VERSION "j1939-2025-03-v2.4-light"

NS_ :

BS_:

BU_:

BO_ 2561146622 AUXIO2: 8 Vector__XXX
 SG_ AuxiliaryIO17 : 6|2@1+ (1,0) [0|3] "" Vector__XXX
 SG_ AuxiliaryIO18 : 4|2@1+ (1,0) [0|3] "" Vector__XXX
 SG_ AuxiliaryIO19 : 2|2@1+ (1,0) [0|3] "" Vector__XXX
 SG_ AuxiliaryIO20 : 0|2@1+ (1,0) [0|3] "" Vector__XXX
 SG_ AuxiliaryIO21 : 14|2@1+ (1,0) [0|3] "" Vector__XXX
 SG_ AuxiliaryIO22 : 12|2@1+ (1,0) [0|3] "" Vector__XXX
 SG_ AuxiliaryIO23 : 10|2@1+ (1,0) [0|3] "" Vector__XXX
 SG_ AuxiliaryIO24 : 8|2@1+ (1,0) [0|3] "" Vector__XXX
 SG_ AuxiliaryIO25 : 22|2@1+ (1,0) [0|3] "" Vector__XXX
 SG_ AuxiliaryIO26 : 20|2@1+ (1,0) [0|3] "" Vector__XXX
 SG_ AuxiliaryIO27 : 18|2@1+ (1,0) [0|3] "" Vector__XXX
 SG_ AuxiliaryIO28 : 16|2@1+ (1,0) [0|3] "" Vector__XXX
 SG_ AuxiliaryIO29 : 30|2@1+ (1,0) [0|3] "" Vector__XXX
 SG_ AuxiliaryIO30 : 28|2@1+ (1,0) [0|3] "" Vector__XXX
 SG_ AuxiliaryIO31 : 26|2@1+ (1,0) [0|3] "" Vector__XXX
 SG_ AuxiliaryIO32 : 24|2@1+ (1,0) [0|3] "" Vector__XXX
 SG_ AuxiliaryIO33 : 38|2@1+ (1,0) [0|3] "" Vector__XXX
 SG_ AuxiliaryIO34 : 36|2@1+ (1,0) [0|3] "" Vector__XXX
 SG_ AuxiliaryIO35 : 34|2@1+ (1,0) [0|3] "" Vector__XXX
 SG_ AuxiliaryIO36 : 32|2@1+ (1,0) [0|3] "" Vector__XXX
 SG_ AuxiliaryIO37 : 46|2@1+ (1,0) [0|3] "" Vector__XXX
 SG_ AuxiliaryIO38 : 44|2@1+ (1,0) [0|3] "" Vector__XXX
 SG_ AuxiliaryIO39 : 42|2@1+ (1,0) [0|3] "" Vector__XXX
 SG_ AuxiliaryIO40 : 40|2@1+ (1,0) [0|3] "" Vector__XXX
 SG_ AuxiliaryIO41 : 54|2@1+ (1,0) [0|3] "" Vector__XXX
 SG_ AuxiliaryIO42 : 52|2@1+ (1,0) [0|3] "" Vector__XXX
 SG_ AuxiliaryIO43 : 50|2@1+ (1,0) [0|3] "" Vector__XXX
 SG_ AuxiliaryIO44 : 48|2@1+ (1,0) [0|3] "" Vector__XXX
 SG_ AuxiliaryIO45 : 62|2@1+ (1,0) [0|3] "" Vector__XXX
 SG_ AuxiliaryIO46 : 60|2@1+ (1,0) [0|3] "" Vector__XXX
 SG_ AuxiliaryIO47 : 58|2@1+ (1,0) [0|3] "" Vector__XXX
 SG_ AuxiliaryIO48 : 56|2@1+ (1,0) [0|3] "" Vector__XXX

BO_ 2561212158 DISP1: 8 Vector__XXX
 SG_ TextDisplayIndex : 16|8@1+ (1,0) [0|200] "count" Vector__XXX
 SG_ TextDisplayInstructions : 0|4@1+ (1,0) [0|15] "" Vector__XXX

BO_ 2561277694 FLIC: 8 Vector__XXX
 SG_ CurrentRegion : 8|16@1+ (1,0) [0|255] "" Vector__XXX
 SG_ CurrentSubRegion : 24|24@1+ (1,0) [0|255] "" Vector__XXX
 SG_ LnDprtrWrnngEnlCmmnd : 0|2@1+ (1,0) [0|3] "" Vector__XXX
 SG_ LaneKeepingAssistEnableCommand : 2|2@1+ (1,0) [0|3] "" Vector__XXX
 SG_ LaneCenteringEnableCommand : 4|2@1+ (1,0) [0|3] "" Vector__XXX
 SG_ RqstdAtvStrngDrvrPrfrnMd : 48|3@1+ (1,0) [0|7] "" Vector__XXX

BO_ 2561605374 TPRS: 8 Vector__XXX
 SG_ ReferenceTirePressureSetting : 8|8@1+ (8,0) [0|2000] "kPa" Vector__XXX
 SG_ TireLocation : 0|8@1+ (1,0) [0|250] "" Vector__XXX

BO_ 2563768062 CTL: 8 Vector__XXX
 SG_ EngnSpdLmtRqstMnmmCntns : 0|8@1+ (32,0) [0|8000] "rpm" Vector__XXX
 SG_ EngnSpdLmtRqstMxmmCntns : 8|8@1+ (32,0) [0|8000] "rpm" Vector__XXX
 SG_ EngnTrqLmtRqstMnmmCntns : 16|8@1+ (1,-125) [0|125] "%" Vector__XXX
 SG_ EngnTrqLmtRqstMxmmCntns : 24|8@1+ (1,-125) [0|125] "%" Vector__XXX
 SG_ MnmmCntnsRtrdrSpdLmtRqst : 32|8@1+ (32,0) [0|8000] "rpm" Vector__XXX
 SG_ MnmmCntnsRtrdrTrqLmtRqst : 48|8@1+ (1,-125) [-125|0] "%" Vector__XXX
 SG_ MxmmCntnsRtrdrSpdLmtRqst : 40|8@1+ (32,0) [0|8000] "rpm" Vector__XXX
 SG_ MxmmCntnsRtrdrTrqLmtRqst : 56|8@1+ (1,-125) [-125|0] "%" Vector__XXX

BO_ 2563833598 CL: 8 Vector__XXX
 SG_ IlluminationBrightnessPercent : 0|8@1+ (0.4,0) [0|100] "%" Vector__XXX
 SG_ SwthBklghtIllmntnBrghtnssPrnt : 8|8@1+ (0.4,0) [0|100] "%" Vector__XXX
 SG_ SwthIndtnIllmntnBrghtnssPrnt : 16|8@1+ (0.4,0) [0|100] "%" Vector__XXX
 SG_ OprtrDsrdDsplMdCmmnd1 : 24|4@1+ (1,0) [0|15] "" Vector__XXX
 SG_ OprtrDsrdDsplMdCmmnd2 : 28|4@1+ (1,0) [0|15] "" Vector__XXX
 SG_ CabDomeLight1Command : 32|8@1+ (0.4,0) [0|100] "%" Vector__XXX
 SG_ CabDomeLight2Command : 40|8@1+ (0.4,0) [0|100] "%" Vector__XXX

BO_ 2564161278 TDA: 8 Vector__XXX
 SG_ AdjustDay : 32|8@1+ (0.25,0) [0.25|31.75] "days" Vector__XXX
 SG_ AdjustHours : 16|8@1+ (1,0) [0|23] "h" Vector__XXX
 SG_ AdjustLocalHourOffset : 56|8@1+ (1,-125) [-24|23] "h" Vector__XXX
 SG_ AdjustLocalMinuteOffset : 48|8@1+ (1,-125) [-59|59] "min" Vector__XXX
 SG_ AdjustMinutes : 8|8@1+ (1,0) [0|59] "min" Vector__XXX
 SG_ AdjustMonth : 24|8@1+ (1,0) [1|12] "month" Vector__XXX
 SG_ AdjustSeconds : 0|8@1+ (0.25,0) [0|59.75] "s" Vector__XXX
 SG_ AdjustYear : 40|8@1+ (1,1985) [1985|2235] "year" Vector__XXX

BO_ 2564882174 CM1: 8 Vector__XXX
 SG_ AftrtrtmntRgnrtnFrSwth : 42|2@1+ (1,0) [0|3] "" Vector__XXX
 SG_ AftrtrtmntRgnrtnInhtSwth : 40|2@1+ (1,0) [0|3] "" Vector__XXX
 SG_ AtmtGrShftngEnlSwth : 44|2@1+ (1,0) [0|3] "" Vector__XXX
 SG_ AuxiliaryHeaterModeRequest : 48|4@1+ (1,0) [0|15] "" Vector__XXX
 SG_ AxlrHtrClntPmpRqst : 24|2@1+ (1,0) [0|3] "" Vector__XXX
 SG_ BatteryMainSwitchHoldRequest : 26|2@1+ (1,0) [0|3] "" Vector__XXX
 SG_ CabInteriorTemperatureCommand : 8|16@1+ (0.03125,-273) [-273|1734.96875] "degC" Vector__XXX
 SG_ EngineFan1RequestedPercentSpeed : 0|8@1+ (0.4,0) [0|100] "%" Vector__XXX
 SG_ EngnAtmtStrtEnlSwth : 46|2@1+ (1,0) [0|3] "" Vector__XXX
 SG_ OperatorSeatDirectionSwitch : 28|2@1+ (1,0) [0|3] "" Vector__XXX
 SG_ ParkBrakeCommand : 32|2@1+ (1,0) [0|3] "" Vector__XXX
 SG_ RequestCabZoneHeating : 54|2@1+ (1,0) [0|3] "" Vector__XXX
 SG_ RequestEngineZoneHeating : 52|2@1+ (1,0) [0|3] "" Vector__XXX
 SG_ SeatBeltSwitch : 30|2@1+ (1,0) [0|3] "" Vector__XXX
 SG_ SltdMxmmVhlSpdLmt : 56|8@1+ (1,0) [0|250] "count" Vector__XXX
 SG_ VhlLmtngSpdGvrnrDrmntSwth : 34|2@1+ (1,0) [0|3] "" Vector__XXX
 SG_ VhlLmtngSpdGvrnrEnlSwth : 38|2@1+ (1,0) [0|3] "" Vector__XXX
 SG_ VhlLmtngSpdGvrnrInrmntSwth : 36|2@1+ (1,0) [0|3] "" Vector__XXX

BO_ 2565865982 EBC1: 8 Vector__XXX
 SG_ AbsFullyOperational : 40|2@1+ (1,0) [0|3] "" Vector__XXX
 SG_ AbsOffRoadSwitch : 16|2@1+ (1,0) [0|3] "" Vector__XXX
 SG_ AcceleratorInterlockSwitch : 24|2@1+ (1,0) [0|3] "" Vector__XXX
 SG_ AntiLockBrakingAbsActive : 4|2@1+ (1,0) [0|3] "" Vector__XXX
 SG_ AsrBrakeControlActive : 2|2@1+ (1,0) [0|3] "" Vector__XXX
 SG_ AsrEngineControlActive : 0|2@1+ (1,0) [0|3] "" Vector__XXX
 SG_ AsrHillHolderSwitch : 20|2@1+ (1,0) [0|3] "" Vector__XXX
 SG_ AsrOffRoadSwitch : 18|2@1+ (1,0) [0|3] "" Vector__XXX
 SG_ AtcAsrInformationSignal : 46|2@1+ (1,0) [0|3] "" Vector__XXX
 SG_ BrakePedalPosition : 8|8@1+ (0.4,0) [0|100] "%" Vector__XXX
 SG_ EbsBrakeSwitch : 6|2@1+ (1,0) [0|3] "" Vector__XXX
 SG_ EbsRedWarningSignal : 42|2@1+ (1,0) [0|3] "" Vector__XXX
 SG_ EngineAuxiliaryShutdownSwitch : 28|2@1+ (1,0) [0|3] "" Vector__XXX
 SG_ EngineDerateSwitch : 26|2@1+ (1,0) [0|3] "" Vector__XXX
 SG_ EngineRetarderSelection : 32|8@1+ (0.4,0) [0|100] "%" Vector__XXX
 SG_ HaltBrakeSwitch : 58|2@1+ (1,0) [0|3] "" Vector__XXX
 SG_ RailroadModeSwitch : 56|2@1+ (1,0) [0|3] "" Vector__XXX
 SG_ RemoteAcceleratorEnableSwitch : 30|2@1+ (1,0) [0|3] "" Vector__XXX
 SG_ TractionControlOverrideSwitch : 22|2@1+ (1,0) [0|3] "" Vector__XXX
 SG_ TrailerAbsStatus : 60|2@1+ (1,0) [0|3] "" Vector__XXX
 SG_ AsEsAmrWrnngSgnlPwrdVhl : 44|2@1+ (1,0) [0|3] "" Vector__XXX
 SG_ SrAddrssOfCntrllngDvFrBrkCntrl : 48|8@1+ (1,0) [0|253] "sourceadr" Vector__XXX
 SG_ TrtrMntdTrlrAsWrnngSgnl : 62|2@1+ (1,0) [0|3] "" Vector__XXX

BO_ 2565867006 ETC2: 8 Vector__XXX
 SG_ TransmissionActualGearRatio : 8|16@1+ (0.001,0) [0|64.255] "" Vector__XXX
 SG_ TransmissionCurrentGear : 24|8@1+ (1,-125) [-125|125] "gear value" Vector__XXX
 SG_ TransmissionCurrentRange : 48|16@1+ (1,0) [0|255] "" Vector__XXX
 SG_ TransmissionRequestedRange : 32|16@1+ (1,0) [0|255] "" Vector__XXX
 SG_ TransmissionSelectedGear : 0|8@1+ (1,-125) [-125|125] "gear value" Vector__XXX

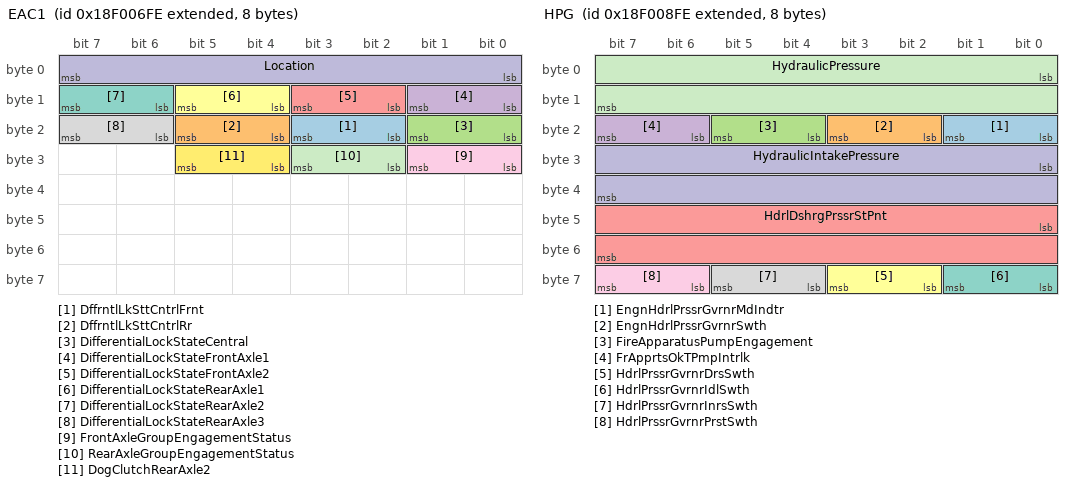
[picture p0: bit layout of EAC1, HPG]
BO_ 2565867262 EAC1: 8 Vector__XXX
 SG_ DffrntlLkSttCntrlFrnt : 18|2@1+ (1,0) [0|3] "" Vector__XXX
 SG_ DffrntlLkSttCntrlRr : 20|2@1+ (1,0) [0|3] "" Vector__XXX
 SG_ DifferentialLockStateCentral : 16|2@1+ (1,0) [0|3] "" Vector__XXX
 SG_ DifferentialLockStateFrontAxle1 : 8|2@1+ (1,0) [0|3] "" Vector__XXX
 SG_ DifferentialLockStateFrontAxle2 : 10|2@1+ (1,0) [0|3] "" Vector__XXX
 SG_ DifferentialLockStateRearAxle1 : 12|2@1+ (1,0) [0|3] "" Vector__XXX
 SG_ DifferentialLockStateRearAxle2 : 14|2@1+ (1,0) [0|3] "" Vector__XXX
 SG_ DifferentialLockStateRearAxle3 : 22|2@1+ (1,0) [0|3] "" Vector__XXX
 SG_ FrontAxleGroupEngagementStatus : 24|2@1+ (1,0) [0|3] "" Vector__XXX
 SG_ Location : 0|8@1+ (1,0) [0|250] "" Vector__XXX
 SG_ RearAxleGroupEngagementStatus : 26|2@1+ (1,0) [0|3] "" Vector__XXX
 SG_ DogClutchRearAxle2 : 28|2@1+ (1,0) [0|3] "" Vector__XXX

BO_ 2565867774 HPG: 8 Vector__XXX
 SG_ EngnHdrlPrssrGvrnrMdIndtr : 16|2@1+ (1,0) [0|3] "" Vector__XXX
 SG_ EngnHdrlPrssrGvrnrSwth : 18|2@1+ (1,0) [0|3] "" Vector__XXX
 SG_ FireApparatusPumpEngagement : 20|2@1+ (1,0) [0|3] "" Vector__XXX
 SG_ FrApprtsOkTPmpIntrlk : 22|2@1+ (1,0) [0|3] "" Vector__XXX
 SG_ HdrlDshrgPrssrStPnt : 40|16@1+ (2,0) [0|128510] "kPa" Vector__XXX
 SG_ HdrlPrssrGvrnrDrsSwth : 58|2@1+ (1,0) [0|3] "" Vector__XXX
 SG_ HdrlPrssrGvrnrIdlSwth : 56|2@1+ (1,0) [0|3] "" Vector__XXX
 SG_ HdrlPrssrGvrnrInrsSwth : 60|2@1+ (1,0) [0|3] "" Vector__XXX
 SG_ HdrlPrssrGvrnrPrstSwth : 62|2@1+ (1,0) [0|3] "" Vector__XXX
 SG_ HydraulicIntakePressure : 24|16@1+ (0.0001220703125,-1) [-1|6.8436279296875] "MPa" Vector__XXX
 SG_ HydraulicPressure : 0|16@1+ (2,0) [0|128510] "kPa" Vector__XXX

BO_ 2565868030 VDC2: 8 Vector__XXX
 SG_ LateralAcceleration : 40|16@1+ (0.00048828125,-15.687) [-15.687|15.68751171875] "m/(s*s)" Vector__XXX
 SG_ LongitudinalAcceleration : 56|8@1+ (0.1,-12.5) [-12.5|12.5] "m/(s*s)" Vector__XXX
 SG_ SteeringWheelAngle : 0|16@1+ (0.0009765625,-31.374) [-31.374|31.3750234375] "rad" Vector__XXX
 SG_ SteeringWheelAngleSensorType : 22|2@1+ (1,0) [0|3] "" Vector__XXX
 SG_ SteeringWheelTurnCounter : 16|6@1+ (1,-32) [-10|10] "turn" Vector__XXX
 SG_ YawRate : 24|16@1+ (0.0001220703125,-3.92) [-3.92|3.9236279296875] "rad/s" Vector__XXX

BO_ 2565868542 ESC1: 8 Vector__XXX
 SG_ ActualInnerWheelSteeringAngle : 0|16@1+ (0.00390625,-125) [-125|125.99609375] "deg" Vector__XXX
 SG_ AxleLocation : 16|8@1+ (1,0) [0|250] "" Vector__XXX
 SG_ StatusOfSteeringAxle : 24|4@1+ (1,0) [0|15] "" Vector__XXX
 SG_ SteeringType : 32|4@1+ (1,0) [0|15] "" Vector__XXX
 SG_ StrlLftAxlLwrngInht : 28|2@1+ (1,0) [0|3] "" Vector__XXX
 SG_ TypeOfSteeringForces : 36|4@1+ (1,0) [0|15] "" Vector__XXX
 SG_ TypeOfSteeringTransmission : 40|4@1+ (1,0) [0|15] "" Vector__XXX

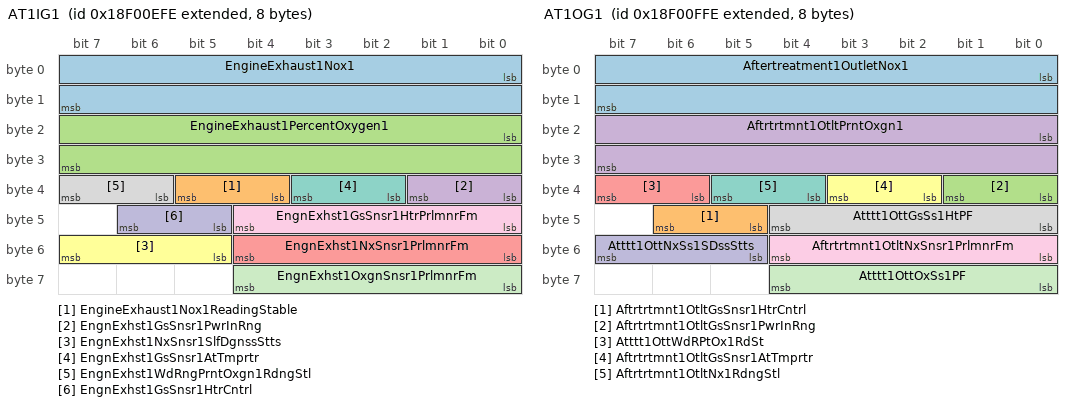
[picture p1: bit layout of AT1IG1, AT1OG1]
BO_ 2565869310 AT1IG1: 8 Vector__XXX
 SG_ EngineExhaust1Nox1 : 0|16@1+ (0.05,-200) [-200|3012.75] "ppm" Vector__XXX
 SG_ EngineExhaust1Nox1ReadingStable : 36|2@1+ (1,0) [0|3] "" Vector__XXX
 SG_ EngineExhaust1PercentOxygen1 : 16|16@1+ (0.000514,-12) [-12|21.02707] "%" Vector__XXX
 SG_ EngnExhst1GsSnsr1PwrInRng : 32|2@1+ (1,0) [0|3] "" Vector__XXX
 SG_ EngnExhst1NxSnsr1PrlmnrFm : 48|5@1+ (1,0) [0|31] "" Vector__XXX
 SG_ EngnExhst1NxSnsr1SlfDgnssStts : 53|3@1+ (1,0) [0|7] "" Vector__XXX
 SG_ EngnExhst1GsSnsr1AtTmprtr : 34|2@1+ (1,0) [0|3] "" Vector__XXX
 SG_ EngnExhst1WdRngPrntOxgn1RdngStl : 38|2@1+ (1,0) [0|3] "" Vector__XXX
 SG_ EngnExhst1GsSnsr1HtrPrlmnrFm : 40|5@1+ (1,0) [0|31] "" Vector__XXX
 SG_ EngnExhst1GsSnsr1HtrCntrl : 45|2@1+ (1,0) [0|3] "" Vector__XXX
 SG_ EngnExhst1OxgnSnsr1PrlmnrFm : 56|5@1+ (1,0) [0|31] "" Vector__XXX

BO_ 2565869566 AT1OG1: 8 Vector__XXX
 SG_ Aftertreatment1OutletNox1 : 0|16@1+ (0.05,-200) [-200|3012.75] "ppm" Vector__XXX
 SG_ Aftrtrtmnt1OtltGsSnsr1HtrCntrl : 45|2@1+ (1,0) [0|3] "" Vector__XXX
 SG_ Aftrtrtmnt1OtltGsSnsr1PwrInRng : 32|2@1+ (1,0) [0|3] "" Vector__XXX
 SG_ Aftrtrtmnt1OtltPrntOxgn1 : 16|16@1+ (0.000514,-12) [-12|21.02707] "%" Vector__XXX
 SG_ Atttt1OttWdRPtOx1RdSt : 38|2@1+ (1,0) [0|3] "" Vector__XXX
 SG_ Aftrtrtmnt1OtltGsSnsr1AtTmprtr : 34|2@1+ (1,0) [0|3] "" Vector__XXX
 SG_ Aftrtrtmnt1OtltNx1RdngStl : 36|2@1+ (1,0) [0|3] "" Vector__XXX
 SG_ Atttt1OttGsSs1HtPF : 40|5@1+ (1,0) [0|31] "" Vector__XXX
 SG_ Aftrtrtmnt1OtltNxSnsr1PrlmnrFm : 48|5@1+ (1,0) [0|31] "" Vector__XXX
 SG_ Atttt1OttNxSs1SDssStts : 53|3@1+ (1,0) [0|7] "" Vector__XXX
 SG_ Atttt1OttOxSs1PF : 56|5@1+ (1,0) [0|31] "" Vector__XXX

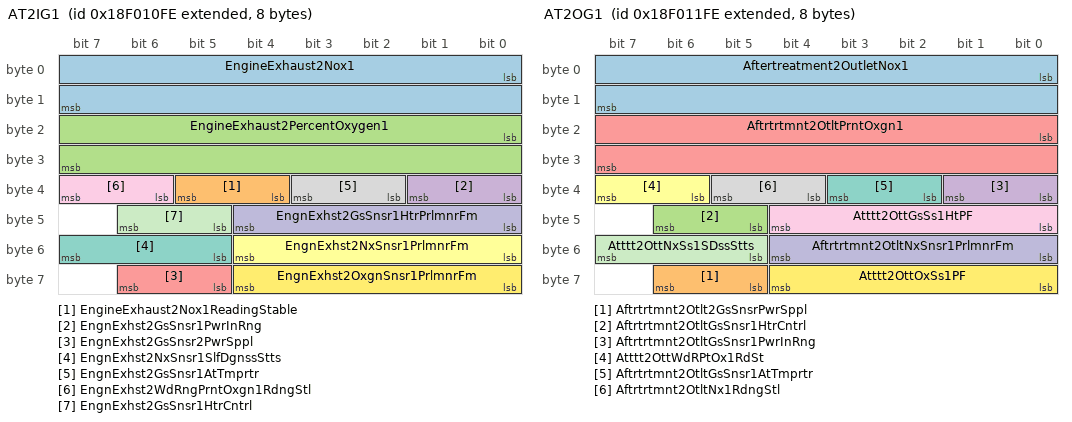
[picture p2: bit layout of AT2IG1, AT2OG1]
BO_ 2565869822 AT2IG1: 8 Vector__XXX
 SG_ EngineExhaust2Nox1 : 0|16@1+ (0.05,-200) [-200|3012.75] "ppm" Vector__XXX
 SG_ EngineExhaust2Nox1ReadingStable : 36|2@1+ (1,0) [0|3] "" Vector__XXX
 SG_ EngineExhaust2PercentOxygen1 : 16|16@1+ (0.000514,-12) [-12|21.02707] "%" Vector__XXX
 SG_ EngnExhst2GsSnsr1PwrInRng : 32|2@1+ (1,0) [0|3] "" Vector__XXX
 SG_ EngnExhst2GsSnsr2PwrSppl : 61|2@1+ (1,0) [0|3] "" Vector__XXX
 SG_ EngnExhst2NxSnsr1PrlmnrFm : 48|5@1+ (1,0) [0|31] "" Vector__XXX
 SG_ EngnExhst2NxSnsr1SlfDgnssStts : 53|3@1+ (1,0) [0|7] "" Vector__XXX
 SG_ EngnExhst2GsSnsr1AtTmprtr : 34|2@1+ (1,0) [0|3] "" Vector__XXX
 SG_ EngnExhst2WdRngPrntOxgn1RdngStl : 38|2@1+ (1,0) [0|3] "" Vector__XXX
 SG_ EngnExhst2GsSnsr1HtrPrlmnrFm : 40|5@1+ (1,0) [0|31] "" Vector__XXX
 SG_ EngnExhst2GsSnsr1HtrCntrl : 45|2@1+ (1,0) [0|3] "" Vector__XXX
 SG_ EngnExhst2OxgnSnsr1PrlmnrFm : 56|5@1+ (1,0) [0|31] "" Vector__XXX

BO_ 2565870078 AT2OG1: 8 Vector__XXX
 SG_ Aftertreatment2OutletNox1 : 0|16@1+ (0.05,-200) [-200|3012.75] "ppm" Vector__XXX
 SG_ Aftrtrtmnt2Otlt2GsSnsrPwrSppl : 61|2@1+ (1,0) [0|3] "" Vector__XXX
 SG_ Aftrtrtmnt2OtltGsSnsr1HtrCntrl : 45|2@1+ (1,0) [0|3] "" Vector__XXX
 SG_ Aftrtrtmnt2OtltGsSnsr1PwrInRng : 32|2@1+ (1,0) [0|3] "" Vector__XXX
 SG_ Aftrtrtmnt2OtltPrntOxgn1 : 16|16@1+ (0.000514,-12) [-12|21.02707] "%" Vector__XXX
 SG_ Atttt2OttWdRPtOx1RdSt : 38|2@1+ (1,0) [0|3] "" Vector__XXX
 SG_ Aftrtrtmnt2OtltGsSnsr1AtTmprtr : 34|2@1+ (1,0) [0|3] "" Vector__XXX
 SG_ Aftrtrtmnt2OtltNx1RdngStl : 36|2@1+ (1,0) [0|3] "" Vector__XXX
 SG_ Atttt2OttGsSs1HtPF : 40|5@1+ (1,0) [0|31] "" Vector__XXX
 SG_ Aftrtrtmnt2OtltNxSnsr1PrlmnrFm : 48|5@1+ (1,0) [0|31] "" Vector__XXX
 SG_ Atttt2OttNxSs1SDssStts : 53|3@1+ (1,0) [0|7] "" Vector__XXX
 SG_ Atttt2OttOxSs1PF : 56|5@1+ (1,0) [0|31] "" Vector__XXX

BO_ 2565870334 FWSS1: 8 Vector__XXX
 SG_ FifthWheelDrawbarForce : 16|16@1+ (10,-320000) [-320000|322550] "N" Vector__XXX
 SG_ FifthWheelRollMoment : 32|16@1+ (10,-320000) [-320000|322550] "N" Vector__XXX
 SG_ FifthWheelRollWarningIndicator : 48|2@1+ (1,0) [0|3] "" Vector__XXX
 SG_ FifthWheelVerticalForce : 0|16@1+ (5,0) [0|321275] "N" Vector__XXX

BO_ 2565873150 SAS: 8 Vector__XXX
 SG_ MessageChecksum : 60|4@1+ (1,0) [0|15] "count" Vector__XXX
 SG_ MessageCounter : 56|4@1+ (1,0) [0|15] "count" Vector__XXX
 SG_ SteeringAngleSensorActiveMode : 48|2@1+ (1,0) [0|3] "" Vector__XXX
 SG_ SteeringAngleSensorCalibrated : 50|2@1+ (1,0) [0|3] "" Vector__XXX
 SG_ SteeringWheelAngle : 0|16@1+ (0.0009765625,-31.374) [-31.374|31.3750234375] "rad" Vector__XXX
 SG_ SteeringWheelAngleRange : 32|16@1+ (0.0009765625,-31.374) [0|31.374] "rad" Vector__XXX
 SG_ SteeringWheelAngleRangeCounter : 16|6@1+ (1,-32) [-32|29] "range" Vector__XXX
 SG_ StrngWhlAnglRngCntrTp : 22|2@1+ (1,0) [0|3] "" Vector__XXX

BO_ 2565874174 ESSI1: 8 Vector__XXX
 SG_ EngineSpeed1 : 0|16@1+ (0.5,0) [0|32127.5] "rpm" Vector__XXX
 SG_ EngineSpeed2 : 16|16@1+ (0.5,0) [0|32127.5] "rpm" Vector__XXX
 SG_ EngineSpeed3 : 32|16@1+ (0.5,0) [0|32127.5] "rpm" Vector__XXX
 SG_ EngnSpdSnsr1TmngPttrnStts : 54|2@1+ (1,0) [0|3] "" Vector__XXX
 SG_ EngnSpdSnsr2TmngPttrnStts : 52|2@1+ (1,0) [0|3] "" Vector__XXX
 SG_ EngnSpdSnsr3TmngPttrnStts : 50|2@1+ (1,0) [0|3] "" Vector__XXX

BO_ 2565877502 ETCC1: 8 Vector__XXX
 SG_ EExstB1PssRtCtCd : 32|16@1+ (0.0025,0) [0|100] "%" Vector__XXX
 SG_ EngnTrhrgrWstgtAttr1Cmmnd : 0|16@1+ (0.0025,0) [0|160.6375] "%" Vector__XXX
 SG_ EngnTrhrgrWstgtAttr2Cmmnd : 16|16@1+ (0.0025,0) [0|160.6375] "%" Vector__XXX
 SG_ ETCpssBwAtt1Cd : 48|16@1+ (0.0025,0) [0|100] "%" Vector__XXX

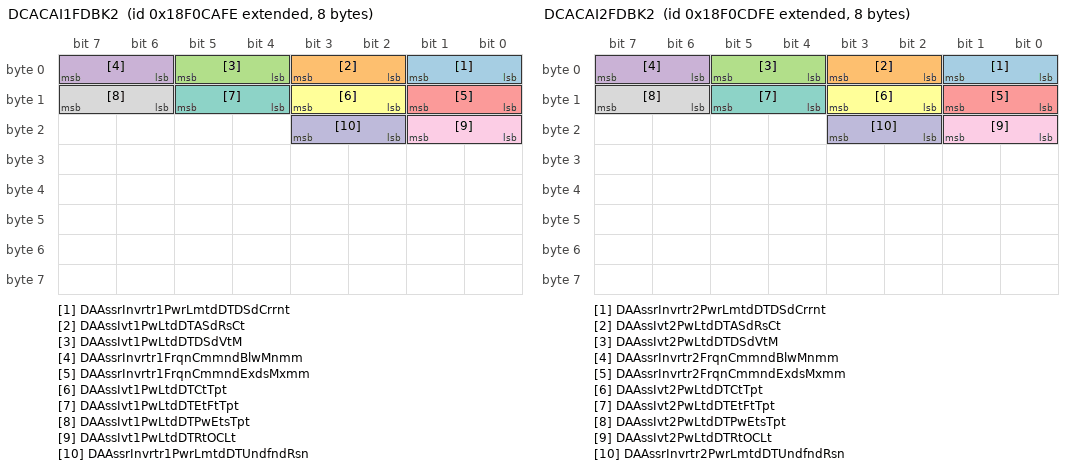
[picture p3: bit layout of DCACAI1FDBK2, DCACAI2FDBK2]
BO_ 2565917438 DCACAI1FDBK2: 8 Vector__XXX
 SG_ DAAssrInvrtr1PwrLmtdDTDSdCrrnt : 0|2@1+ (1,0) [0|3] "" Vector__XXX
 SG_ DAAssIvt1PwLtdDTASdRsCt : 2|2@1+ (1,0) [0|3] "" Vector__XXX
 SG_ DAAssIvt1PwLtdDTDSdVtM : 4|2@1+ (1,0) [0|3] "" Vector__XXX
 SG_ DAAssrInvrtr1FrqnCmmndBlwMnmm : 6|2@1+ (1,0) [0|3] "" Vector__XXX
 SG_ DAAssrInvrtr1FrqnCmmndExdsMxmm : 8|2@1+ (1,0) [0|3] "" Vector__XXX
 SG_ DAAssIvt1PwLtdDTCtTpt : 10|2@1+ (1,0) [0|3] "" Vector__XXX
 SG_ DAAssIvt1PwLtdDTEtFtTpt : 12|2@1+ (1,0) [0|3] "" Vector__XXX
 SG_ DAAssIvt1PwLtdDTPwEtsTpt : 14|2@1+ (1,0) [0|3] "" Vector__XXX
 SG_ DAAssIvt1PwLtdDTRtOCLt : 16|2@1+ (1,0) [0|3] "" Vector__XXX
 SG_ DAAssrInvrtr1PwrLmtdDTUndfndRsn : 18|2@1+ (1,0) [0|3] "" Vector__XXX

BO_ 2565918206 DCACAI2FDBK2: 8 Vector__XXX
 SG_ DAAssrInvrtr2PwrLmtdDTDSdCrrnt : 0|2@1+ (1,0) [0|3] "" Vector__XXX
 SG_ DAAssIvt2PwLtdDTASdRsCt : 2|2@1+ (1,0) [0|3] "" Vector__XXX
 SG_ DAAssIvt2PwLtdDTDSdVtM : 4|2@1+ (1,0) [0|3] "" Vector__XXX
 SG_ DAAssrInvrtr2FrqnCmmndBlwMnmm : 6|2@1+ (1,0) [0|3] "" Vector__XXX
 SG_ DAAssrInvrtr2FrqnCmmndExdsMxmm : 8|2@1+ (1,0) [0|3] "" Vector__XXX
 SG_ DAAssIvt2PwLtdDTCtTpt : 10|2@1+ (1,0) [0|3] "" Vector__XXX
 SG_ DAAssIvt2PwLtdDTEtFtTpt : 12|2@1+ (1,0) [0|3] "" Vector__XXX
 SG_ DAAssIvt2PwLtdDTPwEtsTpt : 14|2@1+ (1,0) [0|3] "" Vector__XXX
 SG_ DAAssIvt2PwLtdDTRtOCLt : 16|2@1+ (1,0) [0|3] "" Vector__XXX
 SG_ DAAssrInvrtr2PwrLmtdDTUndfndRsn : 18|2@1+ (1,0) [0|3] "" Vector__XXX

BO_ 2565920510 DCACAI1CMD: 8 Vector__XXX
 SG_ DAAssrInvrtr1DvMxmmFrqn : 0|8@1+ (1,0) [0|250] "Hz" Vector__XXX
 SG_ DAAssrInvrtr1DvMnmmFrqn : 8|8@1+ (1,0) [0|250] "Hz" Vector__XXX
 SG_ DAAssrInvrtr1DvRtdFrqn : 16|8@1+ (1,0) [0|250] "Hz" Vector__XXX
 SG_ DAAssrInvrtr1DvRtdRmsVltg : 24|8@1+ (2,0) [0|500] "V" Vector__XXX
 SG_ DAAssrInvrtr1DvFrqnRtOfChngLmt : 32|8@1+ (2,0) [0|500] "Hz/s" Vector__XXX
 SG_ DAAssrInvrtr1FrqnCmmnd : 40|8@1+ (1,0) [0|250] "Hz" Vector__XXX
 SG_ DAAssrInvrtr1Dv1Stts : 48|3@1+ (1,0) [0|7] "" Vector__XXX
 SG_ DAAssrInvrtr1Dv2Stts : 51|3@1+ (1,0) [0|7] "" Vector__XXX
 SG_ DAAssrInvrtr1OprtnlCmmnd : 54|2@1+ (1,0) [0|3] "" Vector__XXX
 SG_ DAAssIvt1ASdMtSttRsVtRqst : 56|8@1+ (2,0) [0|500] "V" Vector__XXX

BO_ 2565920766 DCACAI1FDBK: 8 Vector__XXX
 SG_ DcAcAccessoryInverter1Frequency : 0|8@1+ (1,0) [0|250] "Hz" Vector__XXX
 SG_ DAAssrInvrtr1ASdRmsVltg : 8|8@1+ (2,0) [0|500] "V" Vector__XXX
 SG_ DAAssrInvrtr1ASdPwr : 16|8@1+ (0.1,0) [0|25] "kW" Vector__XXX
 SG_ DAAssrInvrtr1ASdRmsCrrnt : 24|16@1+ (0.03125,0) [0|2007.96875] "A" Vector__XXX
 SG_ DAAssrInvrtr1OprtnlStts : 48|3@1+ (1,0) [0|7] "" Vector__XXX
 SG_ DAAssrInvrtr1LdshdRqst : 51|2@1+ (1,0) [0|3] "" Vector__XXX
 SG_ DAAssrInvrtr1HvlStts : 53|2@1+ (1,0) [0|3] "" Vector__XXX

BO_ 2565921534 DCACAI2CMD: 8 Vector__XXX
 SG_ DAAssrInvrtr2DvMxmmFrqn : 0|8@1+ (1,0) [0|250] "Hz" Vector__XXX
 SG_ DAAssrInvrtr2DvMnmmFrqn : 8|8@1+ (1,0) [0|250] "Hz" Vector__XXX
 SG_ DAAssrInvrtr2DvRtdFrqn : 16|8@1+ (1,0) [0|250] "Hz" Vector__XXX
 SG_ DAAssrInvrtr2DvRtdRmsVltg : 24|8@1+ (2,0) [0|500] "V" Vector__XXX
 SG_ DAAssrInvrtr2DvFrqnRtOfChngLmt : 32|8@1+ (2,0) [0|500] "Hz/s" Vector__XXX
 SG_ DAAssrInvrtr2FrqnCmmnd : 40|8@1+ (1,0) [0|250] "Hz" Vector__XXX
 SG_ DAAssrInvrtr2Dv1Stts : 48|3@1+ (1,0) [0|7] "" Vector__XXX
 SG_ DAAssrInvrtr2Dv2Stts : 51|3@1+ (1,0) [0|7] "" Vector__XXX
 SG_ DAAssrInvrtr2OprtnlCmmnd : 54|2@1+ (1,0) [0|3] "" Vector__XXX
 SG_ DAAssIvt2ASdMtSttRsVtRqst : 56|8@1+ (2,0) [0|500] "V" Vector__XXX

BO_ 2565921790 DCACAI2FDBK: 8 Vector__XXX
 SG_ DcAcAccessoryInverter2Frequency : 0|8@1+ (1,0) [0|250] "Hz" Vector__XXX
 SG_ DAAssrInvrtr2ASdRmsVltg : 8|8@1+ (2,0) [0|500] "V" Vector__XXX
 SG_ DAAssrInvrtr2ASdPwr : 16|8@1+ (0.1,0) [0|25] "kW" Vector__XXX
 SG_ DAAssrInvrtr2ASdRmsCrrnt : 24|16@1+ (0.03125,0) [0|2007.96875] "A" Vector__XXX
 SG_ DAAssrInvrtr2OprtnlStts : 48|3@1+ (1,0) [0|7] "" Vector__XXX
 SG_ DAAssrInvrtr2LdshdRqst : 51|2@1+ (1,0) [0|3] "" Vector__XXX
 SG_ DAAssrInvrtr2HvlStts : 53|2@1+ (1,0) [0|3] "" Vector__XXX

BO_ 2565922558 DCACAI3CMD: 8 Vector__XXX
 SG_ DAAssrInvrtr3DvMxmmFrqn : 0|8@1+ (1,0) [0|250] "Hz" Vector__XXX
 SG_ DAAssrInvrtr3DvMnmmFrqn : 8|8@1+ (1,0) [0|250] "Hz" Vector__XXX
 SG_ DAAssrInvrtr3DvRtdFrqn : 16|8@1+ (1,0) [0|250] "Hz" Vector__XXX
 SG_ DAAssrInvrtr3DvRtdRmsVltg : 24|8@1+ (2,0) [0|500] "V" Vector__XXX
 SG_ DAAssrInvrtr3DvFrqnRtOfChngLmt : 32|8@1+ (2,0) [0|500] "Hz/s" Vector__XXX
 SG_ DAAssrInvrtr3FrqnCmmnd : 40|8@1+ (1,0) [0|250] "Hz" Vector__XXX
 SG_ DAAssrInvrtr3Dv1Stts : 48|3@1+ (1,0) [0|7] "" Vector__XXX
 SG_ DAAssrInvrtr3Dv2Stts : 51|3@1+ (1,0) [0|7] "" Vector__XXX
 SG_ DAAssrInvrtr3OprtnlCmmnd : 54|2@1+ (1,0) [0|3] "" Vector__XXX
 SG_ DAAssIvt3ASdMtSttRsVtRqst : 56|8@1+ (2,0) [0|500] "V" Vector__XXX

BO_ 2565922814 DCACAI3FDBK: 8 Vector__XXX
 SG_ DcAcAccessoryInverter3Frequency : 0|8@1+ (1,0) [0|250] "Hz" Vector__XXX
 SG_ DAAssrInvrtr3ASdRmsVltg : 8|8@1+ (2,0) [0|500] "V" Vector__XXX
 SG_ DAAssrInvrtr3ASdPwr : 16|8@1+ (0.1,0) [0|25] "kW" Vector__XXX
 SG_ DAAssrInvrtr3ASdRmsCrrnt : 24|16@1+ (0.03125,0) [0|2007.96875] "A" Vector__XXX
 SG_ DAAssrInvrtr3OprtnlStts : 48|3@1+ (1,0) [0|7] "" Vector__XXX
 SG_ DAAssrInvrtr3LdshdRqst : 51|2@1+ (1,0) [0|3] "" Vector__XXX
 SG_ DAAssrInvrtr3HvlStts : 53|2@1+ (1,0) [0|3] "" Vector__XXX

BO_ 2565923582 DCACAI4CMD: 8 Vector__XXX
 SG_ DAAssrInvrtr4DvMxmmFrqn : 0|8@1+ (1,0) [0|250] "Hz" Vector__XXX
 SG_ DAAssrInvrtr4DvMnmmFrqn : 8|8@1+ (1,0) [0|250] "Hz" Vector__XXX
 SG_ DAAssrInvrtr4DvRtdFrqn : 16|8@1+ (1,0) [0|250] "Hz" Vector__XXX
 SG_ DAAssrInvrtr4DvRtdRmsVltg : 24|8@1+ (2,0) [0|500] "V" Vector__XXX
 SG_ DAAssrInvrtr4DvFrqnRtOfChngLmt : 32|8@1+ (2,0) [0|500] "Hz/s" Vector__XXX
 SG_ DAAssrInvrtr4FrqnCmmnd : 40|8@1+ (1,0) [0|250] "Hz" Vector__XXX
 SG_ DAAssrInvrtr4Dv1Stts : 48|3@1+ (1,0) [0|7] "" Vector__XXX
 SG_ DAAssrInvrtr4Dv2Stts : 51|3@1+ (1,0) [0|7] "" Vector__XXX
 SG_ DAAssrInvrtr4OprtnlCmmnd : 54|2@1+ (1,0) [0|3] "" Vector__XXX
 SG_ DAAssIvt4ASdMtSttRsVtRqst : 56|8@1+ (2,0) [0|500] "V" Vector__XXX

BO_ 2565923838 DCACAI4FDBK: 8 Vector__XXX
 SG_ DcAcAccessoryInverter4Frequency : 0|8@1+ (1,0) [0|250] "Hz" Vector__XXX
 SG_ DAAssrInvrtr4ASdRmsVltg : 8|8@1+ (2,0) [0|500] "V" Vector__XXX
 SG_ DAAssrInvrtr4ASdPwr : 16|8@1+ (0.1,0) [0|25] "kW" Vector__XXX
 SG_ DAAssrInvrtr4ASdRmsCrrnt : 24|16@1+ (0.03125,0) [0|2007.96875] "A" Vector__XXX
 SG_ DAAssrInvrtr4OprtnlStts : 48|3@1+ (1,0) [0|7] "" Vector__XXX
 SG_ DAAssrInvrtr4LdshdRqst : 51|2@1+ (1,0) [0|3] "" Vector__XXX
 SG_ DAAssrInvrtr4HvlStts : 53|2@1+ (1,0) [0|3] "" Vector__XXX

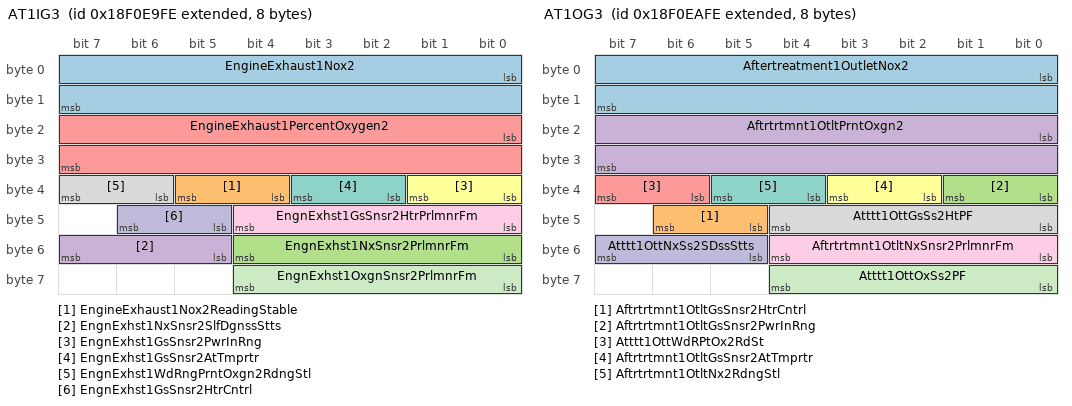
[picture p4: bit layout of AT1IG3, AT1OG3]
BO_ 2565925374 AT1IG3: 8 Vector__XXX
 SG_ EngineExhaust1Nox2 : 0|16@1+ (0.05,-200) [-200|3012.75] "ppm" Vector__XXX
 SG_ EngineExhaust1Nox2ReadingStable : 36|2@1+ (1,0) [0|3] "" Vector__XXX
 SG_ EngnExhst1NxSnsr2PrlmnrFm : 48|5@1+ (1,0) [0|31] "" Vector__XXX
 SG_ EngnExhst1NxSnsr2SlfDgnssStts : 53|3@1+ (1,0) [0|7] "" Vector__XXX
 SG_ EngineExhaust1PercentOxygen2 : 16|16@1+ (0.000514,-12) [-12|21.02707] "%" Vector__XXX
 SG_ EngnExhst1GsSnsr2PwrInRng : 32|2@1+ (1,0) [0|3] "" Vector__XXX
 SG_ EngnExhst1GsSnsr2AtTmprtr : 34|2@1+ (1,0) [0|3] "" Vector__XXX
 SG_ EngnExhst1WdRngPrntOxgn2RdngStl : 38|2@1+ (1,0) [0|3] "" Vector__XXX
 SG_ EngnExhst1GsSnsr2HtrPrlmnrFm : 40|5@1+ (1,0) [0|31] "" Vector__XXX
 SG_ EngnExhst1GsSnsr2HtrCntrl : 45|2@1+ (1,0) [0|3] "" Vector__XXX
 SG_ EngnExhst1OxgnSnsr2PrlmnrFm : 56|5@1+ (1,0) [0|31] "" Vector__XXX

BO_ 2565925630 AT1OG3: 8 Vector__XXX
 SG_ Aftertreatment1OutletNox2 : 0|16@1+ (0.05,-200) [-200|3012.75] "ppm" Vector__XXX
 SG_ Aftrtrtmnt1OtltGsSnsr2HtrCntrl : 45|2@1+ (1,0) [0|3] "" Vector__XXX
 SG_ Aftrtrtmnt1OtltGsSnsr2PwrInRng : 32|2@1+ (1,0) [0|3] "" Vector__XXX
 SG_ Aftrtrtmnt1OtltPrntOxgn2 : 16|16@1+ (0.000514,-12) [-12|21.02707] "%" Vector__XXX
 SG_ Atttt1OttWdRPtOx2RdSt : 38|2@1+ (1,0) [0|3] "" Vector__XXX
 SG_ Aftrtrtmnt1OtltGsSnsr2AtTmprtr : 34|2@1+ (1,0) [0|3] "" Vector__XXX
 SG_ Aftrtrtmnt1OtltNx2RdngStl : 36|2@1+ (1,0) [0|3] "" Vector__XXX
 SG_ Atttt1OttGsSs2HtPF : 40|5@1+ (1,0) [0|31] "" Vector__XXX
 SG_ Aftrtrtmnt1OtltNxSnsr2PrlmnrFm : 48|5@1+ (1,0) [0|31] "" Vector__XXX
 SG_ Atttt1OttNxSs2SDssStts : 53|3@1+ (1,0) [0|7] "" Vector__XXX
 SG_ Atttt1OttOxSs2PF : 56|5@1+ (1,0) [0|31] "" Vector__XXX

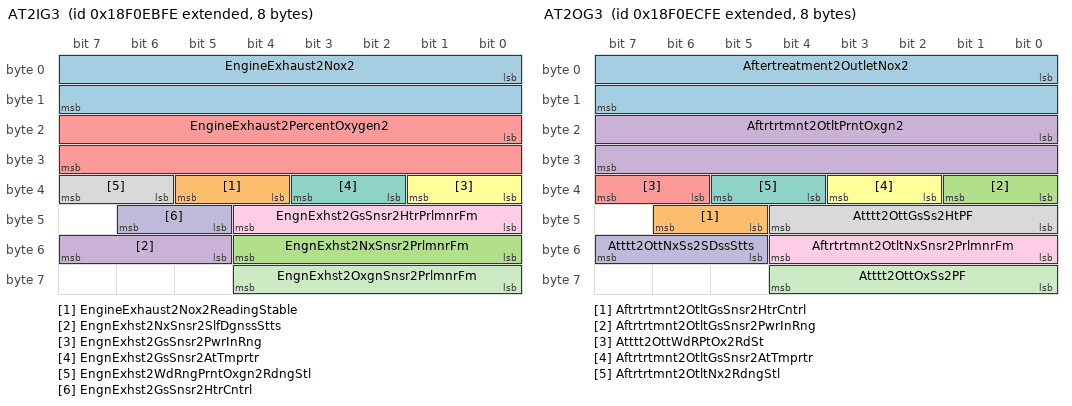
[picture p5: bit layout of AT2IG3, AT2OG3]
BO_ 2565925886 AT2IG3: 8 Vector__XXX
 SG_ EngineExhaust2Nox2 : 0|16@1+ (0.05,-200) [-200|3012.75] "ppm" Vector__XXX
 SG_ EngineExhaust2Nox2ReadingStable : 36|2@1+ (1,0) [0|3] "" Vector__XXX
 SG_ EngnExhst2NxSnsr2PrlmnrFm : 48|5@1+ (1,0) [0|31] "" Vector__XXX
 SG_ EngnExhst2NxSnsr2SlfDgnssStts : 53|3@1+ (1,0) [0|7] "" Vector__XXX
 SG_ EngineExhaust2PercentOxygen2 : 16|16@1+ (0.000514,-12) [-12|21.02707] "%" Vector__XXX
 SG_ EngnExhst2GsSnsr2PwrInRng : 32|2@1+ (1,0) [0|3] "" Vector__XXX
 SG_ EngnExhst2GsSnsr2AtTmprtr : 34|2@1+ (1,0) [0|3] "" Vector__XXX
 SG_ EngnExhst2WdRngPrntOxgn2RdngStl : 38|2@1+ (1,0) [0|3] "" Vector__XXX
 SG_ EngnExhst2GsSnsr2HtrPrlmnrFm : 40|5@1+ (1,0) [0|31] "" Vector__XXX
 SG_ EngnExhst2GsSnsr2HtrCntrl : 45|2@1+ (1,0) [0|3] "" Vector__XXX
 SG_ EngnExhst2OxgnSnsr2PrlmnrFm : 56|5@1+ (1,0) [0|31] "" Vector__XXX

BO_ 2565926142 AT2OG3: 8 Vector__XXX
 SG_ Aftertreatment2OutletNox2 : 0|16@1+ (0.05,-200) [-200|3012.75] "ppm" Vector__XXX
 SG_ Aftrtrtmnt2OtltGsSnsr2HtrCntrl : 45|2@1+ (1,0) [0|3] "" Vector__XXX
 SG_ Aftrtrtmnt2OtltGsSnsr2PwrInRng : 32|2@1+ (1,0) [0|3] "" Vector__XXX
 SG_ Aftrtrtmnt2OtltPrntOxgn2 : 16|16@1+ (0.000514,-12) [-12|21.02707] "%" Vector__XXX
 SG_ Atttt2OttWdRPtOx2RdSt : 38|2@1+ (1,0) [0|3] "" Vector__XXX
 SG_ Aftrtrtmnt2OtltGsSnsr2AtTmprtr : 34|2@1+ (1,0) [0|3] "" Vector__XXX
 SG_ Aftrtrtmnt2OtltNx2RdngStl : 36|2@1+ (1,0) [0|3] "" Vector__XXX
 SG_ Atttt2OttGsSs2HtPF : 40|5@1+ (1,0) [0|31] "" Vector__XXX
 SG_ Aftrtrtmnt2OtltNxSnsr2PrlmnrFm : 48|5@1+ (1,0) [0|31] "" Vector__XXX
 SG_ Atttt2OttNxSs2SDssStts : 53|3@1+ (1,0) [0|7] "" Vector__XXX
 SG_ Atttt2OttOxSs2PF : 56|5@1+ (1,0) [0|31] "" Vector__XXX

BO_ 2565932286 ESSI2: 8 Vector__XXX
 SG_ EngineSpeed4 : 0|16@1+ (0.5,0) [0|32127.5] "rpm" Vector__XXX

BO_ 2565932798 WSP1: 8 Vector__XXX
 SG_ WllStmltnPmpDshrgPrssr : 16|16@1+ (5,0) [0|321275] "kPa" Vector__XXX
 SG_ WllStmltnPmpStnPrssr : 0|16@1+ (0.1,-3212.7) [-3212.7|3212.8] "kPa" Vector__XXX

BO_ 2565933054 WSP2: 8 Vector__XXX
 SG_ WellStimulationPumpSpeed : 24|16@1+ (0.125,0) [0|8031.875] "rpm" Vector__XXX
 SG_ WllStmltnPmpGrBxOlPrssr : 0|16@1+ (0.1,0) [0|6425.5] "kPa" Vector__XXX
 SG_ WllStmltnPmpGrBxOlTmprtr : 16|8@1+ (1,-40) [-40|210] "degC" Vector__XXX
 SG_ WllStmltnPmpGrBxOtltOlTmprtr : 40|8@1+ (1,-40) [-40|210] "degC" Vector__XXX

BO_ 2565934590 GFI6: 8 Vector__XXX
 SG_ EngnFlVlv2DffrntlPrssr : 0|16@1+ (0.1,0) [0|6425.5] "kPa" Vector__XXX

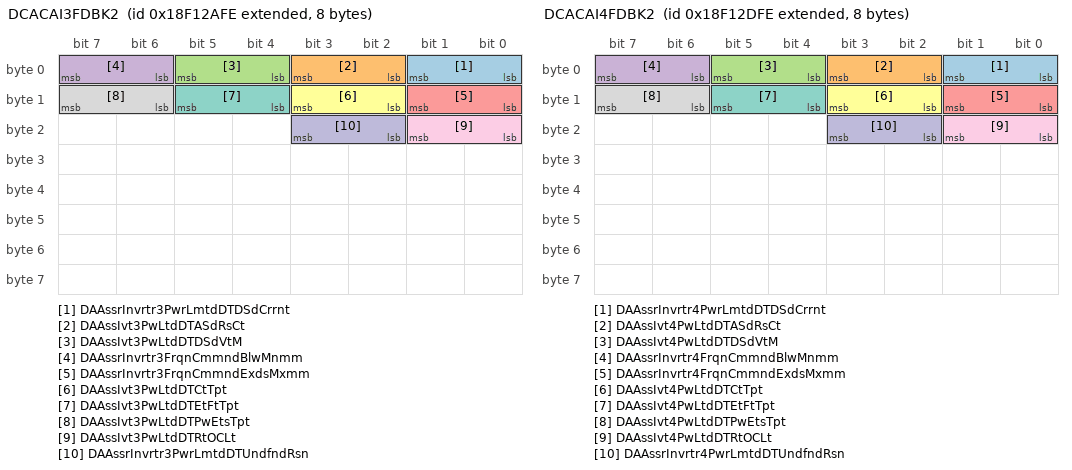
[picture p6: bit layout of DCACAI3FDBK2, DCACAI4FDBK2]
BO_ 2565942014 DCACAI3FDBK2: 8 Vector__XXX
 SG_ DAAssrInvrtr3PwrLmtdDTDSdCrrnt : 0|2@1+ (1,0) [0|3] "" Vector__XXX
 SG_ DAAssIvt3PwLtdDTASdRsCt : 2|2@1+ (1,0) [0|3] "" Vector__XXX
 SG_ DAAssIvt3PwLtdDTDSdVtM : 4|2@1+ (1,0) [0|3] "" Vector__XXX
 SG_ DAAssrInvrtr3FrqnCmmndBlwMnmm : 6|2@1+ (1,0) [0|3] "" Vector__XXX
 SG_ DAAssrInvrtr3FrqnCmmndExdsMxmm : 8|2@1+ (1,0) [0|3] "" Vector__XXX
 SG_ DAAssIvt3PwLtdDTCtTpt : 10|2@1+ (1,0) [0|3] "" Vector__XXX
 SG_ DAAssIvt3PwLtdDTEtFtTpt : 12|2@1+ (1,0) [0|3] "" Vector__XXX
 SG_ DAAssIvt3PwLtdDTPwEtsTpt : 14|2@1+ (1,0) [0|3] "" Vector__XXX
 SG_ DAAssIvt3PwLtdDTRtOCLt : 16|2@1+ (1,0) [0|3] "" Vector__XXX
 SG_ DAAssrInvrtr3PwrLmtdDTUndfndRsn : 18|2@1+ (1,0) [0|3] "" Vector__XXX

BO_ 2565942782 DCACAI4FDBK2: 8 Vector__XXX
 SG_ DAAssrInvrtr4PwrLmtdDTDSdCrrnt : 0|2@1+ (1,0) [0|3] "" Vector__XXX
 SG_ DAAssIvt4PwLtdDTASdRsCt : 2|2@1+ (1,0) [0|3] "" Vector__XXX
 SG_ DAAssIvt4PwLtdDTDSdVtM : 4|2@1+ (1,0) [0|3] "" Vector__XXX
 SG_ DAAssrInvrtr4FrqnCmmndBlwMnmm : 6|2@1+ (1,0) [0|3] "" Vector__XXX
 SG_ DAAssrInvrtr4FrqnCmmndExdsMxmm : 8|2@1+ (1,0) [0|3] "" Vector__XXX
 SG_ DAAssIvt4PwLtdDTCtTpt : 10|2@1+ (1,0) [0|3] "" Vector__XXX
 SG_ DAAssIvt4PwLtdDTEtFtTpt : 12|2@1+ (1,0) [0|3] "" Vector__XXX
 SG_ DAAssIvt4PwLtdDTPwEtsTpt : 14|2@1+ (1,0) [0|3] "" Vector__XXX
 SG_ DAAssIvt4PwLtdDTRtOCLt : 16|2@1+ (1,0) [0|3] "" Vector__XXX
 SG_ DAAssrInvrtr4PwrLmtdDTUndfndRsn : 18|2@1+ (1,0) [0|3] "" Vector__XXX

BO_ 2565943038 DCACAI5CMD: 8 Vector__XXX
 SG_ DAAssrInvrtr5DvMxmmFrqn : 0|8@1+ (1,0) [0|250] "Hz" Vector__XXX
 SG_ DAAssrInvrtr5DvMnmmFrqn : 8|8@1+ (1,0) [0|250] "Hz" Vector__XXX
 SG_ DAAssrInvrtr5DvRtdFrqn : 16|8@1+ (1,0) [0|250] "Hz" Vector__XXX
 SG_ DAAssrInvrtr5DvRtdRmsVltg : 24|8@1+ (2,0) [0|500] "V" Vector__XXX
 SG_ DAAssrInvrtr5DvFrqnRtOfChngLmt : 32|8@1+ (2,0) [0|500] "Hz/s" Vector__XXX
 SG_ DAAssrInvrtr5FrqnCmmnd : 40|8@1+ (1,0) [0|250] "Hz" Vector__XXX
 SG_ DAAssrInvrtr5Dv1Stts : 48|3@1+ (1,0) [0|7] "" Vector__XXX
 SG_ DAAssrInvrtr5Dv2Stts : 51|3@1+ (1,0) [0|7] "" Vector__XXX
 SG_ DAAssrInvrtr5OprtnlCmmnd : 54|2@1+ (1,0) [0|3] "" Vector__XXX
 SG_ DAAssIvt5ASdMtSttRsVtRqst : 56|8@1+ (2,0) [0|500] "V" Vector__XXX

BO_ 2565943294 DCACAI5FDBK: 8 Vector__XXX
 SG_ DcAcAccessoryInverter5Frequency : 0|8@1+ (1,0) [0|250] "Hz" Vector__XXX
 SG_ DAAssrInvrtr5ASdRmsVltg : 8|8@1+ (2,0) [0|500] "V" Vector__XXX
 SG_ DAAssrInvrtr5ASdPwr : 16|8@1+ (0.1,0) [0|25] "kW" Vector__XXX
 SG_ DAAssrInvrtr5ASdRmsCrrnt : 24|16@1+ (0.03125,0) [0|2007.96875] "A" Vector__XXX
 SG_ DAAssrInvrtr5OprtnlStts : 48|3@1+ (1,0) [0|7] "" Vector__XXX
 SG_ DAAssrInvrtr5LdshdRqst : 51|2@1+ (1,0) [0|3] "" Vector__XXX
 SG_ DAAssrInvrtr5HvlStts : 53|2@1+ (1,0) [0|3] "" Vector__XXX

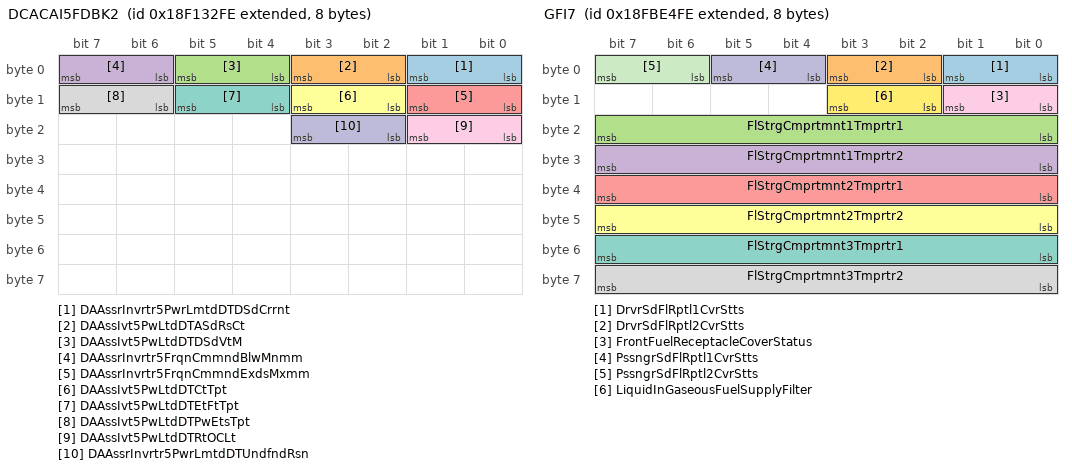
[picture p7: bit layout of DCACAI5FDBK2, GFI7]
BO_ 2565944062 DCACAI5FDBK2: 8 Vector__XXX
 SG_ DAAssrInvrtr5PwrLmtdDTDSdCrrnt : 0|2@1+ (1,0) [0|3] "" Vector__XXX
 SG_ DAAssIvt5PwLtdDTASdRsCt : 2|2@1+ (1,0) [0|3] "" Vector__XXX
 SG_ DAAssIvt5PwLtdDTDSdVtM : 4|2@1+ (1,0) [0|3] "" Vector__XXX
 SG_ DAAssrInvrtr5FrqnCmmndBlwMnmm : 6|2@1+ (1,0) [0|3] "" Vector__XXX
 SG_ DAAssrInvrtr5FrqnCmmndExdsMxmm : 8|2@1+ (1,0) [0|3] "" Vector__XXX
 SG_ DAAssIvt5PwLtdDTCtTpt : 10|2@1+ (1,0) [0|3] "" Vector__XXX
 SG_ DAAssIvt5PwLtdDTEtFtTpt : 12|2@1+ (1,0) [0|3] "" Vector__XXX
 SG_ DAAssIvt5PwLtdDTPwEtsTpt : 14|2@1+ (1,0) [0|3] "" Vector__XXX
 SG_ DAAssIvt5PwLtdDTRtOCLt : 16|2@1+ (1,0) [0|3] "" Vector__XXX
 SG_ DAAssrInvrtr5PwrLmtdDTUndfndRsn : 18|2@1+ (1,0) [0|3] "" Vector__XXX

BO_ 2566624510 EEC22: 8 Vector__XXX
 SG_ EngnExhstGsRrltn1ClrIntkPrssr : 0|16@1+ (5,0) [0|321275] "kPa" Vector__XXX
 SG_ TtlNmrOfCrnkAttmptsDrngEngnLf : 16|32@1+ (1,0) [0|4211081215] "count" Vector__XXX

BO_ 2566624766 HOURS2: 8 Vector__XXX
 SG_ EngnIdlMngmntAtvTtlTm : 0|32@1+ (0.05,0) [0|210554060.75] "h" Vector__XXX

BO_ 2566625022 EI3: 8 Vector__XXX
 SG_ InstntnsEstmtdEngnPwrRtLmt : 0|16@1+ (0.125,0) [0|8031.875] "kW/s" Vector__XXX
 SG_ EngineExhaustBank1Pressure2 : 16|16@1+ (0.0078125,-250) [-250|251.9921875] "kPa" Vector__XXX
 SG_ EngineDifferentialPressure : 32|16@1+ (0.0078125,-250) [-250|251.9921875] "kPa" Vector__XXX

BO_ 2566625278 VEP15: 8 Vector__XXX
 SG_ SlBttrPk1Bttr1CptSttng : 0|16@1+ (1,0) [0|64255] "Ah" Vector__XXX
 SG_ SlBttrPk1Bttr2CptSttng : 16|16@1+ (1,0) [0|64255] "Ah" Vector__XXX
 SG_ SlBttrPk1Bttr3CptSttng : 32|16@1+ (1,0) [0|64255] "Ah" Vector__XXX
 SG_ SlBttrPk1Bttr4CptSttng : 48|16@1+ (1,0) [0|64255] "Ah" Vector__XXX

BO_ 2566625790 DCACAI1T: 8 Vector__XXX
 SG_ DAAssrInvrtr1CntrllrTmprtr : 0|8@1+ (1,-40) [-40|210] "degC" Vector__XXX
 SG_ DAAssIvt1IvtEtFtTpt : 8|8@1+ (1,-40) [-40|210] "degC" Vector__XXX
 SG_ DAAssrInvrtr1PwrEltrnsTmprtr : 16|8@1+ (1,-40) [-40|210] "degC" Vector__XXX
 SG_ DAAssrInvrtr1ClntInTmprtr : 24|8@1+ (1,-40) [-40|210] "degC" Vector__XXX
 SG_ DAAssrInvrtr1ClntOtTmprtr : 32|8@1+ (1,-40) [-40|210] "degC" Vector__XXX

BO_ 2566626558 DCACAI1CFG1: 13 Vector__XXX
 SG_ DAAssIvt1DSdVtMLtStt : 0|16@1+ (0.05,0) [0|3212.75] "V" Vector__XXX
 SG_ DAAssIvt1DSdCtMxLtStt : 16|16@1+ (0.05,0) [0|3212.75] "A" Vector__XXX
 SG_ DAAssIvt1ASdRsVtMxLtStt : 32|16@1+ (0.03125,0) [0|2007.96875] "V" Vector__XXX
 SG_ DAAssIvt1ASdRsCtMxLtStt : 48|16@1+ (0.03125,0) [0|2007.96875] "A" Vector__XXX
 SG_ DAAssIvt1DSdVtMxLtStt : 64|16@1+ (0.05,0) [0|3212.75] "V" Vector__XXX
 SG_ DAAssIvt1DSdCtMLtStt : 80|16@1+ (0.05,-3212.75) [-3212.75|0] "A" Vector__XXX
 SG_ DAAssIvt1ASdDtFqCdStt : 96|8@1+ (1,0) [0|250] "Hz" Vector__XXX

BO_ 2566626814 DCACAI1LD: 8 Vector__XXX
 SG_ DAAssrInvrtr1TtlDInptChrg : 0|32@1+ (100,0) [0|421108121500] "Ah" Vector__XXX
 SG_ DAAssrInvrtr1TtlDInptEnrg : 32|32@1+ (100,0) [0|421108121500] "Watt-hour" Vector__XXX

BO_ 2566627070 DCACAI2T: 8 Vector__XXX
 SG_ DAAssrInvrtr2CntrllrTmprtr : 0|8@1+ (1,-40) [-40|210] "degC" Vector__XXX
 SG_ DAAssIvt2IvtEtFtTpt : 8|8@1+ (1,-40) [-40|210] "degC" Vector__XXX
 SG_ DAAssrInvrtr2PwrEltrnsTmprtr : 16|8@1+ (1,-40) [-40|210] "degC" Vector__XXX
 SG_ DAAssrInvrtr2ClntInTmprtr : 24|8@1+ (1,-40) [-40|210] "degC" Vector__XXX
 SG_ DAAssrInvrtr2ClntOtTmprtr : 32|8@1+ (1,-40) [-40|210] "degC" Vector__XXX

BO_ 2566627838 DCACAI2CFG1: 13 Vector__XXX
 SG_ DAAssIvt2DSdVtMLtStt : 0|16@1+ (0.05,0) [0|3212.75] "V" Vector__XXX
 SG_ DAAssIvt2DSdCtMxLtStt : 16|16@1+ (0.05,0) [0|3212.75] "A" Vector__XXX
 SG_ DAAssIvt2ASdRsVtMxLtStt : 32|16@1+ (0.03125,0) [0|2007.96875] "V" Vector__XXX
 SG_ DAAssIvt2ASdRsCtMxLtStt : 48|16@1+ (0.03125,0) [0|2007.96875] "A" Vector__XXX
 SG_ DAAssIvt2DSdVtMxLtStt : 64|16@1+ (0.05,0) [0|3212.75] "V" Vector__XXX
 SG_ DAAssIvt2DSdCtMLtStt : 80|16@1+ (0.05,-3212.75) [-3212.75|0] "A" Vector__XXX
 SG_ DAAssIvt2ASdDtFqCdStt : 96|8@1+ (1,0) [0|250] "Hz" Vector__XXX

BO_ 2566628094 DCACAI2LD: 8 Vector__XXX
 SG_ DAAssrInvrtr2TtlDInptChrg : 0|32@1+ (100,0) [0|421108121500] "Ah" Vector__XXX
 SG_ DAAssrInvrtr2TtlDInptEnrg : 32|32@1+ (100,0) [0|421108121500] "Watt-hour" Vector__XXX

BO_ 2566628350 DCACAI3T: 8 Vector__XXX
 SG_ DAAssrInvrtr3CntrllrTmprtr : 0|8@1+ (1,-40) [-40|210] "degC" Vector__XXX
 SG_ DAAssIvt3IvtEtFtTpt : 8|8@1+ (1,-40) [-40|210] "degC" Vector__XXX
 SG_ DAAssrInvrtr3PwrEltrnsTmprtr : 16|8@1+ (1,-40) [-40|210] "degC" Vector__XXX
 SG_ DAAssrInvrtr3ClntInTmprtr : 24|8@1+ (1,-40) [-40|210] "degC" Vector__XXX
 SG_ DAAssrInvrtr3ClntOtTmprtr : 32|8@1+ (1,-40) [-40|210] "degC" Vector__XXX

BO_ 2566629118 DCACAI3CFG1: 13 Vector__XXX
 SG_ DAAssIvt3DSdVtMLtStt : 0|16@1+ (0.05,0) [0|3212.75] "V" Vector__XXX
 SG_ DAAssIvt3DSdCtMxLtStt : 16|16@1+ (0.05,0) [0|3212.75] "A" Vector__XXX
 SG_ DAAssIvt3ASdRsVtMxLtStt : 32|16@1+ (0.03125,0) [0|2007.96875] "V" Vector__XXX
 SG_ DAAssIvt3ASdRsCtMxLtStt : 48|16@1+ (0.03125,0) [0|2007.96875] "A" Vector__XXX
 SG_ DAAssIvt3DSdVtMxLtStt : 64|16@1+ (0.05,0) [0|3212.75] "V" Vector__XXX
 SG_ DAAssIvt3DSdCtMLtStt : 80|16@1+ (0.05,-3212.75) [-3212.75|0] "A" Vector__XXX
 SG_ DAAssIvt3ASdDtFqCdStt : 96|8@1+ (1,0) [0|250] "Hz" Vector__XXX

BO_ 2566629374 DCACAI3LD: 8 Vector__XXX
 SG_ DAAssrInvrtr3TtlDInptChrg : 0|32@1+ (100,0) [0|421108121500] "Ah" Vector__XXX
 SG_ DAAssrInvrtr3TtlDInptEnrg : 32|32@1+ (100,0) [0|421108121500] "Watt-hour" Vector__XXX

BO_ 2566629630 DCACAI4T: 8 Vector__XXX
 SG_ DAAssrInvrtr4CntrllrTmprtr : 0|8@1+ (1,-40) [-40|210] "degC" Vector__XXX
 SG_ DAAssIvt4IvtEtFtTpt : 8|8@1+ (1,-40) [-40|210] "degC" Vector__XXX
 SG_ DAAssrInvrtr4PwrEltrnsTmprtr : 16|8@1+ (1,-40) [-40|210] "degC" Vector__XXX
 SG_ DAAssrInvrtr4ClntInTmprtr : 24|8@1+ (1,-40) [-40|210] "degC" Vector__XXX
 SG_ DAAssrInvrtr4ClntOtTmprtr : 32|8@1+ (1,-40) [-40|210] "degC" Vector__XXX

BO_ 2566630398 DCACAI4CFG1: 13 Vector__XXX
 SG_ DAAssIvt4DSdVtMLtStt : 0|16@1+ (0.05,0) [0|3212.75] "V" Vector__XXX
 SG_ DAAssIvt4DSdCtMxLtStt : 16|16@1+ (0.05,0) [0|3212.75] "A" Vector__XXX
 SG_ DAAssIvt4ASdRsVtMxLtStt : 32|16@1+ (0.03125,0) [0|2007.96875] "V" Vector__XXX
 SG_ DAAssIvt4ASdRsCtMxLtStt : 48|16@1+ (0.03125,0) [0|2007.96875] "A" Vector__XXX
 SG_ DAAssIvt4DSdVtMxLtStt : 64|16@1+ (0.05,0) [0|3212.75] "V" Vector__XXX
 SG_ DAAssIvt4DSdCtMLtStt : 80|16@1+ (0.05,-3212.75) [-3212.75|0] "A" Vector__XXX
 SG_ DAAssIvt4ASdDtFqCdStt : 96|8@1+ (1,0) [0|250] "Hz" Vector__XXX

BO_ 2566630654 DCACAI4LD: 8 Vector__XXX
 SG_ DAAssrInvrtr4TtlDInptChrg : 0|32@1+ (100,0) [0|421108121500] "Ah" Vector__XXX
 SG_ DAAssrInvrtr4TtlDInptEnrg : 32|32@1+ (100,0) [0|421108121500] "Watt-hour" Vector__XXX

BO_ 2566630910 DCACAI5T: 8 Vector__XXX
 SG_ DAAssrInvrtr5CntrllrTmprtr : 0|8@1+ (1,-40) [-40|210] "degC" Vector__XXX
 SG_ DAAssIvt5IvtEtFtTpt : 8|8@1+ (1,-40) [-40|210] "degC" Vector__XXX
 SG_ DAAssrInvrtr5PwrEltrnsTmprtr : 16|8@1+ (1,-40) [-40|210] "degC" Vector__XXX
 SG_ DAAssrInvrtr5ClntInTmprtr : 24|8@1+ (1,-40) [-40|210] "degC" Vector__XXX
 SG_ DAAssrInvrtr5ClntOtTmprtr : 32|8@1+ (1,-40) [-40|210] "degC" Vector__XXX

BO_ 2566631678 DCACAI5CFG1: 13 Vector__XXX
 SG_ DAAssIvt5DSdVtMLtStt : 0|16@1+ (0.05,0) [0|3212.75] "V" Vector__XXX
 SG_ DAAssIvt5DSdCtMxLtStt : 16|16@1+ (0.05,0) [0|3212.75] "A" Vector__XXX
 SG_ DAAssIvt5ASdRsVtMxLtStt : 32|16@1+ (0.03125,0) [0|2007.96875] "V" Vector__XXX
 SG_ DAAssIvt5ASdRsCtMxLtStt : 48|16@1+ (0.03125,0) [0|2007.96875] "A" Vector__XXX
 SG_ DAAssIvt5DSdVtMxLtStt : 64|16@1+ (0.05,0) [0|3212.75] "V" Vector__XXX
 SG_ DAAssIvt5DSdCtMLtStt : 80|16@1+ (0.05,-3212.75) [-3212.75|0] "A" Vector__XXX
 SG_ DAAssIvt5ASdDtFqCdStt : 96|8@1+ (1,0) [0|250] "Hz" Vector__XXX

BO_ 2566631934 DCACAI5LD: 8 Vector__XXX
 SG_ DAAssrInvrtr5TtlDInptChrg : 0|32@1+ (100,0) [0|421108121500] "Ah" Vector__XXX
 SG_ DAAssrInvrtr5TtlDInptEnrg : 32|32@1+ (100,0) [0|421108121500] "Watt-hour" Vector__XXX

BO_ 2566632190 WSPSCS: 8 Vector__XXX
 SG_ WllStmltnPmpStnPrssrClrtnStPnt : 0|4@1+ (1,0) [0|15] "" Vector__XXX
 SG_ WSttPpDsPssCtStPt : 8|4@1+ (1,0) [0|15] "" Vector__XXX
 SG_ WSttPpDsPssCtStPtStts : 12|2@1+ (1,0) [0|3] "" Vector__XXX
 SG_ WSttPpStPssCtStPtStts : 4|2@1+ (1,0) [0|3] "" Vector__XXX

BO_ 2566632446 WSPFV: 8 Vector__XXX
 SG_ WllStmltnPmpTrpFldPmpd : 32|32@1+ (0.5,0) [0|2105540607.5] "l" Vector__XXX
 SG_ WllStmltnPmpTtlFldPmpd : 0|32@1+ (0.5,0) [0|2105540607.5] "l" Vector__XXX

BO_ 2566632958 WSPH2: 8 Vector__XXX
 SG_ WllStmltnPmpFldEndTrpHrs : 0|32@1+ (1,0) [0|4211081215] "s" Vector__XXX
 SG_ WllStmltnPmpPwrEndTrpHrs : 32|32@1+ (1,0) [0|4211081215] "s" Vector__XXX

BO_ 2566633214 AT1OG4: 8 Vector__XXX
 SG_ Aftrtrtmnt1OtltOxgnPmpngCrrnt : 0|16@1+ (0.001,-32.127) [-32.127|32.128] "mA" Vector__XXX
 SG_ Atttt1OttNxSsPttAPssAst : 16|16@1+ (0.1,0) [0|6425.5] "kPa" Vector__XXX

BO_ 2566633470 AT1IG4: 8 Vector__XXX
 SG_ Atttt1ItNxSsPttAPssAst : 16|16@1+ (0.1,0) [0|6425.5] "kPa" Vector__XXX
 SG_ EngnExhst1OxgnPmpngCrrnt : 0|16@1+ (0.001,-32.127) [-32.127|32.128] "mA" Vector__XXX

BO_ 2566633726 DCDC4LD: 16 Vector__XXX
 SG_ DcDc4TotalHighSideCharge : 64|32@1+ (100,0) [0|421108121500] "Ah" Vector__XXX
 SG_ DcDc4TotalHighSideEnergy : 0|32@1+ (100,0) [0|421108121500] "Watt-hour" Vector__XXX
 SG_ DcDc4TotalLowSideCharge : 96|32@1+ (100,0) [0|421108121500] "Ah" Vector__XXX
 SG_ DcDc4TotalLowSideEnergy : 32|32@1+ (100,0) [0|421108121500] "Watt-hour" Vector__XXX

BO_ 2566633982 DCDC4CFG1: 23 Vector__XXX
 SG_ DD4HghSdVltgMnmmLmtSttng : 0|16@1+ (0.05,0) [0|3212.75] "V" Vector__XXX
 SG_ DD4HghSdVltgMxmmLmtSttng : 16|16@1+ (0.05,0) [0|3212.75] "V" Vector__XXX
 SG_ DD4HghSdCrrntMxmmLmtSttng : 32|16@1+ (0.05,0) [0|3212.75] "A" Vector__XXX
 SG_ DD4LwSdVltgMnmmLmtSttng : 48|16@1+ (0.01,0) [0|642.55] "V" Vector__XXX
 SG_ DD4LwSdVltgMxmmLmtSttng : 64|16@1+ (0.01,0) [0|642.55] "V" Vector__XXX
 SG_ DD4LwSdCrrntMxmmLmtSttng : 80|16@1+ (0.05,0) [0|3212.75] "A" Vector__XXX
 SG_ DD4SlBttrTrmnlVltgMxmmLmtSttng : 96|16@1+ (0.01,0) [0|642.55] "V" Vector__XXX
 SG_ DD4SBttTCCtMxLtStt : 112|16@1+ (0.05,0) [0|3212.75] "A" Vector__XXX
 SG_ DD4SlBttrTmprtrMxmmLmtSttng : 128|8@1+ (1,-40) [-40|210] "degC" Vector__XXX
 SG_ DD4LwSdVltgBkDfltSttng : 136|16@1+ (0.01,0) [0|642.55] "V" Vector__XXX
 SG_ DD4LwSdCrrntMnmmLmtSttng : 152|16@1+ (0.05,-3212.75) [-3212.75|0] "A" Vector__XXX
 SG_ DD4HghSdCrrntMnmmLmtSttng : 168|16@1+ (0.05,-3212.75) [-3212.75|0] "A" Vector__XXX

BO_ 2566635262 DCDC3LD: 16 Vector__XXX
 SG_ DcDc3TotalHighSideCharge : 64|32@1+ (100,0) [0|421108121500] "Ah" Vector__XXX
 SG_ DcDc3TotalHighSideEnergy : 0|32@1+ (100,0) [0|421108121500] "Watt-hour" Vector__XXX
 SG_ DcDc3TotalLowSideCharge : 96|32@1+ (100,0) [0|421108121500] "Ah" Vector__XXX
 SG_ DcDc3TotalLowSideEnergy : 32|32@1+ (100,0) [0|421108121500] "Watt-hour" Vector__XXX

BO_ 2566635518 DCDC3CFG1: 23 Vector__XXX
 SG_ DD3HghSdVltgMnmmLmtSttng : 0|16@1+ (0.05,0) [0|3212.75] "V" Vector__XXX
 SG_ DD3HghSdVltgMxmmLmtSttng : 16|16@1+ (0.05,0) [0|3212.75] "V" Vector__XXX
 SG_ DD3HghSdCrrntMxmmLmtSttng : 32|16@1+ (0.05,0) [0|3212.75] "A" Vector__XXX
 SG_ DD3LwSdVltgMnmmLmtSttng : 48|16@1+ (0.01,0) [0|642.55] "V" Vector__XXX
 SG_ DD3LwSdVltgMxmmLmtSttng : 64|16@1+ (0.01,0) [0|642.55] "V" Vector__XXX
 SG_ DD3LwSdCrrntMxmmLmtSttng : 80|16@1+ (0.05,0) [0|3212.75] "A" Vector__XXX
 SG_ DD3SlBttrTrmnlVltgMxmmLmtSttng : 96|16@1+ (0.01,0) [0|642.55] "V" Vector__XXX
 SG_ DD3SBttTCCtMxLtStt : 112|16@1+ (0.05,0) [0|3212.75] "A" Vector__XXX
 SG_ DD3SlBttrTmprtrMxmmLmtSttng : 128|8@1+ (1,-40) [-40|210] "degC" Vector__XXX
 SG_ DD3LwSdVltgBkDfltSttng : 136|16@1+ (0.01,0) [0|642.55] "V" Vector__XXX
 SG_ DD3LwSdCrrntMnmmLmtSttng : 152|16@1+ (0.05,-3212.75) [-3212.75|0] "A" Vector__XXX
 SG_ DD3HghSdCrrntMnmmLmtSttng : 168|16@1+ (0.05,-3212.75) [-3212.75|0] "A" Vector__XXX

BO_ 2566636798 DCDC2LD: 16 Vector__XXX
 SG_ DcDc2TotalHighSideCharge : 64|32@1+ (100,0) [0|421108121500] "Ah" Vector__XXX
 SG_ DcDc2TotalHighSideEnergy : 0|32@1+ (100,0) [0|421108121500] "Watt-hour" Vector__XXX
 SG_ DcDc2TotalLowSideCharge : 96|32@1+ (100,0) [0|421108121500] "Ah" Vector__XXX
 SG_ DcDc2TotalLowSideEnergy : 32|32@1+ (100,0) [0|421108121500] "Watt-hour" Vector__XXX

BO_ 2566637054 DCDC2CFG1: 23 Vector__XXX
 SG_ DD2HghSdVltgMnmmLmtSttng : 0|16@1+ (0.05,0) [0|3212.75] "V" Vector__XXX
 SG_ DD2HghSdVltgMxmmLmtSttng : 16|16@1+ (0.05,0) [0|3212.75] "V" Vector__XXX
 SG_ DD2HghSdCrrntMxmmLmtSttng : 32|16@1+ (0.05,0) [0|3212.75] "A" Vector__XXX
 SG_ DD2LwSdVltgMnmmLmtSttng : 48|16@1+ (0.01,0) [0|642.55] "V" Vector__XXX
 SG_ DD2LwSdVltgMxmmLmtSttng : 64|16@1+ (0.01,0) [0|642.55] "V" Vector__XXX
 SG_ DD2LwSdCrrntMxmmLmtSttng : 80|16@1+ (0.05,0) [0|3212.75] "A" Vector__XXX
 SG_ DD2SlBttrTrmnlVltgMxmmLmtSttng : 96|16@1+ (0.01,0) [0|642.55] "V" Vector__XXX
 SG_ DD2SBttTCCtMxLtStt : 112|16@1+ (0.05,0) [0|3212.75] "A" Vector__XXX
 SG_ DD2SlBttrTmprtrMxmmLmtSttng : 128|8@1+ (1,-40) [-40|210] "degC" Vector__XXX
 SG_ DD2LwSdVltgBkDfltSttng : 136|16@1+ (0.01,0) [0|642.55] "V" Vector__XXX
 SG_ DD2LwSdCrrntMnmmLmtSttng : 152|16@1+ (0.05,-3212.75) [-3212.75|0] "A" Vector__XXX
 SG_ DD2HghSdCrrntMnmmLmtSttng : 168|16@1+ (0.05,-3212.75) [-3212.75|0] "A" Vector__XXX

BO_ 2566638590 EEPCSI: 8 Vector__XXX
 SG_ ExhstPrtltCntrlSstmDgnstCnt : 32|32@1+ (1,0) [0|4211081215] "count" Vector__XXX
 SG_ ExhstPrtltCntrlSstmDgnstTm : 0|32@1+ (1,0) [0|4211081215] "s" Vector__XXX

BO_ 2566638846 WSPH: 16 Vector__XXX
 SG_ WllStmltnPmpMntnnIntrvlHrs : 0|32@1+ (1,0) [0|4211081215] "s" Vector__XXX
 SG_ WllStmltnPmpPkngOprtnHrs : 64|32@1+ (1,0) [0|4211081215] "s" Vector__XXX
 SG_ WllStmltnPmpVlvOprtnHrs : 32|32@1+ (1,0) [0|4211081215] "s" Vector__XXX
 SG_ WllStmltnPmpVlvStOprtnHrs : 96|32@1+ (1,0) [0|4211081215] "s" Vector__XXX

BO_ 2566639102 WSPT2: 19 Vector__XXX
 SG_ WllStmltnPmpPlngrFrngOrdrSttng : 144|4@1+ (1,0) [0|15] "" Vector__XXX
 SG_ WllStmltnPmpRdLdHghThrshldSttng : 128|16@1+ (5,0) [0|321275] "kN" Vector__XXX
 SG_ WSttPpCstSpdHTsdStt : 112|16@1+ (0.125,0) [0|8031.875] "rpm" Vector__XXX
 SG_ WSttPpCstSpdLwTsdStt : 96|16@1+ (0.125,0) [0|8031.875] "rpm" Vector__XXX
 SG_ WSttPpDsPssHTsdStt : 80|16@1+ (5,0) [0|321275] "kPa" Vector__XXX
 SG_ WSttPpGBxOPssHTsdStt : 16|16@1+ (0.1,0) [0|6425.5] "kPa" Vector__XXX
 SG_ WSttPpGBxOPssLwTsdStt : 0|16@1+ (0.1,0) [0|6425.5] "kPa" Vector__XXX
 SG_ WSttPpGBxOTptHTsdStt : 40|8@1+ (1,-40) [-40|210] "degC" Vector__XXX
 SG_ WSttPpGBxOTptLwTsdStt : 32|8@1+ (1,-40) [-40|210] "degC" Vector__XXX
 SG_ WSttPpStPssHTsdStt : 64|16@1+ (0.1,-3212.7) [-3212.7|3212.8] "kPa" Vector__XXX
 SG_ WSttPpStPssLwTsdStt : 48|16@1+ (0.1,-3212.7) [-3212.7|3212.8] "kPa" Vector__XXX

BO_ 2566639614 DCDC1LD: 16 Vector__XXX
 SG_ DcDc1TotalHighSideCharge : 64|32@1+ (100,0) [0|421108121500] "Ah" Vector__XXX
 SG_ DcDc1TotalHighSideEnergy : 0|32@1+ (100,0) [0|421108121500] "Watt-hour" Vector__XXX
 SG_ DcDc1TotalLowSideCharge : 96|32@1+ (100,0) [0|421108121500] "Ah" Vector__XXX
 SG_ DcDc1TotalLowSideEnergy : 32|32@1+ (100,0) [0|421108121500] "Watt-hour" Vector__XXX

BO_ 2566639870 DCDC1CFG1: 23 Vector__XXX
 SG_ DD1HghSdVltgMnmmLmtSttng : 0|16@1+ (0.05,0) [0|3212.75] "V" Vector__XXX
 SG_ DD1HghSdVltgMxmmLmtSttng : 16|16@1+ (0.05,0) [0|3212.75] "V" Vector__XXX
 SG_ DD1HghSdCrrntMxmmLmtSttng : 32|16@1+ (0.05,0) [0|3212.75] "A" Vector__XXX
 SG_ DD1LwSdVltgMnmmLmtSttng : 48|16@1+ (0.01,0) [0|642.55] "V" Vector__XXX
 SG_ DD1LwSdVltgMxmmLmtSttng : 64|16@1+ (0.01,0) [0|642.55] "V" Vector__XXX
 SG_ DD1LwSdCrrntMxmmLmtSttng : 80|16@1+ (0.05,0) [0|3212.75] "A" Vector__XXX
 SG_ DD1SlBttrTrmnlVltgMxmmLmtSttng : 96|16@1+ (0.01,0) [0|642.55] "V" Vector__XXX
 SG_ DD1SBttTCCtMxLtStt : 112|16@1+ (0.05,0) [0|3212.75] "A" Vector__XXX
 SG_ DD1SlBttrTmprtrMxmmLmtSttng : 128|8@1+ (1,-40) [-40|210] "degC" Vector__XXX
 SG_ DD1LwSdVltgBkDfltSttng : 136|16@1+ (0.01,0) [0|642.55] "V" Vector__XXX
 SG_ DD1LwSdCrrntMnmmLmtSttng : 152|16@1+ (0.05,-3212.75) [-3212.75|0] "A" Vector__XXX
 SG_ DD1HghSdCrrntMnmmLmtSttng : 168|16@1+ (0.05,-3212.75) [-3212.75|0] "A" Vector__XXX

BO_ 2566640382 POM: 8 Vector__XXX
 SG_ WellStimulationPumpOilDensity : 16|16@1+ (0.00003052,0) [0|1.9610626] "g/cc" Vector__XXX
 SG_ WellStimulationPumpOilViscosity : 0|16@1+ (0.015625,0) [0|1003.984375] "Cp" Vector__XXX
 SG_ WllStmltnPmpOlRltvDltrt : 32|16@1+ (0.0001220703125,0) [0|7.8436279296875] "" Vector__XXX
 SG_ WllStmltnPmpOlTmprtr : 48|16@1+ (0.03125,-273) [-273|1734.96875] "degC" Vector__XXX

BO_ 2566641150 ACOCF2: 8 Vector__XXX
 SG_ AltrntrBrngHdrIntkPrssr : 0|8@1+ (2,0) [0|500] "kPa" Vector__XXX
 SG_ AltrntrOlClrDshrgPmpPrssr : 8|8@1+ (2,0) [0|500] "kPa" Vector__XXX
 SG_ EngnOlClrDshrgPmpPrssr : 16|8@1+ (2,0) [0|500] "kPa" Vector__XXX
 SG_ EngnOlClrIntkTmprtr : 24|8@1+ (1,-40) [-40|210] "degC" Vector__XXX

BO_ 2566641406 EEC21: 8 Vector__XXX
 SG_ EngnExhstMnfldAsltPrssr1 : 0|16@1+ (0.1,0) [0|6425.5] "kPa" Vector__XXX
 SG_ EngnExhstMnfldAsltPrssr2 : 16|16@1+ (0.1,0) [0|6425.5] "kPa" Vector__XXX

BO_ 2566642942 DC4: 8 Vector__XXX
 SG_ EnableStatusOfDoor21 : 4|2@1+ (1,0) [0|3] "" Vector__XXX
 SG_ EnableStatusOfDoor22 : 10|2@1+ (1,0) [0|3] "" Vector__XXX
 SG_ EnableStatusOfDoor23 : 16|2@1+ (1,0) [0|3] "" Vector__XXX
 SG_ EnableStatusOfDoor24 : 22|2@1+ (1,0) [0|3] "" Vector__XXX
 SG_ EnableStatusOfDoor25 : 28|2@1+ (1,0) [0|3] "" Vector__XXX
 SG_ EnableStatusOfDoor26 : 34|2@1+ (1,0) [0|3] "" Vector__XXX
 SG_ EnableStatusOfDoor27 : 40|2@1+ (1,0) [0|3] "" Vector__XXX
 SG_ EnableStatusOfDoor28 : 46|2@1+ (1,0) [0|3] "" Vector__XXX
 SG_ EnableStatusOfDoor29 : 52|2@1+ (1,0) [0|3] "" Vector__XXX
 SG_ EnableStatusOfDoor30 : 58|2@1+ (1,0) [0|3] "" Vector__XXX
 SG_ LockStatusOfDoor21 : 0|2@1+ (1,0) [0|3] "" Vector__XXX
 SG_ LockStatusOfDoor22 : 6|2@1+ (1,0) [0|3] "" Vector__XXX
 SG_ LockStatusOfDoor23 : 12|2@1+ (1,0) [0|3] "" Vector__XXX
 SG_ LockStatusOfDoor24 : 18|2@1+ (1,0) [0|3] "" Vector__XXX
 SG_ LockStatusOfDoor25 : 24|2@1+ (1,0) [0|3] "" Vector__XXX
 SG_ LockStatusOfDoor26 : 30|2@1+ (1,0) [0|3] "" Vector__XXX
 SG_ LockStatusOfDoor27 : 36|2@1+ (1,0) [0|3] "" Vector__XXX
 SG_ LockStatusOfDoor28 : 42|2@1+ (1,0) [0|3] "" Vector__XXX
 SG_ LockStatusOfDoor29 : 48|2@1+ (1,0) [0|3] "" Vector__XXX
 SG_ LockStatusOfDoor30 : 54|2@1+ (1,0) [0|3] "" Vector__XXX
 SG_ OpenStatusOfDoor21 : 2|2@1+ (1,0) [0|3] "" Vector__XXX
 SG_ OpenStatusOfDoor22 : 8|2@1+ (1,0) [0|3] "" Vector__XXX
 SG_ OpenStatusOfDoor23 : 14|2@1+ (1,0) [0|3] "" Vector__XXX
 SG_ OpenStatusOfDoor24 : 20|2@1+ (1,0) [0|3] "" Vector__XXX
 SG_ OpenStatusOfDoor25 : 26|2@1+ (1,0) [0|3] "" Vector__XXX
 SG_ OpenStatusOfDoor26 : 32|2@1+ (1,0) [0|3] "" Vector__XXX
 SG_ OpenStatusOfDoor27 : 38|2@1+ (1,0) [0|3] "" Vector__XXX
 SG_ OpenStatusOfDoor28 : 44|2@1+ (1,0) [0|3] "" Vector__XXX
 SG_ OpenStatusOfDoor29 : 50|2@1+ (1,0) [0|3] "" Vector__XXX
 SG_ OpenStatusOfDoor30 : 56|2@1+ (1,0) [0|3] "" Vector__XXX

BO_ 2566643198 DC3: 8 Vector__XXX
 SG_ EnableStatusOfDoor11 : 4|2@1+ (1,0) [0|3] "" Vector__XXX
 SG_ EnableStatusOfDoor12 : 10|2@1+ (1,0) [0|3] "" Vector__XXX
 SG_ EnableStatusOfDoor13 : 16|2@1+ (1,0) [0|3] "" Vector__XXX
 SG_ EnableStatusOfDoor14 : 22|2@1+ (1,0) [0|3] "" Vector__XXX
 SG_ EnableStatusOfDoor15 : 28|2@1+ (1,0) [0|3] "" Vector__XXX
 SG_ EnableStatusOfDoor16 : 34|2@1+ (1,0) [0|3] "" Vector__XXX
 SG_ EnableStatusOfDoor17 : 40|2@1+ (1,0) [0|3] "" Vector__XXX
 SG_ EnableStatusOfDoor18 : 46|2@1+ (1,0) [0|3] "" Vector__XXX
 SG_ EnableStatusOfDoor19 : 52|2@1+ (1,0) [0|3] "" Vector__XXX
 SG_ EnableStatusOfDoor20 : 58|2@1+ (1,0) [0|3] "" Vector__XXX
 SG_ LockStatusOfDoor11 : 0|2@1+ (1,0) [0|3] "" Vector__XXX
 SG_ LockStatusOfDoor12 : 6|2@1+ (1,0) [0|3] "" Vector__XXX
 SG_ LockStatusOfDoor13 : 12|2@1+ (1,0) [0|3] "" Vector__XXX
 SG_ LockStatusOfDoor14 : 18|2@1+ (1,0) [0|3] "" Vector__XXX
 SG_ LockStatusOfDoor15 : 24|2@1+ (1,0) [0|3] "" Vector__XXX
 SG_ LockStatusOfDoor16 : 30|2@1+ (1,0) [0|3] "" Vector__XXX
 SG_ LockStatusOfDoor17 : 36|2@1+ (1,0) [0|3] "" Vector__XXX
 SG_ LockStatusOfDoor18 : 42|2@1+ (1,0) [0|3] "" Vector__XXX
 SG_ LockStatusOfDoor19 : 48|2@1+ (1,0) [0|3] "" Vector__XXX
 SG_ LockStatusOfDoor20 : 54|2@1+ (1,0) [0|3] "" Vector__XXX
 SG_ OpenStatusOfDoor11 : 2|2@1+ (1,0) [0|3] "" Vector__XXX
 SG_ OpenStatusOfDoor12 : 8|2@1+ (1,0) [0|3] "" Vector__XXX
 SG_ OpenStatusOfDoor13 : 14|2@1+ (1,0) [0|3] "" Vector__XXX
 SG_ OpenStatusOfDoor14 : 20|2@1+ (1,0) [0|3] "" Vector__XXX
 SG_ OpenStatusOfDoor15 : 26|2@1+ (1,0) [0|3] "" Vector__XXX
 SG_ OpenStatusOfDoor16 : 32|2@1+ (1,0) [0|3] "" Vector__XXX
 SG_ OpenStatusOfDoor17 : 38|2@1+ (1,0) [0|3] "" Vector__XXX
 SG_ OpenStatusOfDoor18 : 44|2@1+ (1,0) [0|3] "" Vector__XXX
 SG_ OpenStatusOfDoor19 : 50|2@1+ (1,0) [0|3] "" Vector__XXX
 SG_ OpenStatusOfDoor20 : 56|2@1+ (1,0) [0|3] "" Vector__XXX

BO_ 2566643454 ET6: 8 Vector__XXX
 SG_ EngineIntakeCoolantTemperature : 32|16@1+ (0.03125,-273) [-273|1734.96875] "degC" Vector__XXX
 SG_ EngnChrgArClrIntkClntTmprtr : 0|16@1+ (0.03125,-273) [-273|1734.96875] "degC" Vector__XXX
 SG_ EngnChrgArClrOtltClntTmprtr : 16|16@1+ (0.03125,-273) [-273|1734.96875] "degC" Vector__XXX
 SG_ EItMdATSdCtCtCtDtTpt : 48|16@1+ (0.03125,-273) [-273|1734.96875] "degC" Vector__XXX

BO_ 2566643710 IC3: 8 Vector__XXX
 SG_ EngineMixer1IntakePressure : 0|16@1+ (0.1,0) [0|6425.5] "kPa" Vector__XXX
 SG_ EngineMixer2IntakePressure : 16|16@1+ (0.1,0) [0|6425.5] "kPa" Vector__XXX
 SG_ EngnIntkMnfld2AsltPrssrHghRsltn : 32|16@1+ (0.1,0) [0|6425.5] "kPa" Vector__XXX
 SG_ DsrdEngnIntkMnfldPrssrHghLmt : 48|16@1+ (0.1,0) [0|6425.5] "kPa" Vector__XXX

BO_ 2566644990 GFI7: 8 Vector__XXX
 SG_ DrvrSdFlRptl1CvrStts : 0|2@1+ (1,0) [0|3] "" Vector__XXX
 SG_ DrvrSdFlRptl2CvrStts : 2|2@1+ (1,0) [0|3] "" Vector__XXX
 SG_ FlStrgCmprtmnt1Tmprtr1 : 16|8@1+ (1,-40) [-40|210] "degC" Vector__XXX
 SG_ FlStrgCmprtmnt1Tmprtr2 : 24|8@1+ (1,-40) [-40|210] "degC" Vector__XXX
 SG_ FlStrgCmprtmnt2Tmprtr1 : 32|8@1+ (1,-40) [-40|210] "degC" Vector__XXX
 SG_ FlStrgCmprtmnt2Tmprtr2 : 40|8@1+ (1,-40) [-40|210] "degC" Vector__XXX
 SG_ FlStrgCmprtmnt3Tmprtr1 : 48|8@1+ (1,-40) [-40|210] "degC" Vector__XXX
 SG_ FlStrgCmprtmnt3Tmprtr2 : 56|8@1+ (1,-40) [-40|210] "degC" Vector__XXX
 SG_ FrontFuelReceptacleCoverStatus : 8|2@1+ (1,0) [0|3] "" Vector__XXX
 SG_ PssngrSdFlRptl1CvrStts : 4|2@1+ (1,0) [0|3] "" Vector__XXX
 SG_ PssngrSdFlRptl2CvrStts : 6|2@1+ (1,0) [0|3] "" Vector__XXX
 SG_ LiquidInGaseousFuelSupplyFilter : 10|2@1+ (1,0) [0|3] "" Vector__XXX

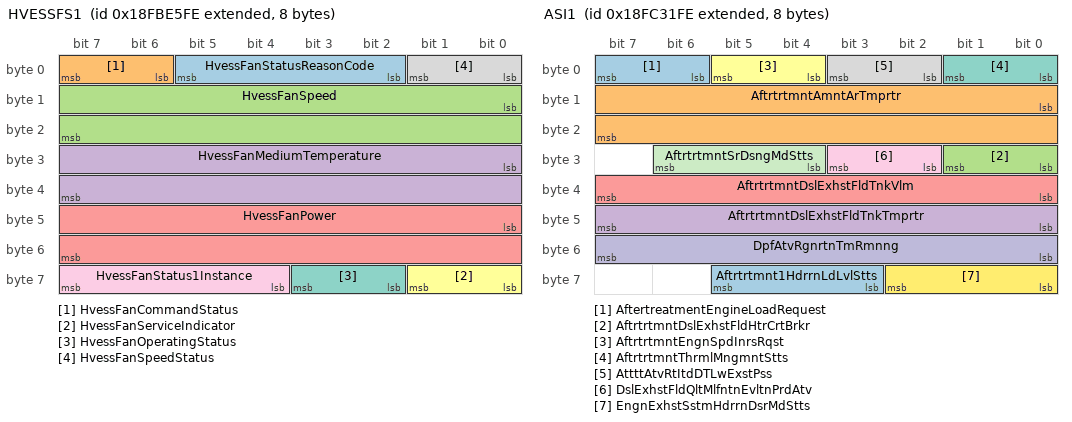
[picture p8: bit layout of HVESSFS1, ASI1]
BO_ 2566645246 HVESSFS1: 8 Vector__XXX
 SG_ HvessFanStatusReasonCode : 2|4@1+ (1,0) [0|15] "" Vector__XXX
 SG_ HvessFanCommandStatus : 6|2@1+ (1,0) [0|3] "" Vector__XXX
 SG_ HvessFanSpeed : 8|16@1+ (0.5,0) [0|32127.5] "rpm" Vector__XXX
 SG_ HvessFanMediumTemperature : 24|16@1+ (0.03125,-273) [-273|1734.96875] "degC" Vector__XXX
 SG_ HvessFanPower : 40|16@1+ (0.5,0) [0|32127.5] "W" Vector__XXX
 SG_ HvessFanServiceIndicator : 56|2@1+ (1,0) [0|3] "" Vector__XXX
 SG_ HvessFanOperatingStatus : 58|2@1+ (1,0) [0|3] "" Vector__XXX
 SG_ HvessFanSpeedStatus : 0|2@1+ (1,0) [0|3] "" Vector__XXX
 SG_ HvessFanStatus1Instance : 60|4@1+ (1,0) [0|15] "" Vector__XXX

BO_ 2566646782 ODMCF12: 8 Vector__XXX
 SG_ OlDrsMntrFrrsBn1Cnt : 8|24@1+ (1,0) [0|16449535] "count" Vector__XXX
 SG_ OlDrsMntrFrrsBn2Cnt : 32|24@1+ (1,0) [0|16449535] "count" Vector__XXX
 SG_ OlDrsMntrFrrsBns1And2IdntftnNmr : 0|8@1+ (1,0) [0|250] "count" Vector__XXX

BO_ 2566647038 ODMCF34: 8 Vector__XXX
 SG_ OlDrsMntrFrrsBn3Cnt : 8|24@1+ (1,0) [0|16449535] "count" Vector__XXX
 SG_ OlDrsMntrFrrsBn4Cnt : 32|24@1+ (1,0) [0|16449535] "count" Vector__XXX
 SG_ OlDrsMntrFrrsBns3And4IdntftnNmr : 0|8@1+ (1,0) [0|250] "count" Vector__XXX

BO_ 2566647294 ODMCF56: 8 Vector__XXX
 SG_ OlDrsMntrFrrsBn5Cnt : 8|24@1+ (1,0) [0|16449535] "count" Vector__XXX
 SG_ OlDrsMntrFrrsBn6Cnt : 32|24@1+ (1,0) [0|16449535] "count" Vector__XXX
 SG_ OlDrsMntrFrrsBns5And6IdntftnNmr : 0|8@1+ (1,0) [0|250] "count" Vector__XXX

BO_ 2566647550 ODMCNF12: 8 Vector__XXX
 SG_ OlDrsMntrNnFrrsBn1Cnt : 8|24@1+ (1,0) [0|16449535] "count" Vector__XXX
 SG_ OlDrsMntrNnFrrsBn2Cnt : 32|24@1+ (1,0) [0|16449535] "count" Vector__XXX
 SG_ ODsMtNFsBs1Ad2IdttN : 0|8@1+ (1,0) [0|250] "count" Vector__XXX

BO_ 2566647806 ODMCNF34: 8 Vector__XXX
 SG_ OlDrsMntrNnFrrsBn3Cnt : 8|24@1+ (1,0) [0|16449535] "count" Vector__XXX
 SG_ OlDrsMntrNnFrrsBn4Cnt : 32|24@1+ (1,0) [0|16449535] "count" Vector__XXX
 SG_ ODsMtNFsBs3Ad4IdttN : 0|8@1+ (1,0) [0|250] "count" Vector__XXX

BO_ 2566648062 ODMCNF56: 8 Vector__XXX
 SG_ OlDrsMntrNnFrrsBn5Cnt : 8|24@1+ (1,0) [0|16449535] "count" Vector__XXX
 SG_ OlDrsMntrNnFrrsBn6Cnt : 32|24@1+ (1,0) [0|16449535] "count" Vector__XXX
 SG_ ODsMtNFsBs5Ad6IdttN : 0|8@1+ (1,0) [0|250] "count" Vector__XXX

BO_ 2566648318 ODMSS: 8 Vector__XXX
 SG_ OlDrsMntrEltrnsTmprtrStts : 22|2@1+ (1,0) [0|3] "" Vector__XXX
 SG_ OlDrsMntrEnvrnmntStts : 16|2@1+ (1,0) [0|3] "" Vector__XXX
 SG_ OlDrsMntrSgnlPrssngEltrnsStts : 20|2@1+ (1,0) [0|3] "" Vector__XXX
 SG_ OlDrsMntrSnsngElmntStts : 18|2@1+ (1,0) [0|3] "" Vector__XXX
 SG_ OlDrsMntrSttsIdntftnNmr : 0|8@1+ (1,0) [0|250] "count" Vector__XXX
 SG_ OlDrsMntrTtlNmrOfSnsrs : 8|8@1+ (1,0) [0|250] "count" Vector__XXX

BO_ 2566649086 A2DOC2: 8 Vector__XXX
 SG_ Atttt2DsOxdtCtstItPss : 0|16@1+ (0.1,0) [0|6425.5] "kPa" Vector__XXX
 SG_ Atttt2DsOxdtCtstOttPss : 16|16@1+ (0.1,0) [0|6425.5] "kPa" Vector__XXX
 SG_ Atttt2DItTDpOttDtPss : 32|16@1+ (0.1,0) [0|6425.5] "kPa" Vector__XXX

BO_ 2566649342 A1DOC2: 8 Vector__XXX
 SG_ Atttt1DsOxdtCtstItPss : 0|16@1+ (0.1,0) [0|6425.5] "kPa" Vector__XXX
 SG_ Atttt1DsOxdtCtstOttPss : 16|16@1+ (0.1,0) [0|6425.5] "kPa" Vector__XXX
 SG_ Atttt1DItTDpOttDtPss : 32|16@1+ (0.1,0) [0|6425.5] "kPa" Vector__XXX

BO_ 2566649598 VP2: 8 Vector__XXX
 SG_ HorizontalDilutionOfPrecision : 8|8@1+ (0.1,0) [0|25] "" Vector__XXX
 SG_ PositionDilutionOfPrecision : 24|8@1+ (0.1,0) [0|25] "" Vector__XXX
 SG_ TimeDilutionOfPrecision : 32|8@1+ (0.1,0) [0|25] "" Vector__XXX
 SG_ TotalNumberOfSatellitesInView : 0|8@1+ (1,0) [0|250] "count" Vector__XXX
 SG_ VerticalDilutionOfPrecision : 16|8@1+ (0.1,0) [0|25] "" Vector__XXX

BO_ 2566649854 EAPMCF3S1: 8 Vector__XXX
 SG_ PpsMtCtF3CtCdStts : 6|2@1+ (1,0) [0|3] "" Vector__XXX
 SG_ PpsMtCtF3CtSttsRsCd : 2|4@1+ (1,0) [0|15] "" Vector__XXX
 SG_ PropulsionMotorCoolantFan3Power : 40|16@1+ (0.5,0) [0|32127.5] "W" Vector__XXX
 SG_ PrplsnMtrClntFn3CntrlTmprtr : 24|16@1+ (0.03125,-273) [-273|1734.96875] "degC" Vector__XXX
 SG_ PrplsnMtrClntFn3MtrSpd : 8|16@1+ (0.5,0) [0|32127.5] "rpm" Vector__XXX
 SG_ PrplsnMtrClntFn3OprtngStts : 58|2@1+ (1,0) [0|3] "" Vector__XXX
 SG_ PrplsnMtrClntFn3SrvIndtr : 56|2@1+ (1,0) [0|3] "" Vector__XXX
 SG_ PrplsnMtrClntFn3MtrSpdStts : 0|2@1+ (1,0) [0|3] "" Vector__XXX

BO_ 2566650110 EAPMCF2S1: 8 Vector__XXX
 SG_ PpsMtCtF2CtCdStts : 6|2@1+ (1,0) [0|3] "" Vector__XXX
 SG_ PpsMtCtF2CtSttsRsCd : 2|4@1+ (1,0) [0|15] "" Vector__XXX
 SG_ PropulsionMotorCoolantFan2Power : 40|16@1+ (0.5,0) [0|32127.5] "W" Vector__XXX
 SG_ PrplsnMtrClntFn2CntrlTmprtr : 24|16@1+ (0.03125,-273) [-273|1734.96875] "degC" Vector__XXX
 SG_ PrplsnMtrClntFn2MtrSpd : 8|16@1+ (0.5,0) [0|32127.5] "rpm" Vector__XXX
 SG_ PrplsnMtrClntFn2OprtngStts : 58|2@1+ (1,0) [0|3] "" Vector__XXX
 SG_ PrplsnMtrClntFn2SrvIndtr : 56|2@1+ (1,0) [0|3] "" Vector__XXX
 SG_ PrplsnMtrClntFn2MtrSpdStts : 0|2@1+ (1,0) [0|3] "" Vector__XXX

BO_ 2566650366 EAPMCF1S1: 8 Vector__XXX
 SG_ PpsMtCtF1CtCdStts : 6|2@1+ (1,0) [0|3] "" Vector__XXX
 SG_ PpsMtCtF1CtSttsRsCd : 2|4@1+ (1,0) [0|15] "" Vector__XXX
 SG_ PropulsionMotorCoolantFan1Power : 40|16@1+ (0.5,0) [0|32127.5] "W" Vector__XXX
 SG_ PrplsnMtrClntFn1CntrlTmprtr : 24|16@1+ (0.03125,-273) [-273|1734.96875] "degC" Vector__XXX
 SG_ PrplsnMtrClntFn1MtrSpd : 8|16@1+ (0.5,0) [0|32127.5] "rpm" Vector__XXX
 SG_ PrplsnMtrClntFn1OprtngStts : 58|2@1+ (1,0) [0|3] "" Vector__XXX
 SG_ PrplsnMtrClntFn1SrvIndtr : 56|2@1+ (1,0) [0|3] "" Vector__XXX
 SG_ PrplsnMtrClntFn1MtrSpdStts : 0|2@1+ (1,0) [0|3] "" Vector__XXX

BO_ 2566650622 EAPECF3S1: 8 Vector__XXX
 SG_ PwEtsCtF3CtCdStts : 6|2@1+ (1,0) [0|3] "" Vector__XXX
 SG_ PwEtsCtF3CtSttsRsCd : 2|4@1+ (1,0) [0|15] "" Vector__XXX
 SG_ PwrEltrnsClntFn3CntrlTmprtr : 24|16@1+ (0.03125,-273) [-273|1734.96875] "degC" Vector__XXX
 SG_ PwrEltrnsClntFn3MtrSpd : 8|16@1+ (0.5,0) [0|32127.5] "rpm" Vector__XXX
 SG_ PwrEltrnsClntFn3OprtngStts : 58|2@1+ (1,0) [0|3] "" Vector__XXX
 SG_ PwrEltrnsClntFn3Pwr : 40|16@1+ (0.5,0) [0|32127.5] "W" Vector__XXX
 SG_ PwrEltrnsClntFn3SrvIndtr : 56|2@1+ (1,0) [0|3] "" Vector__XXX
 SG_ PwrEltrnsClntFn3MtrSpdStts : 0|2@1+ (1,0) [0|3] "" Vector__XXX

BO_ 2566650878 EAPECF2S1: 8 Vector__XXX
 SG_ PwEtsCtF2CtCdStts : 6|2@1+ (1,0) [0|3] "" Vector__XXX
 SG_ PwEtsCtF2CtSttsRsCd : 2|4@1+ (1,0) [0|15] "" Vector__XXX
 SG_ PwrEltrnsClntFn2CntrlTmprtr : 24|16@1+ (0.03125,-273) [-273|1734.96875] "degC" Vector__XXX
 SG_ PwrEltrnsClntFn2MtrSpd : 8|16@1+ (0.5,0) [0|32127.5] "rpm" Vector__XXX
 SG_ PwrEltrnsClntFn2OprtngStts : 58|2@1+ (1,0) [0|3] "" Vector__XXX
 SG_ PwrEltrnsClntFn2Pwr : 40|16@1+ (0.5,0) [0|32127.5] "W" Vector__XXX
 SG_ PwrEltrnsClntFn2SrvIndtr : 56|2@1+ (1,0) [0|3] "" Vector__XXX
 SG_ PwrEltrnsClntFn2MtrSpdStts : 0|2@1+ (1,0) [0|3] "" Vector__XXX

BO_ 2566651134 EAPECF1S1: 8 Vector__XXX
 SG_ PwEtsCtF1CtCdStts : 6|2@1+ (1,0) [0|3] "" Vector__XXX
 SG_ PwEtsCtF1CtSttsRsCd : 2|4@1+ (1,0) [0|15] "" Vector__XXX
 SG_ PwrEltrnsClntFn1CntrlTmprtr : 24|16@1+ (0.03125,-273) [-273|1734.96875] "degC" Vector__XXX
 SG_ PwrEltrnsClntFn1MtrSpd : 8|16@1+ (0.5,0) [0|32127.5] "rpm" Vector__XXX
 SG_ PwrEltrnsClntFn1OprtngStts : 58|2@1+ (1,0) [0|3] "" Vector__XXX
 SG_ PwrEltrnsClntFn1Pwr : 40|16@1+ (0.5,0) [0|32127.5] "W" Vector__XXX
 SG_ PwrEltrnsClntFn1SrvIndtr : 56|2@1+ (1,0) [0|3] "" Vector__XXX
 SG_ PwrEltrnsClntFn1MtrSpdStts : 0|2@1+ (1,0) [0|3] "" Vector__XXX

BO_ 2566651390 EAPMOPS1: 8 Vector__XXX
 SG_ PropulsionMotorOilPumpPower : 40|16@1+ (0.5,0) [0|32127.5] "W" Vector__XXX
 SG_ PrplsnMtrOlPmpCntrllrCmmndStts : 6|2@1+ (1,0) [0|3] "" Vector__XXX
 SG_ PrplsnMtrOlPmpCntrllrSttsRsnCd : 2|4@1+ (1,0) [0|15] "" Vector__XXX
 SG_ PrplsnMtrOlPmpCntrlTmprtr : 24|16@1+ (0.03125,-273) [-273|1734.96875] "degC" Vector__XXX
 SG_ PrplsnMtrOlPmpMtrSpd : 8|16@1+ (0.5,0) [0|32127.5] "rpm" Vector__XXX
 SG_ PrplsnMtrOlPmpOprtngStts : 58|2@1+ (1,0) [0|3] "" Vector__XXX
 SG_ PrplsnMtrOlPmpSrvIndtr : 56|2@1+ (1,0) [0|3] "" Vector__XXX
 SG_ PrplsnMtrOlPmpMtrSpdStts : 0|2@1+ (1,0) [0|3] "" Vector__XXX

BO_ 2566651646 EAPMCPS1: 8 Vector__XXX
 SG_ PpsMtCtPpCtCdStts : 6|2@1+ (1,0) [0|3] "" Vector__XXX
 SG_ PpsMtCtPpCtSttsRsCd : 2|4@1+ (1,0) [0|15] "" Vector__XXX
 SG_ PropulsionMotorCoolantPumpPower : 40|16@1+ (0.5,0) [0|32127.5] "W" Vector__XXX
 SG_ PrplsnMtrClntPmpCntrlTmprtr : 24|16@1+ (0.03125,-273) [-273|1734.96875] "degC" Vector__XXX
 SG_ PrplsnMtrClntPmpMtrSpd : 8|16@1+ (0.5,0) [0|32127.5] "rpm" Vector__XXX
 SG_ PrplsnMtrClntPmpOprtngStts : 58|2@1+ (1,0) [0|3] "" Vector__XXX
 SG_ PrplsnMtrClntPmpSrvIndtr : 56|2@1+ (1,0) [0|3] "" Vector__XXX
 SG_ PrplsnMtrClntPmpMtrSpdStts : 0|2@1+ (1,0) [0|3] "" Vector__XXX

BO_ 2566651902 EAPECPS1: 8 Vector__XXX
 SG_ PwEtsCtPpCtCdStts : 6|2@1+ (1,0) [0|3] "" Vector__XXX
 SG_ PwEtsCtPpCtSttsRsCd : 2|4@1+ (1,0) [0|15] "" Vector__XXX
 SG_ PwrEltrnsClntPmpCntrlTmprtr : 24|16@1+ (0.03125,-273) [-273|1734.96875] "degC" Vector__XXX
 SG_ PwrEltrnsClntPmpMtrSpd : 8|16@1+ (0.5,0) [0|32127.5] "rpm" Vector__XXX
 SG_ PwrEltrnsClntPmpOprtngStts : 58|2@1+ (1,0) [0|3] "" Vector__XXX
 SG_ PwrEltrnsClntPmpPwr : 40|16@1+ (0.5,0) [0|32127.5] "W" Vector__XXX
 SG_ PwrEltrnsClntPmpSrvIndtr : 56|2@1+ (1,0) [0|3] "" Vector__XXX
 SG_ PwrEltrnsClntPmpMtrSpdStts : 0|2@1+ (1,0) [0|3] "" Vector__XXX

BO_ 2566652414 EAMS1: 8 Vector__XXX
 SG_ ElectrifiedAccessoryMotorPower : 40|16@1+ (0.5,0) [0|32127.5] "W" Vector__XXX
 SG_ ElectrifiedAccessoryMotorSpeed : 8|16@1+ (0.5,0) [0|32127.5] "rpm" Vector__XXX
 SG_ EltrfdAssrMtrCntrllrCmmndStts : 6|2@1+ (1,0) [0|3] "" Vector__XXX
 SG_ EltrfdAssrMtrCntrllrSttsRsnCd : 2|4@1+ (1,0) [0|15] "" Vector__XXX
 SG_ EltrfdAssrMtrMdmTmprtr : 24|16@1+ (0.03125,-273) [-273|1734.96875] "degC" Vector__XXX
 SG_ EltrfdAssrMtrOprtngStts : 58|2@1+ (1,0) [0|3] "" Vector__XXX
 SG_ EltrfdAssrMtrSrvIndtr : 56|2@1+ (1,0) [0|3] "" Vector__XXX
 SG_ EltrfdAssrMtrInstnOfSttsDtSt1 : 60|4@1+ (1,0) [0|15] "" Vector__XXX
 SG_ EltrfdAssrMtrSpdStts : 0|2@1+ (1,0) [0|3] "" Vector__XXX

BO_ 2566652670 SCRSI: 8 Vector__XXX
 SG_ Atttt1DsExstFdDsSstFz : 40|2@1+ (1,0) [0|3] "" Vector__XXX
 SG_ Atttt2DsExstFdDsSstFz : 42|2@1+ (1,0) [0|3] "" Vector__XXX
 SG_ DieselExhaustFluidFrozenTime : 0|32@1+ (1,0) [0|4211081215] "s" Vector__XXX
 SG_ Aftrtrtmnt1SstmHdrrn : 32|8@1+ (1,0) [0|250] "%" Vector__XXX
 SG_ Aftrtrtmnt2SstmHdrrn : 48|8@1+ (1,0) [0|250] "%" Vector__XXX

BO_ 2566652926 VEP14: 8 Vector__XXX
 SG_ SliBatteryPack1Battery4Capacity : 16|16@1+ (1,0) [0|64255] "Ah" Vector__XXX
 SG_ SliBatteryPack1Battery4Health : 32|8@1+ (0.5,0) [0|125] "%" Vector__XXX
 SG_ SlBttrPk1Bttr4SttOfChrg : 0|16@1+ (0.0025,0) [0|160.6375] "%" Vector__XXX
 SG_ SBttP1Btt4PdtdMCVt : 40|8@1+ (0.2,0) [0|50] "V" Vector__XXX
 SG_ SlBttrPk1Snsr4IntlztnStts : 48|4@1+ (1,0) [0|15] "" Vector__XXX

BO_ 2566653182 VEP13: 8 Vector__XXX
 SG_ SliBatteryPack1Battery4Voltage : 24|16@1+ (0.05,0) [0|3212.75] "V" Vector__XXX
 SG_ SlBttrPk1Bttr4NtCrrnt : 0|16@1+ (0.05,-1600) [-1600|1612.75] "A" Vector__XXX
 SG_ SlBttrPk1Bttr4Tmprtr : 16|8@1+ (1,-40) [-40|210] "degC" Vector__XXX

BO_ 2566653438 VEP12: 8 Vector__XXX
 SG_ SliBatteryPack1Battery3Capacity : 16|16@1+ (1,0) [0|64255] "Ah" Vector__XXX
 SG_ SliBatteryPack1Battery3Health : 32|8@1+ (0.5,0) [0|125] "%" Vector__XXX
 SG_ SlBttrPk1Bttr3SttOfChrg : 0|16@1+ (0.0025,0) [0|160.6375] "%" Vector__XXX
 SG_ SBttP1Btt3PdtdMCVt : 40|8@1+ (0.2,0) [0|50] "V" Vector__XXX
 SG_ SlBttrPk1Snsr3IntlztnStts : 48|4@1+ (1,0) [0|15] "" Vector__XXX

BO_ 2566653694 VEP11: 8 Vector__XXX
 SG_ SliBatteryPack1Battery3Voltage : 24|16@1+ (0.05,0) [0|3212.75] "V" Vector__XXX
 SG_ SlBttrPk1Bttr3NtCrrnt : 0|16@1+ (0.05,-1600) [-1600|1612.75] "A" Vector__XXX
 SG_ SlBttrPk1Bttr3Tmprtr : 16|8@1+ (1,-40) [-40|210] "degC" Vector__XXX

BO_ 2566653950 VEP10: 8 Vector__XXX
 SG_ SliBatteryPack1Battery2Capacity : 16|16@1+ (1,0) [0|64255] "Ah" Vector__XXX
 SG_ SliBatteryPack1Battery2Health : 32|8@1+ (0.5,0) [0|125] "%" Vector__XXX
 SG_ SlBttrPk1Bttr2SttOfChrg : 0|16@1+ (0.0025,0) [0|160.6375] "%" Vector__XXX
 SG_ SBttP1Btt2PdtdMCVt : 40|8@1+ (0.2,0) [0|50] "V" Vector__XXX
 SG_ SlBttrPk1Snsr2IntlztnStts : 48|4@1+ (1,0) [0|15] "" Vector__XXX

BO_ 2566654206 VEP9: 8 Vector__XXX
 SG_ SliBatteryPack1Battery2Voltage : 24|16@1+ (0.05,0) [0|3212.75] "V" Vector__XXX
 SG_ SlBttrPk1Bttr2NtCrrnt : 0|16@1+ (0.05,-1600) [-1600|1612.75] "A" Vector__XXX
 SG_ SlBttrPk1Bttr2Tmprtr : 16|8@1+ (1,-40) [-40|210] "degC" Vector__XXX

BO_ 2566654462 VEP8: 8 Vector__XXX
 SG_ SliBatteryPack1Battery1Capacity : 16|16@1+ (1,0) [0|64255] "Ah" Vector__XXX
 SG_ SliBatteryPack1Battery1Health : 32|8@1+ (0.5,0) [0|125] "%" Vector__XXX
 SG_ SlBttrPk1Bttr1SttOfChrg : 0|16@1+ (0.0025,0) [0|160.6375] "%" Vector__XXX
 SG_ SBttP1Btt1PdtdMCVt : 40|8@1+ (0.2,0) [0|50] "V" Vector__XXX
 SG_ SlBttrPk1Snsr1IntlztnStts : 48|4@1+ (1,0) [0|15] "" Vector__XXX

BO_ 2566654718 VEP7: 8 Vector__XXX
 SG_ SliBatteryPack1Battery1Voltage : 24|16@1+ (0.05,0) [0|3212.75] "V" Vector__XXX
 SG_ SlBttrPk1Bttr1NtCrrnt : 0|16@1+ (0.05,-1600) [-1600|1612.75] "A" Vector__XXX
 SG_ SlBttrPk1Bttr1Tmprtr : 16|8@1+ (1,-40) [-40|210] "degC" Vector__XXX

BO_ 2566654974 EEC20: 8 Vector__XXX
 SG_ AtlMxmmAvllEngnPrntFl : 16|8@1+ (0.4,0) [0|100] "%" Vector__XXX
 SG_ EsttdEPstLsssPtTqHRst : 0|16@1+ (0.0015625,0) [0|100.3984375] "%" Vector__XXX
 SG_ NmnlFrtnPrntTrqHghRsltn : 24|16@1+ (0.0015625,0) [0|100.3984375] "%" Vector__XXX
 SG_ AsltEngnLdPrntArMss : 40|16@1+ (0.025,0) [0|1606.375] "%" Vector__XXX

BO_ 2566655742 PHRPS: 8 Vector__XXX
 SG_ RearHitchPitchSensitivity : 8|8@1+ (0.4,0) [0|100] "%" Vector__XXX
 SG_ RearHitchRollSensitivity : 0|8@1+ (0.4,0) [0|100] "%" Vector__XXX

BO_ 2566656254 AMB3: 8 Vector__XXX
 SG_ BarometricAbsolutePressure2 : 0|16@1+ (0.1,0) [0|6425.5] "kPa" Vector__XXX
 SG_ EngineIntake2AirTemperature : 16|8@1+ (1,-40) [-40|210] "degC" Vector__XXX
 SG_ EngnPwrDrtRltvHmdtDffrn : 24|16@1+ (0.01,-321.27) [-100|100] "%" Vector__XXX

BO_ 2566656510 TGFI: 8 Vector__XXX
 SG_ EngnTtlGssFlVlmUsd : 0|32@1+ (0.5,0) [0|2105540607.5] "m*m*m" Vector__XXX
 SG_ EngnTtlGssIdlFlVlmUsd : 32|32@1+ (0.5,0) [0|2105540607.5] "m*m*m" Vector__XXX

BO_ 2566658302 PLST2: 8 Vector__XXX
 SG_ TotalPayloadTransactionCount : 0|32@1+ (1,0) [0|4211081215] "count" Vector__XXX

BO_ 2566658558 PLST1: 8 Vector__XXX
 SG_ TotalDeliveredPayloadWeight : 0|32@1+ (100,0) [0|421108121500] "kg" Vector__XXX
 SG_ TotalHaulCycleCount : 32|32@1+ (1,0) [0|4211081215] "count" Vector__XXX

BO_ 2566661118 LFC2: 8 Vector__XXX
 SG_ EngineTotalDieselFuelDemand : 0|32@1+ (0.5,0) [0|2105540607.5] "l" Vector__XXX

BO_ 2566661374 AT2T1I2: 8 Vector__XXX
 SG_ Aftrtrtmnt2DslExhstFldTnkHtr2 : 16|8@1+ (0.4,0) [0|100] "%" Vector__XXX
 SG_ Aftrtrtmnt2DslExhstFldTnkVlm2 : 0|8@1+ (0.4,0) [0|100] "%" Vector__XXX
 SG_ Atttt2DsExstFdTTpt2 : 8|8@1+ (1,-40) [-40|210] "degC" Vector__XXX

BO_ 2566661630 AT1T1I2: 8 Vector__XXX
 SG_ Aftrtrtmnt1DslExhstFldTnkHtr2 : 16|8@1+ (0.4,0) [0|100] "%" Vector__XXX
 SG_ Aftrtrtmnt1DslExhstFldTnkVlm2 : 0|8@1+ (0.4,0) [0|100] "%" Vector__XXX
 SG_ Atttt1DsExstFdTTpt2 : 8|8@1+ (1,-40) [-40|210] "degC" Vector__XXX

BO_ 2566661886 A2DEFI2: 8 Vector__XXX
 SG_ Atttt2DsExstFdCt2Tpt : 8|8@1+ (1,-40) [-40|210] "degC" Vector__XXX
 SG_ Atttt2DsExstFdCtTpt : 0|8@1+ (1,-40) [-40|210] "degC" Vector__XXX

BO_ 2566662142 A1DEFI2: 8 Vector__XXX
 SG_ Atttt1DsExstFdCt1Tpt : 0|8@1+ (1,-40) [-40|210] "degC" Vector__XXX
 SG_ Atttt1DsExstFdCt2Tpt : 8|8@1+ (1,-40) [-40|210] "degC" Vector__XXX

BO_ 2566662654 FLI3: 8 Vector__XXX
 SG_ LaneDepartureAngleLeft : 32|8@1+ (0.1,-12.5) [-12.5|12.5] "deg" Vector__XXX
 SG_ LaneDepartureAngleRight : 40|8@1+ (0.1,-12.5) [-12.5|12.5] "deg" Vector__XXX
 SG_ LaneMarkQualityOnTheLeftSide : 48|3@1+ (1,0) [0|7] "" Vector__XXX
 SG_ LaneMarkQualityOnTheRightSide : 51|3@1+ (1,0) [0|7] "" Vector__XXX
 SG_ LeftLaneMarkerType : 60|4@1+ (1,0) [0|15] "" Vector__XXX
 SG_ LftDstnTLnMrkFrmVhlSMddl : 0|8@1+ (0.02,0) [0|5] "m" Vector__XXX
 SG_ RghtDstnTLnMrkFrmVhlSMddl : 8|8@1+ (0.02,0) [0|5] "m" Vector__XXX
 SG_ RightLaneMarkerType : 56|4@1+ (1,0) [0|15] "" Vector__XXX
 SG_ RoadCurvatureBasedOnLaneMarks : 16|16@1+ (0.0078125,-250) [-250|251.9921875] "1/km" Vector__XXX

BO_ 2566662910 OII1: 8 Vector__XXX
 SG_ OprtrIndmntTmTFnlIndmntAtn : 48|16@1+ (1,0) [0|64255] "min" Vector__XXX
 SG_ OprtrIndmntTmTTrqDrtLvl1 : 8|16@1+ (1,0) [0|64255] "min" Vector__XXX
 SG_ OprtrIndmntTmTTrqDrtLvl2 : 32|16@1+ (1,0) [0|64255] "min" Vector__XXX
 SG_ OprtrIndmntTrqDrtLvl1 : 0|8@1+ (1,0) [0|250] "%" Vector__XXX
 SG_ OprtrIndmntTrqDrtLvl2 : 24|8@1+ (1,0) [0|250] "%" Vector__XXX

BO_ 2566663166 CCVS4: 8 Vector__XXX
 SG_ AppldVhlSpdLmtHghRsltn : 0|16@1+ (0.00390625,0) [0|250.99609375] "km/h" Vector__XXX
 SG_ CrsCntrlAdjstdMxmmSpd : 16|16@1+ (0.00390625,0) [0|250.99609375] "km/h" Vector__XXX
 SG_ EngnExtrnlIdlRqstFdk : 32|2@1+ (1,0) [0|3] "" Vector__XXX
 SG_ SAddssOCtDvFSttCsCt : 40|8@1+ (1,0) [0|250] "sourceadr" Vector__XXX

BO_ 2566663422 BCLC: 8 Vector__XXX
 SG_ TrlrBrkClprLnngClrnAxl1Lft : 20|2@1+ (1,0) [0|3] "" Vector__XXX
 SG_ TrlrBrkClprLnngClrnAxl1Rght : 22|2@1+ (1,0) [0|3] "" Vector__XXX
 SG_ TrlrBrkClprLnngClrnAxl2Lft : 24|2@1+ (1,0) [0|3] "" Vector__XXX
 SG_ TrlrBrkClprLnngClrnAxl2Rght : 26|2@1+ (1,0) [0|3] "" Vector__XXX
 SG_ TrlrBrkClprLnngClrnAxl3Lft : 28|2@1+ (1,0) [0|3] "" Vector__XXX
 SG_ TrlrBrkClprLnngClrnAxl3Rght : 30|2@1+ (1,0) [0|3] "" Vector__XXX
 SG_ TrlrBrkClprLnngClrnAxl4Lft : 32|2@1+ (1,0) [0|3] "" Vector__XXX
 SG_ TrlrBrkClprLnngClrnAxl4Rght : 34|2@1+ (1,0) [0|3] "" Vector__XXX
 SG_ TrlrBrkClprLnngClrnAxl5Lft : 36|2@1+ (1,0) [0|3] "" Vector__XXX
 SG_ TrlrBrkClprLnngClrnAxl5Rght : 38|2@1+ (1,0) [0|3] "" Vector__XXX
 SG_ TrtrBrkClprLnngClrnAxl1Lft : 0|2@1+ (1,0) [0|3] "" Vector__XXX
 SG_ TrtrBrkClprLnngClrnAxl1Rght : 2|2@1+ (1,0) [0|3] "" Vector__XXX
 SG_ TrtrBrkClprLnngClrnAxl2Lft : 4|2@1+ (1,0) [0|3] "" Vector__XXX
 SG_ TrtrBrkClprLnngClrnAxl2Rght : 6|2@1+ (1,0) [0|3] "" Vector__XXX
 SG_ TrtrBrkClprLnngClrnAxl3Lft : 8|2@1+ (1,0) [0|3] "" Vector__XXX
 SG_ TrtrBrkClprLnngClrnAxl3Rght : 10|2@1+ (1,0) [0|3] "" Vector__XXX
 SG_ TrtrBrkClprLnngClrnAxl4Lft : 12|2@1+ (1,0) [0|3] "" Vector__XXX
 SG_ TrtrBrkClprLnngClrnAxl4Rght : 14|2@1+ (1,0) [0|3] "" Vector__XXX
 SG_ TrtrBrkClprLnngClrnAxl5Lft : 16|2@1+ (1,0) [0|3] "" Vector__XXX
 SG_ TrtrBrkClprLnngClrnAxl5Rght : 18|2@1+ (1,0) [0|3] "" Vector__XXX

BO_ 2566663678 AF5: 8 Vector__XXX
 SG_ EngnFl2InjtrMtrngRl1Tmprtr2 : 32|8@1+ (1,-40) [-40|210] "degC" Vector__XXX
 SG_ LngTank1VaporPressure : 0|16@1+ (0.1,0) [0|6425.5] "kPa" Vector__XXX
 SG_ LngTank2VaporPressure : 16|16@1+ (0.1,0) [0|6425.5] "kPa" Vector__XXX

BO_ 2566663934 ETCC3: 8 Vector__XXX
 SG_ EngnClndrHdBpssAttr1MtrCrrntDsl : 4|2@1+ (1,0) [0|3] "" Vector__XXX
 SG_ EngnThrttlVlv1MtrCrrntDsl : 6|2@1+ (1,0) [0|3] "" Vector__XXX
 SG_ EngnTrhrgrWstgtAttr1MtrCrrntDsl : 2|2@1+ (1,0) [0|3] "" Vector__XXX
 SG_ EngnTrhrgrWstgtAttr2MtrCrrntDsl : 12|2@1+ (1,0) [0|3] "" Vector__XXX
 SG_ ETCpssBpssAtt1MtCtDs : 8|2@1+ (1,0) [0|3] "" Vector__XXX
 SG_ ETCpssBpssAtt2MtCtDs : 10|2@1+ (1,0) [0|3] "" Vector__XXX
 SG_ ETCpssBwAtt1MtCtDs : 0|2@1+ (1,0) [0|3] "" Vector__XXX

BO_ 2566664702 ASI1: 8 Vector__XXX
 SG_ AftertreatmentEngineLoadRequest : 6|2@1+ (1,0) [0|3] "" Vector__XXX
 SG_ AftrtrtmntAmntArTmprtr : 8|16@1+ (0.03125,-273) [-273|1734.96875] "degC" Vector__XXX
 SG_ AftrtrtmntDslExhstFldHtrCrtBrkr : 24|2@1+ (1,0) [0|3] "" Vector__XXX
 SG_ AftrtrtmntDslExhstFldTnkTmprtr : 40|8@1+ (1,-40) [-40|210] "degC" Vector__XXX
 SG_ AftrtrtmntDslExhstFldTnkVlm : 32|8@1+ (0.4,0) [0|100] "%" Vector__XXX
 SG_ AftrtrtmntEngnSpdInrsRqst : 4|2@1+ (1,0) [0|3] "" Vector__XXX
 SG_ AftrtrtmntThrmlMngmntStts : 0|2@1+ (1,0) [0|3] "" Vector__XXX
 SG_ AttttAtvRtItdDTLwExstPss : 2|2@1+ (1,0) [0|3] "" Vector__XXX
 SG_ DslExhstFldQltMlfntnEvltnPrdAtv : 26|2@1+ (1,0) [0|3] "" Vector__XXX
 SG_ DpfAtvRgnrtnTmRmnng : 48|8@1+ (1,0) [0|250] "min" Vector__XXX
 SG_ AftrtrtmntSrDsngMdStts : 28|3@1+ (1,0) [0|7] "" Vector__XXX
 SG_ EngnExhstSstmHdrrnDsrMdStts : 56|3@1+ (1,0) [0|7] "" Vector__XXX
 SG_ Aftrtrtmnt1HdrrnLdLvlStts : 59|3@1+ (1,0) [0|7] "" Vector__XXX

BO_ 2566665726 AT2P1I: 8 Vector__XXX
 SG_ Aftrtrtmnt2DslExhstFldPmpHtr : 0|8@1+ (0.4,0) [0|100] "%" Vector__XXX
 SG_ Atttt2DsExstFdPp2MtSpd : 8|16@1+ (0.5,0) [0|32127.5] "rpm" Vector__XXX

BO_ 2566667262 EEBT3: 8 Vector__XXX
 SG_ EngineEndBearing17Temperature : 0|8@1+ (1,-40) [-40|210] "degC" Vector__XXX
 SG_ EngineEndBearing18Temperature : 8|8@1+ (1,-40) [-40|210] "degC" Vector__XXX
 SG_ EngineEndBearing19Temperature : 16|8@1+ (1,-40) [-40|210] "degC" Vector__XXX
 SG_ EngineEndBearing20Temperature : 24|8@1+ (1,-40) [-40|210] "degC" Vector__XXX

BO_ 2566667518 EEBT2: 8 Vector__XXX
 SG_ EngineEndBearing10Temperature : 8|8@1+ (1,-40) [-40|210] "degC" Vector__XXX
 SG_ EngineEndBearing11Temperature : 16|8@1+ (1,-40) [-40|210] "degC" Vector__XXX
 SG_ EngineEndBearing12Temperature : 24|8@1+ (1,-40) [-40|210] "degC" Vector__XXX
 SG_ EngineEndBearing13Temperature : 32|8@1+ (1,-40) [-40|210] "degC" Vector__XXX
 SG_ EngineEndBearing14Temperature : 40|8@1+ (1,-40) [-40|210] "degC" Vector__XXX
 SG_ EngineEndBearing15Temperature : 48|8@1+ (1,-40) [-40|210] "degC" Vector__XXX
 SG_ EngineEndBearing16Temperature : 56|8@1+ (1,-40) [-40|210] "degC" Vector__XXX
 SG_ EngineEndBearing9Temperature : 0|8@1+ (1,-40) [-40|210] "degC" Vector__XXX

BO_ 2566667774 EEBT1: 8 Vector__XXX
 SG_ EngineEndBearing1Temperature : 0|8@1+ (1,-40) [-40|210] "degC" Vector__XXX
 SG_ EngineEndBearing2Temperature : 8|8@1+ (1,-40) [-40|210] "degC" Vector__XXX
 SG_ EngineEndBearing3Temperature : 16|8@1+ (1,-40) [-40|210] "degC" Vector__XXX
 SG_ EngineEndBearing4Temperature : 24|8@1+ (1,-40) [-40|210] "degC" Vector__XXX
 SG_ EngineEndBearing5Temperature : 32|8@1+ (1,-40) [-40|210] "degC" Vector__XXX
 SG_ EngineEndBearing6Temperature : 40|8@1+ (1,-40) [-40|210] "degC" Vector__XXX
 SG_ EngineEndBearing7Temperature : 48|8@1+ (1,-40) [-40|210] "degC" Vector__XXX
 SG_ EngineEndBearing8Temperature : 56|8@1+ (1,-40) [-40|210] "degC" Vector__XXX

BO_ 2566668030 HEDPI: 8 Vector__XXX
 SG_ HeatExchangerDebrisPurgeStatus : 0|2@1+ (1,0) [0|3] "" Vector__XXX
 SG_ HtExhngrDrsPrgApprhng : 2|2@1+ (1,0) [0|3] "" Vector__XXX

BO_ 2566668286 ETCC2: 8 Vector__XXX
 SG_ EngnStgdTrhrgrSlndStts : 0|8@1+ (0.4,0) [0|100] "%" Vector__XXX
 SG_ NmrOfEngnTrhrgrsCmmndd : 8|4@1+ (1,0) [0|13] "count" Vector__XXX

BO_ 2566668542 EHF2PC: 8 Vector__XXX
 SG_ EngnFl2PmpHdrlDrtnlVlv : 16|8@1+ (0.4,0) [0|100] "%" Vector__XXX
 SG_ EngnFl2PmpHdrlFlwCntrlVlv : 0|8@1+ (0.4,0) [0|100] "%" Vector__XXX
 SG_ EngnFl2PmpHdrlPrssr : 24|16@1+ (2,0) [0|128510] "kPa" Vector__XXX
 SG_ EngnFl2PmpHdrlSwshPltAngl : 8|8@1+ (0.4,0) [0|100] "%" Vector__XXX

BO_ 2566668798 AF4: 8 Vector__XXX
 SG_ EngnFl2InjtrMtrngRl1Prssr : 0|16@1+ (2,0) [0|128510] "kPa" Vector__XXX
 SG_ EngnFl2InjtrMtrngRl1Prssr2 : 48|16@1+ (2,0) [0|128510] "kPa" Vector__XXX
 SG_ EngnFl2InjtrMtrngRl1Tmprtr : 32|8@1+ (1,-40) [-40|210] "degC" Vector__XXX
 SG_ EngnFl2InjtrMtrngRl2Prssr : 16|16@1+ (2,0) [0|128510] "kPa" Vector__XXX
 SG_ EngnFl2InjtrMtrngRl2Tmprtr : 40|8@1+ (1,-40) [-40|210] "degC" Vector__XXX

BO_ 2566669054 TIRE2: 8 Vector__XXX
 SG_ RequiredTirePressure : 24|16@1+ (1,0) [0|64255] "kPa" Vector__XXX
 SG_ TireLocation : 0|8@1+ (1,0) [0|250] "" Vector__XXX
 SG_ TirePressureExtendedRange : 8|16@1+ (1,0) [0|64255] "kPa" Vector__XXX

BO_ 2566669310 TCSI: 8 Vector__XXX
 SG_ ColdInflationPressure : 8|16@1+ (1,0) [0|64255] "kPa" Vector__XXX
 SG_ ExtrmUndrPrssrPrntgThrshld : 32|8@1+ (0.5,0) [0|125] "%" Vector__XXX
 SG_ OverPressurePercentageThreshold : 40|8@1+ (0.5,0) [0|125] "%" Vector__XXX
 SG_ OverTemperature : 48|8@1+ (1,-40) [-40|210] "degC" Vector__XXX
 SG_ TireLocation : 0|8@1+ (1,0) [0|250] "" Vector__XXX
 SG_ UndrPrssrPrntgThrshld : 24|8@1+ (0.5,0) [0|125] "%" Vector__XXX

BO_ 2566669822 TWSSI: 6 Vector__XXX
 SG_ AntennaNumber : 8|8@1+ (1,0) [0|250] "count" Vector__XXX
 SG_ TireLocation : 32|8@1+ (1,0) [0|250] "" Vector__XXX
 SG_ TireSensorNumber : 24|8@1+ (1,0) [0|250] "count" Vector__XXX
 SG_ TotalNumberOfAntennasUsed : 0|8@1+ (1,0) [0|250] "count" Vector__XXX
 SG_ TrWrlssSgnlStrngthIndtr : 40|8@1+ (0.5,-125) [-125|0] "dBm" Vector__XXX
 SG_ TtlNmrOfTrSnsrsMntrd : 16|8@1+ (1,0) [0|250] "count" Vector__XXX

BO_ 2566670078 TSIS: 8 Vector__XXX
 SG_ NumberOfTireSensors : 0|8@1+ (1,0) [0|250] "count" Vector__XXX
 SG_ TireLocation : 16|8@1+ (1,0) [0|250] "count" Vector__XXX
 SG_ TireNumber : 8|8@1+ (1,0) [0|250] "count" Vector__XXX

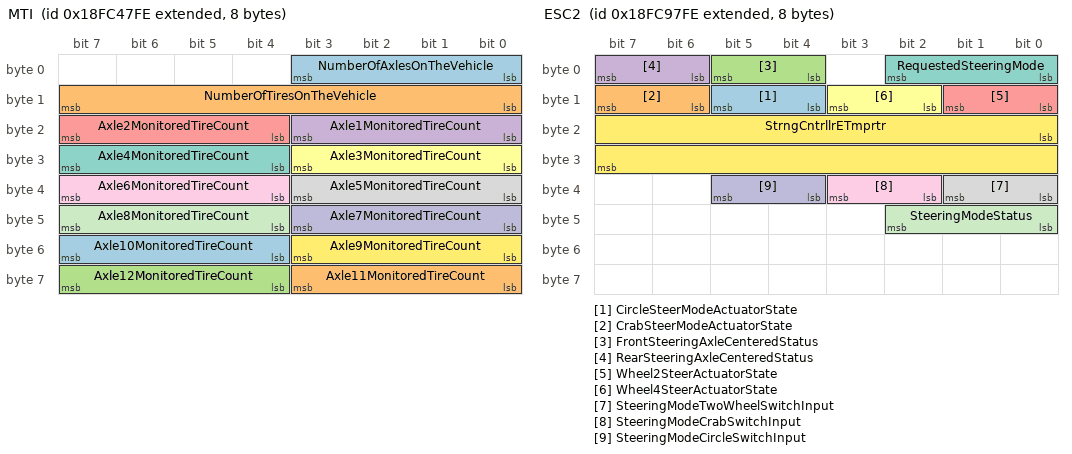
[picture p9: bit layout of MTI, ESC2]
BO_ 2566670334 MTI: 8 Vector__XXX
 SG_ Axle10MonitoredTireCount : 52|4@1+ (1,0) [0|13] "count" Vector__XXX
 SG_ Axle11MonitoredTireCount : 56|4@1+ (1,0) [0|13] "count" Vector__XXX
 SG_ Axle12MonitoredTireCount : 60|4@1+ (1,0) [0|13] "count" Vector__XXX
 SG_ Axle1MonitoredTireCount : 16|4@1+ (1,0) [0|13] "count" Vector__XXX
 SG_ Axle2MonitoredTireCount : 20|4@1+ (1,0) [0|13] "count" Vector__XXX
 SG_ Axle3MonitoredTireCount : 24|4@1+ (1,0) [0|13] "count" Vector__XXX
 SG_ Axle4MonitoredTireCount : 28|4@1+ (1,0) [0|13] "count" Vector__XXX
 SG_ Axle5MonitoredTireCount : 32|4@1+ (1,0) [0|13] "count" Vector__XXX
 SG_ Axle6MonitoredTireCount : 36|4@1+ (1,0) [0|13] "count" Vector__XXX
 SG_ Axle7MonitoredTireCount : 40|4@1+ (1,0) [0|13] "count" Vector__XXX
 SG_ Axle8MonitoredTireCount : 44|4@1+ (1,0) [0|13] "count" Vector__XXX
 SG_ Axle9MonitoredTireCount : 48|4@1+ (1,0) [0|13] "count" Vector__XXX
 SG_ NumberOfAxlesOnTheVehicle : 0|4@1+ (1,0) [0|13] "count" Vector__XXX
 SG_ NumberOfTiresOnTheVehicle : 8|8@1+ (1,0) [0|250] "count" Vector__XXX

BO_ 2566670590 AT2HI2: 24 Vector__XXX
 SG_ Aftrtrtmnt2SrSstmTtlSstmClnngTm : 0|32@1+ (1,0) [0|4211081215] "s" Vector__XXX
 SG_ Atttt2SSstTtNOSstCEvts : 32|32@1+ (1,0) [0|4211081215] "count" Vector__XXX
 SG_ Atttt2SSstTtNOSstCItRqsts : 64|32@1+ (1,0) [0|4211081215] "count" Vector__XXX
 SG_ Atttt2SSstTtNOSstCMRqsts : 96|32@1+ (1,0) [0|4211081215] "count" Vector__XXX
 SG_ Atttt2SSstAvTBtwSstCEvts : 128|32@1+ (1,0) [0|4211081215] "s" Vector__XXX
 SG_ Atttt2SSstAvDstBtwSstCEvts : 160|32@1+ (0.125,0) [0|526385151.875] "km" Vector__XXX

BO_ 2566670846 AT1HI2: 28 Vector__XXX
 SG_ TtlAftrtrtmntOprtngHrs : 192|32@1+ (1,0) [0|4211081215] "s" Vector__XXX
 SG_ Aftrtrtmnt1SrSstmTtlClnngTm : 0|32@1+ (1,0) [0|4211081215] "s" Vector__XXX
 SG_ Atttt1SSstTtNOSstCEvts : 32|32@1+ (1,0) [0|4211081215] "count" Vector__XXX
 SG_ Atttt1SSstTtNOSstCItRqsts : 64|32@1+ (1,0) [0|4211081215] "count" Vector__XXX
 SG_ Atttt1SSstTtNOSstCMRqsts : 96|32@1+ (1,0) [0|4211081215] "count" Vector__XXX
 SG_ Atttt1SSstAvTBtwSstCEvts : 128|32@1+ (1,0) [0|4211081215] "s" Vector__XXX
 SG_ Atttt1SSstAvDstBtwSstCEvts : 160|32@1+ (0.125,0) [0|526385151.875] "km" Vector__XXX

BO_ 2566671102 SCRSC: 8 Vector__XXX
 SG_ ScrSystemCleaningForcedStatus : 53|3@1+ (1,0) [0|7] "" Vector__XXX
 SG_ ScrSystemCleaningLampCommand : 0|3@1+ (1,0) [0|7] "" Vector__XXX
 SG_ ScrSystemCleaningStatus : 10|2@1+ (1,0) [0|3] "" Vector__XXX
 SG_ SrSstmClnngInhtdStts : 16|2@1+ (1,0) [0|3] "" Vector__XXX
 SG_ SrSstmClnngInhtdDTInhtSwth : 18|2@1+ (1,0) [0|3] "" Vector__XXX
 SG_ SrSstmClnngInhtdDTClthDsnggd : 20|2@1+ (1,0) [0|3] "" Vector__XXX
 SG_ SrSstmClnngInhtdDTSrvBrkAtv : 22|2@1+ (1,0) [0|3] "" Vector__XXX
 SG_ SrSstmClnngInhtdDTPtAtv : 24|2@1+ (1,0) [0|3] "" Vector__XXX
 SG_ SSstCItdDTAtPdOId : 26|2@1+ (1,0) [0|3] "" Vector__XXX
 SG_ SrSstmClnngInhtdDTOtOfNtrl : 28|2@1+ (1,0) [0|3] "" Vector__XXX
 SG_ SSstCItdDTVSpdAvAwdSpd : 30|2@1+ (1,0) [0|3] "" Vector__XXX
 SG_ SrSstmClnngInhtdDTPrkngBrkNtSt : 32|2@1+ (1,0) [0|3] "" Vector__XXX
 SG_ SrSstmClnngInhtdDTLwExhstTmprtr : 34|2@1+ (1,0) [0|3] "" Vector__XXX
 SG_ SrSstmClnngInhtdDTSstmFltAtv : 36|2@1+ (1,0) [0|3] "" Vector__XXX
 SG_ SrSstmClnngInhtdDTSstmTmt : 38|2@1+ (1,0) [0|3] "" Vector__XXX
 SG_ SrSstmClnngInhtdDTTmprrSstmLkt : 40|2@1+ (1,0) [0|3] "" Vector__XXX
 SG_ SrSstmClnngInhtdDTPrmnntSstmLkt : 42|2@1+ (1,0) [0|3] "" Vector__XXX
 SG_ SrSstmClnngInhtdDTEngnNtWrmdUp : 44|2@1+ (1,0) [0|3] "" Vector__XXX
 SG_ SSstCItdDTVSpdBwAwdSpd : 46|2@1+ (1,0) [0|3] "" Vector__XXX
 SG_ SrSstmClnngAtmtInttnCnfgrtn : 48|2@1+ (1,0) [0|3] "" Vector__XXX
 SG_ Atttt1SSstCdtsNtMtFAtvC : 60|2@1+ (1,0) [0|3] "" Vector__XXX

BO_ 2566671358 EEC17: 8 Vector__XXX
 SG_ CylinderFuelRate : 48|16@1+ (0.03125,0) [0|2007.96875] "mg/stroke" Vector__XXX
 SG_ EngineExhaustFlowRate : 32|16@1+ (0.2,0) [0|12851] "kg/h" Vector__XXX
 SG_ PemsEngineFuelMassFlowRate : 0|16@1+ (0.02,0) [0|1285.1] "g/s" Vector__XXX
 SG_ VehicleFuelRate : 16|16@1+ (0.02,0) [0|1285.1] "g/s" Vector__XXX

BO_ 2566671614 SCROII3: 8 Vector__XXX
 SG_ SrOprtrIndmntOvrrdEnl : 0|2@1+ (1,0) [0|3] "" Vector__XXX
 SG_ SrOprtrIndmntOvrrdTmRmnng : 8|16@1+ (1,0) [0|64255] "s" Vector__XXX
 SG_ NOSOptIdtOvdEvtsR : 24|8@1+ (1,0) [0|250] "count" Vector__XXX
 SG_ TtlNmrOfSrOprtrIndmntOvrrdEvnts : 32|16@1+ (1,0) [0|64255] "count" Vector__XXX

BO_ 2566671870 A2SCRDSI3: 8 Vector__XXX
 SG_ Aftrtrtmnt2DslExhstFldDsr2Prssr : 24|8@1+ (4,0) [0|1000] "kPa" Vector__XXX
 SG_ Atttt2DsExstFdDs2AstPss : 8|8@1+ (8,0) [0|2000] "kPa" Vector__XXX
 SG_ Atttt2DsExstFdDs2Tpt : 16|8@1+ (1,-40) [-40|210] "degC" Vector__XXX
 SG_ Aftrtrtmnt2DslExhstFldDsr1Prssr : 0|8@1+ (4,0) [0|1000] "kPa" Vector__XXX
 SG_ Atttt2DsExstFdDs1PssExtddR : 32|16@1+ (0.1,-100) [-100|6325.5] "kPa" Vector__XXX

BO_ 2566672126 A1SCRDSI3: 8 Vector__XXX
 SG_ Aftrtrtmnt1DslExhstFldDsr2Prssr : 24|8@1+ (4,0) [0|1000] "kPa" Vector__XXX
 SG_ Atttt1DsExstFdDs2AstPss : 8|8@1+ (8,0) [0|2000] "kPa" Vector__XXX
 SG_ Atttt1DsExstFdDs2Tpt : 16|8@1+ (1,-40) [-40|210] "degC" Vector__XXX
 SG_ Aftrtrtmnt1DslExhstFldDsr1Prssr : 0|8@1+ (4,0) [0|1000] "kPa" Vector__XXX
 SG_ Atttt1DsExstFdDs1PssExtddR : 32|16@1+ (0.1,-100) [-100|6325.5] "kPa" Vector__XXX

BO_ 2566672382 PWSI: 8 Vector__XXX
 SG_ PayloadWeightSensor1Status : 0|2@1+ (1,0) [0|3] "" Vector__XXX
 SG_ PayloadWeightSensor2Status : 2|2@1+ (1,0) [0|3] "" Vector__XXX
 SG_ PayloadWeightSensor3Status : 4|2@1+ (1,0) [0|3] "" Vector__XXX
 SG_ PayloadWeightSensor4Status : 6|2@1+ (1,0) [0|3] "" Vector__XXX
 SG_ PayloadWeightSensor5Status : 8|2@1+ (1,0) [0|3] "" Vector__XXX
 SG_ PayloadWeightSensor6Status : 10|2@1+ (1,0) [0|3] "" Vector__XXX
 SG_ PayloadWeightSensor7Status : 12|2@1+ (1,0) [0|3] "" Vector__XXX
 SG_ PayloadWeightSensor8Status : 14|2@1+ (1,0) [0|3] "" Vector__XXX

BO_ 2566672638 PLSS: 8 Vector__XXX
 SG_ DeliveredPayloadConfidence : 48|8@1+ (0.5,0) [0|100] "%" Vector__XXX
 SG_ DeliveredPayloadWeight : 24|24@1+ (2,0) [0|32899070] "kg" Vector__XXX
 SG_ HaulCycleCount : 0|16@1+ (1,0) [0|64255] "count" Vector__XXX
 SG_ HaulModeStatus : 16|4@1+ (1,0) [0|15] "" Vector__XXX
 SG_ PldDlvrTrnstnStts : 20|4@1+ (1,0) [0|15] "" Vector__XXX

BO_ 2566673406 EGLI: 8 Vector__XXX
 SG_ GasLeakageDetection1Pressure : 24|8@1+ (4,0) [0|100] "kPa" Vector__XXX
 SG_ GasLeakageDetection2Pressure : 32|8@1+ (4,0) [0|100] "kPa" Vector__XXX
 SG_ GasLeakageDetection3Pressure : 40|8@1+ (4,0) [0|100] "kPa" Vector__XXX
 SG_ GssFlLkg1Cnntrtn : 0|8@1+ (0.5,0) [0|100] "%" Vector__XXX
 SG_ GssFlLkg2Cnntrtn : 8|8@1+ (0.5,0) [0|100] "%" Vector__XXX
 SG_ GssFlLkg3Cnntrtn : 16|8@1+ (0.5,0) [0|100] "%" Vector__XXX

BO_ 2566674174 SCROII2: 8 Vector__XXX
 SG_ ScrOperatorInducementTotalTime : 32|32@1+ (1,0) [0|4211081215] "s" Vector__XXX
 SG_ AftrtrtmntSrMlfntnTm : 0|32@1+ (1,0) [0|4211081215] "s" Vector__XXX

BO_ 2566674430 SCROII1: 8 Vector__XXX
 SG_ DslExhstFldQltMlfntnTm : 32|32@1+ (1,0) [0|4211081215] "s" Vector__XXX
 SG_ DslExhstFldTnk1EmptTm : 0|32@1+ (1,0) [0|4211081215] "s" Vector__XXX

BO_ 2566674686 TCI7: 8 Vector__XXX
 SG_ EngnTrhrgr2LOlPrssr : 0|8@1+ (4,0) [0|1000] "kPa" Vector__XXX
 SG_ EngnTrhrgr2OlTmprtr : 24|16@1+ (0.03125,-273) [-273|1734.96875] "degC" Vector__XXX
 SG_ EngnTrhrgr3LOlPrssr : 8|8@1+ (4,0) [0|1000] "kPa" Vector__XXX
 SG_ EngnTrhrgr4LOlPrssr : 16|8@1+ (4,0) [0|1000] "kPa" Vector__XXX
 SG_ EngnTrhrgr1TrnIntk2Tmprtr : 40|16@1+ (0.03125,-273) [-273|1734.96875] "degC" Vector__XXX

BO_ 2566675966 HVESSCFG: 20 Vector__XXX
 SG_ HvessNominalVoltage : 0|16@1+ (0.05,0) [0|3212.75] "V" Vector__XXX
 SG_ HvessCellMaximumVoltageLimit : 112|8@1+ (0.02044,0) [0|5.11] "V" Vector__XXX
 SG_ HvessCellMinimumVoltageLimit : 120|8@1+ (0.02044,0) [0|5.11] "V" Vector__XXX
 SG_ HvessNumberOfHvespsConfigured : 128|8@1+ (1,0) [0|250] "count" Vector__XXX
 SG_ HvssRmmnddMnmmOprtngVltg : 16|16@1+ (0.05,0) [0|3212.75] "V" Vector__XXX
 SG_ HvssRmmnddMxmmOprtngVltg : 32|16@1+ (0.05,0) [0|3212.75] "V" Vector__XXX
 SG_ HvssRmmnddMnmmSttOfChrg : 48|16@1+ (0.0015625,0) [0|100.3984375] "%" Vector__XXX
 SG_ HvssRmmnddMxmmSttOfChrg : 64|16@1+ (0.0015625,0) [0|100.3984375] "%" Vector__XXX
 SG_ HvssRmmnddMxmmOprtngTmprtr : 80|16@1+ (0.03125,-273) [-273|1734.96875] "degC" Vector__XXX
 SG_ HvssRmmnddMnmmOprtngTmprtr : 96|16@1+ (0.03125,-273) [-273|1734.96875] "degC" Vector__XXX
 SG_ HvessNominalRatedCapacity : 136|24@1+ (0.001,0) [0|16449.535] "kWh" Vector__XXX

BO_ 2566687742 AFT1PSI2: 8 Vector__XXX
 SG_ Aftrtrtmnt1PrtltSnsrDttnStts : 0|4@1+ (1,0) [0|15] "" Vector__XXX
 SG_ Aftrtrtmnt1PrtltSnsrHtrRsstn : 40|16@1+ (0.1,0) [0|6425.5] "ohm" Vector__XXX
 SG_ Aftrtrtmnt1PrtltSnsrMxmmRsstn : 32|8@1+ (250,0) [0|62500] "kohm" Vector__XXX
 SG_ Aftrtrtmnt1PrtltSnsrPwrSppl : 4|2@1+ (1,0) [0|3] "" Vector__XXX
 SG_ Aftrtrtmnt1PrtltSnsrTmprtr : 16|16@1+ (0.03125,-273) [-273|1734.96875] "degC" Vector__XXX
 SG_ Atttt1PttSsRtFdCt : 8|8@1+ (1,0) [0|250] "count" Vector__XXX

BO_ 2566687998 AFT1PSI1: 8 Vector__XXX
 SG_ Aftrtrtmnt1PrtltSnsrAtvAmltnTm : 24|16@1+ (6,0) [0|385530] "s" Vector__XXX
 SG_ Aftrtrtmnt1PrtltSnsrHtrStt : 16|2@1+ (1,0) [0|3] "" Vector__XXX
 SG_ Aftrtrtmnt1PrtltSnsrRgnrtnStt : 20|4@1+ (1,0) [0|15] "" Vector__XXX
 SG_ Aftrtrtmnt1PrtltSnsrRgnrtnStts : 18|2@1+ (1,0) [0|3] "" Vector__XXX
 SG_ Aftrtrtmnt1PrtltSnsrRsstn : 0|16@1+ (1,0) [0|62500] "kohm" Vector__XXX
 SG_ Atttt1PttSsTBtwRts : 40|16@1+ (6,0) [0|385530] "s" Vector__XXX

BO_ 2566689278 EEN: 8 Vector__XXX
 SG_ EngineExhaustDesiredNox : 16|16@1+ (0.05,-200) [-200|3012.75] "ppm" Vector__XXX
 SG_ EngineExhaustNox : 0|16@1+ (0.05,-200) [-200|3012.75] "ppm" Vector__XXX
 SG_ EngnExhstNxSnsrPwrSppl : 32|2@1+ (1,0) [0|3] "" Vector__XXX

BO_ 2566689534 AFR: 8 Vector__XXX
 SG_ EngineMainChamberAirFuelRatio : 0|16@1+ (0.001,0) [0|64.255] "" Vector__XXX
 SG_ EnginePrechamberAirFuelRatio : 32|16@1+ (0.001,0) [0|64.255] "" Vector__XXX
 SG_ EngnMnChmrDsrdArFlRt : 16|16@1+ (0.001,0) [0|64.255] "" Vector__XXX
 SG_ EngnPrhmrDsrdArFlRt : 48|16@1+ (0.001,0) [0|64.255] "" Vector__XXX

BO_ 2566689790 GFP2: 8 Vector__XXX
 SG_ EngnMnChmrFlAsltPrssr : 0|16@1+ (0.1,0) [0|6425.5] "kPa" Vector__XXX
 SG_ EngnMnChmrFlDsrdAsltPrssr : 16|16@1+ (0.1,0) [0|6425.5] "kPa" Vector__XXX
 SG_ EngnPrhmrFlAsltPrssr : 32|16@1+ (0.1,0) [0|6425.5] "kPa" Vector__XXX
 SG_ EngnPrhmrFlDsrdAsltPrssr : 48|16@1+ (0.1,0) [0|6425.5] "kPa" Vector__XXX

BO_ 2566690046 ASAI: 8 Vector__XXX
 SG_ AfterRunCompleteThisCycle : 48|2@1+ (1,0) [0|3] "" Vector__XXX
 SG_ AttttDsExstFdDsCdwCptLstC : 34|2@1+ (1,0) [0|3] "" Vector__XXX
 SG_ AttttDsExstFdDsCdwCptTsC : 32|2@1+ (1,0) [0|3] "" Vector__XXX
 SG_ AttttDsExstFdDsCdwItptCt : 0|16@1+ (1,0) [0|64255] "count" Vector__XXX
 SG_ AttttDsExstFdDsPCptLstC : 42|2@1+ (1,0) [0|3] "" Vector__XXX
 SG_ AttttDsExstFdDsPCptTsC : 40|2@1+ (1,0) [0|3] "" Vector__XXX
 SG_ AttttDsExstFdDsPItptCt : 16|16@1+ (1,0) [0|64255] "count" Vector__XXX

BO_ 2566690558 EI2: 8 Vector__XXX
 SG_ EngineCommonRailOilPressure : 32|8@1+ (4,0) [0|1000] "kPa" Vector__XXX
 SG_ EngnCmmnRlOlAsltPrssr : 40|8@1+ (4,0) [0|1000] "kPa" Vector__XXX
 SG_ EOFtItPssHRstExtddR : 16|16@1+ (0.1,0) [0|6425.5] "kPa" Vector__XXX
 SG_ EngnExhstBnk1Prssr1ExtnddRng : 0|16@1+ (0.125,0) [0|8031.875] "kPa" Vector__XXX
 SG_ EngineExhaustBank2Pressure1 : 48|16@1+ (0.0078125,-250) [-250|251.9921875] "kPa" Vector__XXX

BO_ 2566690814 ESC2: 8 Vector__XXX
 SG_ CircleSteerModeActuatorState : 12|2@1+ (1,0) [0|3] "" Vector__XXX
 SG_ CrabSteerModeActuatorState : 14|2@1+ (1,0) [0|3] "" Vector__XXX
 SG_ FrontSteeringAxleCenteredStatus : 4|2@1+ (1,0) [0|3] "" Vector__XXX
 SG_ RearSteeringAxleCenteredStatus : 6|2@1+ (1,0) [0|3] "" Vector__XXX
 SG_ Wheel2SteerActuatorState : 8|2@1+ (1,0) [0|3] "" Vector__XXX
 SG_ Wheel4SteerActuatorState : 10|2@1+ (1,0) [0|3] "" Vector__XXX
 SG_ RequestedSteeringMode : 0|3@1+ (1,0) [0|7] "" Vector__XXX
 SG_ SteeringModeTwoWheelSwitchInput : 32|2@1+ (1,0) [0|3] "" Vector__XXX
 SG_ SteeringModeCrabSwitchInput : 34|2@1+ (1,0) [0|3] "" Vector__XXX
 SG_ SteeringModeCircleSwitchInput : 36|2@1+ (1,0) [0|3] "" Vector__XXX
 SG_ SteeringModeStatus : 40|3@1+ (1,0) [0|7] "" Vector__XXX
 SG_ StrngCntrllrETmprtr : 16|16@1+ (0.03125,-273) [-273|1734.96875] "degC" Vector__XXX

BO_ 2566691326 AUI: 8 Vector__XXX
 SG_ NmrOfAssmlUntIdntftnFlds : 0|8@1+ (1,0) [0|250] "count" Vector__XXX

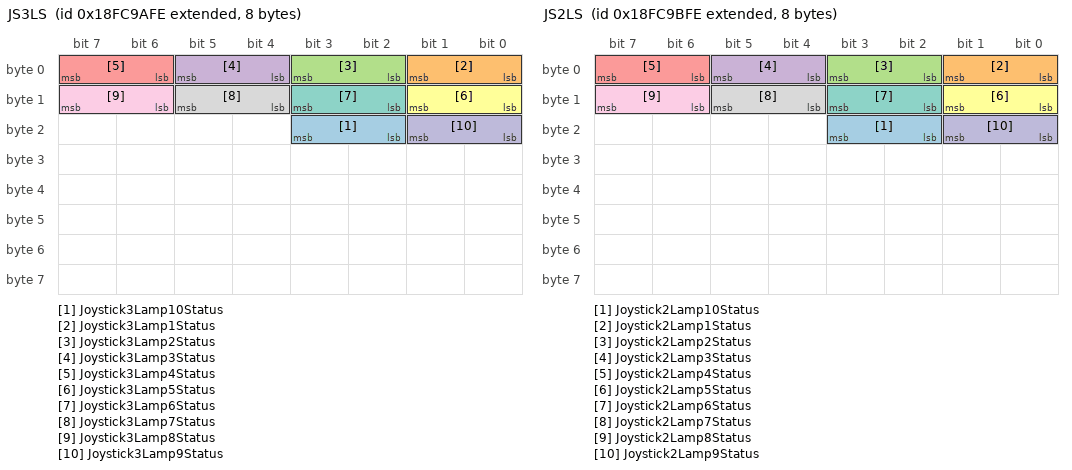
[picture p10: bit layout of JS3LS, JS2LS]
BO_ 2566691582 JS3LS: 8 Vector__XXX
 SG_ Joystick3Lamp10Status : 18|2@1+ (1,0) [0|3] "" Vector__XXX
 SG_ Joystick3Lamp1Status : 0|2@1+ (1,0) [0|3] "" Vector__XXX
 SG_ Joystick3Lamp2Status : 2|2@1+ (1,0) [0|3] "" Vector__XXX
 SG_ Joystick3Lamp3Status : 4|2@1+ (1,0) [0|3] "" Vector__XXX
 SG_ Joystick3Lamp4Status : 6|2@1+ (1,0) [0|3] "" Vector__XXX
 SG_ Joystick3Lamp5Status : 8|2@1+ (1,0) [0|3] "" Vector__XXX
 SG_ Joystick3Lamp6Status : 10|2@1+ (1,0) [0|3] "" Vector__XXX
 SG_ Joystick3Lamp7Status : 12|2@1+ (1,0) [0|3] "" Vector__XXX
 SG_ Joystick3Lamp8Status : 14|2@1+ (1,0) [0|3] "" Vector__XXX
 SG_ Joystick3Lamp9Status : 16|2@1+ (1,0) [0|3] "" Vector__XXX

BO_ 2566691838 JS2LS: 8 Vector__XXX
 SG_ Joystick2Lamp10Status : 18|2@1+ (1,0) [0|3] "" Vector__XXX
 SG_ Joystick2Lamp1Status : 0|2@1+ (1,0) [0|3] "" Vector__XXX
 SG_ Joystick2Lamp2Status : 2|2@1+ (1,0) [0|3] "" Vector__XXX
 SG_ Joystick2Lamp3Status : 4|2@1+ (1,0) [0|3] "" Vector__XXX
 SG_ Joystick2Lamp4Status : 6|2@1+ (1,0) [0|3] "" Vector__XXX
 SG_ Joystick2Lamp5Status : 8|2@1+ (1,0) [0|3] "" Vector__XXX
 SG_ Joystick2Lamp6Status : 10|2@1+ (1,0) [0|3] "" Vector__XXX
 SG_ Joystick2Lamp7Status : 12|2@1+ (1,0) [0|3] "" Vector__XXX
 SG_ Joystick2Lamp8Status : 14|2@1+ (1,0) [0|3] "" Vector__XXX
 SG_ Joystick2Lamp9Status : 16|2@1+ (1,0) [0|3] "" Vector__XXX

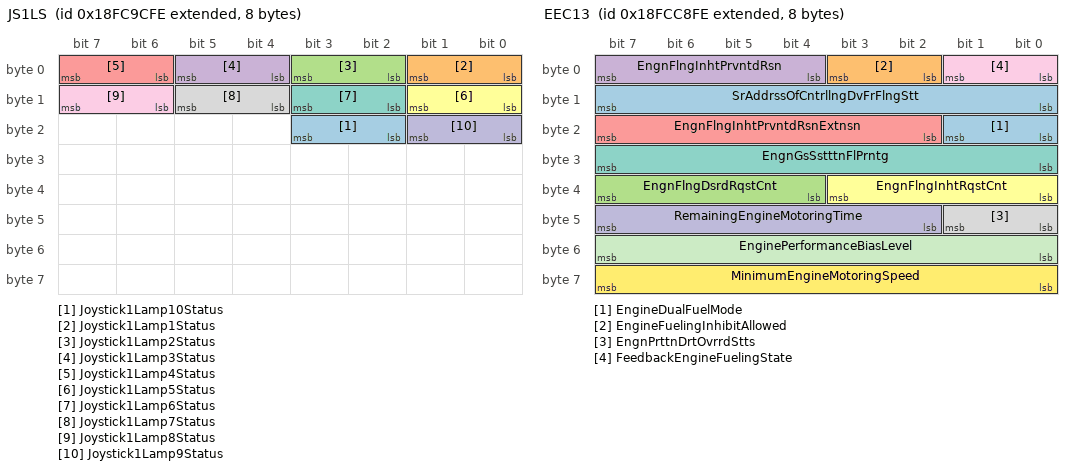
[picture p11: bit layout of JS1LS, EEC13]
BO_ 2566692094 JS1LS: 8 Vector__XXX
 SG_ Joystick1Lamp10Status : 18|2@1+ (1,0) [0|3] "" Vector__XXX
 SG_ Joystick1Lamp1Status : 0|2@1+ (1,0) [0|3] "" Vector__XXX
 SG_ Joystick1Lamp2Status : 2|2@1+ (1,0) [0|3] "" Vector__XXX
 SG_ Joystick1Lamp3Status : 4|2@1+ (1,0) [0|3] "" Vector__XXX
 SG_ Joystick1Lamp4Status : 6|2@1+ (1,0) [0|3] "" Vector__XXX
 SG_ Joystick1Lamp5Status : 8|2@1+ (1,0) [0|3] "" Vector__XXX
 SG_ Joystick1Lamp6Status : 10|2@1+ (1,0) [0|3] "" Vector__XXX
 SG_ Joystick1Lamp7Status : 12|2@1+ (1,0) [0|3] "" Vector__XXX
 SG_ Joystick1Lamp8Status : 14|2@1+ (1,0) [0|3] "" Vector__XXX
 SG_ Joystick1Lamp9Status : 16|2@1+ (1,0) [0|3] "" Vector__XXX

BO_ 2566692862 DD2: 8 Vector__XXX
 SG_ DisplayRemainPowered : 48|2@1+ (1,0) [0|3] "" Vector__XXX
 SG_ EngineFuel2Tank1Level : 16|8@1+ (0.4,0) [0|100] "%" Vector__XXX
 SG_ EngineFuel2Tank2Level : 24|8@1+ (0.4,0) [0|100] "%" Vector__XXX
 SG_ EngineFuel2Tank3Level : 32|8@1+ (0.4,0) [0|100] "%" Vector__XXX
 SG_ EngineFuel2Tank4Level : 40|8@1+ (0.4,0) [0|100] "%" Vector__XXX
 SG_ EngineOilLevelHighLow : 56|8@1+ (0.5,-62.5) [-62.5|62.5] "l" Vector__XXX
 SG_ EngnOlFltrDffrntlPrssrExtnddRng : 0|16@1+ (0.0078125,-250) [-250|251.9921875] "kPa" Vector__XXX

BO_ 2566697470 ICMSTS: 8 Vector__XXX
 SG_ EngnIgntnCntrlMdl1Stt : 16|3@1+ (1,0) [0|7] "" Vector__XXX
 SG_ EngnIgntnCntrlMdl1Tmprtr : 0|8@1+ (1,-40) [-40|210] "degC" Vector__XXX
 SG_ EngnIgntnCntrlMdl2Stt : 19|3@1+ (1,0) [0|7] "" Vector__XXX
 SG_ EngnIgntnCntrlMdl2Tmprtr : 8|8@1+ (1,-40) [-40|210] "degC" Vector__XXX

BO_ 2566697726 SPOC1: 64 Vector__XXX
 SG_ SwitchedOutput10Current : 144|16@1+ (0.005,0) [0|321.275] "A" Vector__XXX
 SG_ SwitchedOutput11Current : 160|16@1+ (0.005,0) [0|321.275] "A" Vector__XXX
 SG_ SwitchedOutput12Current : 176|16@1+ (0.005,0) [0|321.275] "A" Vector__XXX
 SG_ SwitchedOutput13Current : 192|16@1+ (0.005,0) [0|321.275] "A" Vector__XXX
 SG_ SwitchedOutput14Current : 208|16@1+ (0.005,0) [0|321.275] "A" Vector__XXX
 SG_ SwitchedOutput15Current : 224|16@1+ (0.005,0) [0|321.275] "A" Vector__XXX
 SG_ SwitchedOutput16Current : 240|16@1+ (0.005,0) [0|321.275] "A" Vector__XXX
 SG_ SwitchedOutput17Current : 256|16@1+ (0.005,0) [0|321.275] "A" Vector__XXX
 SG_ SwitchedOutput18Current : 272|16@1+ (0.005,0) [0|321.275] "A" Vector__XXX
 SG_ SwitchedOutput19Current : 288|16@1+ (0.005,0) [0|321.275] "A" Vector__XXX
 SG_ SwitchedOutput1Current : 0|16@1+ (0.005,0) [0|321.275] "A" Vector__XXX
 SG_ SwitchedOutput20Current : 304|16@1+ (0.005,0) [0|321.275] "A" Vector__XXX
 SG_ SwitchedOutput21Current : 320|16@1+ (0.005,0) [0|321.275] "A" Vector__XXX
 SG_ SwitchedOutput22Current : 336|16@1+ (0.005,0) [0|321.275] "A" Vector__XXX
 SG_ SwitchedOutput23Current : 352|16@1+ (0.005,0) [0|321.275] "A" Vector__XXX
 SG_ SwitchedOutput24Current : 368|16@1+ (0.005,0) [0|321.275] "A" Vector__XXX
 SG_ SwitchedOutput25Current : 384|16@1+ (0.005,0) [0|321.275] "A" Vector__XXX
 SG_ SwitchedOutput26Current : 400|16@1+ (0.005,0) [0|321.275] "A" Vector__XXX
 SG_ SwitchedOutput27Current : 416|16@1+ (0.005,0) [0|321.275] "A" Vector__XXX
 SG_ SwitchedOutput28Current : 432|16@1+ (0.005,0) [0|321.275] "A" Vector__XXX
 SG_ SwitchedOutput29Current : 448|16@1+ (0.005,0) [0|321.275] "A" Vector__XXX
 SG_ SwitchedOutput2Current : 16|16@1+ (0.005,0) [0|321.275] "A" Vector__XXX
 SG_ SwitchedOutput30Current : 464|16@1+ (0.005,0) [0|321.275] "A" Vector__XXX
 SG_ SwitchedOutput31Current : 480|16@1+ (0.005,0) [0|321.275] "A" Vector__XXX
 SG_ SwitchedOutput32Current : 496|16@1+ (0.005,0) [0|321.275] "A" Vector__XXX
 SG_ SwitchedOutput3Current : 32|16@1+ (0.005,0) [0|321.275] "A" Vector__XXX
 SG_ SwitchedOutput4Current : 48|16@1+ (0.005,0) [0|321.275] "A" Vector__XXX
 SG_ SwitchedOutput5Current : 64|16@1+ (0.005,0) [0|321.275] "A" Vector__XXX
 SG_ SwitchedOutput6Current : 80|16@1+ (0.005,0) [0|321.275] "A" Vector__XXX
 SG_ SwitchedOutput7Current : 96|16@1+ (0.005,0) [0|321.275] "A" Vector__XXX
 SG_ SwitchedOutput8Current : 112|16@1+ (0.005,0) [0|321.275] "A" Vector__XXX
 SG_ SwitchedOutput9Current : 128|16@1+ (0.005,0) [0|321.275] "A" Vector__XXX

BO_ 2566697982 FPOC: 64 Vector__XXX
 SG_ FusedOutput10Current : 144|16@1+ (0.005,0) [0|321.275] "A" Vector__XXX
 SG_ FusedOutput11Current : 160|16@1+ (0.005,0) [0|321.275] "A" Vector__XXX
 SG_ FusedOutput12Current : 176|16@1+ (0.005,0) [0|321.275] "A" Vector__XXX
 SG_ FusedOutput13Current : 192|16@1+ (0.005,0) [0|321.275] "A" Vector__XXX
 SG_ FusedOutput14Current : 208|16@1+ (0.005,0) [0|321.275] "A" Vector__XXX
 SG_ FusedOutput15Current : 224|16@1+ (0.005,0) [0|321.275] "A" Vector__XXX
 SG_ FusedOutput16Current : 240|16@1+ (0.005,0) [0|321.275] "A" Vector__XXX
 SG_ FusedOutput17Current : 256|16@1+ (0.005,0) [0|321.275] "A" Vector__XXX
 SG_ FusedOutput18Current : 272|16@1+ (0.005,0) [0|321.275] "A" Vector__XXX
 SG_ FusedOutput19Current : 288|16@1+ (0.005,0) [0|321.275] "A" Vector__XXX
 SG_ FusedOutput1Current : 0|16@1+ (0.005,0) [0|321.275] "A" Vector__XXX
 SG_ FusedOutput20Current : 304|16@1+ (0.005,0) [0|321.275] "A" Vector__XXX
 SG_ FusedOutput21Current : 320|16@1+ (0.005,0) [0|321.275] "A" Vector__XXX
 SG_ FusedOutput22Current : 336|16@1+ (0.005,0) [0|321.275] "A" Vector__XXX
 SG_ FusedOutput23Current : 352|16@1+ (0.005,0) [0|321.275] "A" Vector__XXX
 SG_ FusedOutput24Current : 368|16@1+ (0.005,0) [0|321.275] "A" Vector__XXX
 SG_ FusedOutput25Current : 384|16@1+ (0.005,0) [0|321.275] "A" Vector__XXX
 SG_ FusedOutput26Current : 400|16@1+ (0.005,0) [0|321.275] "A" Vector__XXX
 SG_ FusedOutput27Current : 416|16@1+ (0.005,0) [0|321.275] "A" Vector__XXX
 SG_ FusedOutput28Current : 432|16@1+ (0.005,0) [0|321.275] "A" Vector__XXX
 SG_ FusedOutput29Current : 448|16@1+ (0.005,0) [0|321.275] "A" Vector__XXX
 SG_ FusedOutput2Current : 16|16@1+ (0.005,0) [0|321.275] "A" Vector__XXX
 SG_ FusedOutput30Current : 464|16@1+ (0.005,0) [0|321.275] "A" Vector__XXX
 SG_ FusedOutput31Current : 480|16@1+ (0.005,0) [0|321.275] "A" Vector__XXX
 SG_ FusedOutput32Current : 496|16@1+ (0.005,0) [0|321.275] "A" Vector__XXX
 SG_ FusedOutput3Current : 32|16@1+ (0.005,0) [0|321.275] "A" Vector__XXX
 SG_ FusedOutput4Current : 48|16@1+ (0.005,0) [0|321.275] "A" Vector__XXX
 SG_ FusedOutput5Current : 64|16@1+ (0.005,0) [0|321.275] "A" Vector__XXX
 SG_ FusedOutput6Current : 80|16@1+ (0.005,0) [0|321.275] "A" Vector__XXX
 SG_ FusedOutput7Current : 96|16@1+ (0.005,0) [0|321.275] "A" Vector__XXX
 SG_ FusedOutput8Current : 112|16@1+ (0.005,0) [0|321.275] "A" Vector__XXX
 SG_ FusedOutput9Current : 128|16@1+ (0.005,0) [0|321.275] "A" Vector__XXX

BO_ 2566698238 SPOS: 8 Vector__XXX
 SG_ SwitchedOutput1 : 6|2@1+ (1,0) [0|3] "" Vector__XXX
 SG_ SwitchedOutput10 : 20|2@1+ (1,0) [0|3] "" Vector__XXX
 SG_ SwitchedOutput11 : 18|2@1+ (1,0) [0|3] "" Vector__XXX
 SG_ SwitchedOutput12 : 16|2@1+ (1,0) [0|3] "" Vector__XXX
 SG_ SwitchedOutput13 : 30|2@1+ (1,0) [0|3] "" Vector__XXX
 SG_ SwitchedOutput14 : 28|2@1+ (1,0) [0|3] "" Vector__XXX
 SG_ SwitchedOutput15 : 26|2@1+ (1,0) [0|3] "" Vector__XXX
 SG_ SwitchedOutput16 : 24|2@1+ (1,0) [0|3] "" Vector__XXX
 SG_ SwitchedOutput17 : 38|2@1+ (1,0) [0|3] "" Vector__XXX
 SG_ SwitchedOutput18 : 36|2@1+ (1,0) [0|3] "" Vector__XXX
 SG_ SwitchedOutput19 : 34|2@1+ (1,0) [0|3] "" Vector__XXX
 SG_ SwitchedOutput2 : 4|2@1+ (1,0) [0|3] "" Vector__XXX
 SG_ SwitchedOutput20 : 32|2@1+ (1,0) [0|3] "" Vector__XXX
 SG_ SwitchedOutput21 : 46|2@1+ (1,0) [0|3] "" Vector__XXX
 SG_ SwitchedOutput22 : 44|2@1+ (1,0) [0|3] "" Vector__XXX
 SG_ SwitchedOutput23 : 42|2@1+ (1,0) [0|3] "" Vector__XXX
 SG_ SwitchedOutput24 : 40|2@1+ (1,0) [0|3] "" Vector__XXX
 SG_ SwitchedOutput25 : 54|2@1+ (1,0) [0|3] "" Vector__XXX
 SG_ SwitchedOutput26 : 52|2@1+ (1,0) [0|3] "" Vector__XXX
 SG_ SwitchedOutput27 : 50|2@1+ (1,0) [0|3] "" Vector__XXX
 SG_ SwitchedOutput28 : 48|2@1+ (1,0) [0|3] "" Vector__XXX
 SG_ SwitchedOutput29 : 62|2@1+ (1,0) [0|3] "" Vector__XXX
 SG_ SwitchedOutput3 : 2|2@1+ (1,0) [0|3] "" Vector__XXX
 SG_ SwitchedOutput30 : 60|2@1+ (1,0) [0|3] "" Vector__XXX
 SG_ SwitchedOutput31 : 58|2@1+ (1,0) [0|3] "" Vector__XXX
 SG_ SwitchedOutput32 : 56|2@1+ (1,0) [0|3] "" Vector__XXX
 SG_ SwitchedOutput4 : 0|2@1+ (1,0) [0|3] "" Vector__XXX
 SG_ SwitchedOutput5 : 14|2@1+ (1,0) [0|3] "" Vector__XXX
 SG_ SwitchedOutput6 : 12|2@1+ (1,0) [0|3] "" Vector__XXX
 SG_ SwitchedOutput7 : 10|2@1+ (1,0) [0|3] "" Vector__XXX
 SG_ SwitchedOutput8 : 8|2@1+ (1,0) [0|3] "" Vector__XXX
 SG_ SwitchedOutput9 : 22|2@1+ (1,0) [0|3] "" Vector__XXX

BO_ 2566698494 FPOS: 8 Vector__XXX
 SG_ FusedOutput1 : 6|2@1+ (1,0) [0|3] "" Vector__XXX
 SG_ FusedOutput10 : 20|2@1+ (1,0) [0|3] "" Vector__XXX
 SG_ FusedOutput11 : 18|2@1+ (1,0) [0|3] "" Vector__XXX
 SG_ FusedOutput12 : 16|2@1+ (1,0) [0|3] "" Vector__XXX
 SG_ FusedOutput13 : 30|2@1+ (1,0) [0|3] "" Vector__XXX
 SG_ FusedOutput14 : 28|2@1+ (1,0) [0|3] "" Vector__XXX
 SG_ FusedOutput15 : 26|2@1+ (1,0) [0|3] "" Vector__XXX
 SG_ FusedOutput16 : 24|2@1+ (1,0) [0|3] "" Vector__XXX
 SG_ FusedOutput17 : 38|2@1+ (1,0) [0|3] "" Vector__XXX
 SG_ FusedOutput18 : 36|2@1+ (1,0) [0|3] "" Vector__XXX
 SG_ FusedOutput19 : 34|2@1+ (1,0) [0|3] "" Vector__XXX
 SG_ FusedOutput2 : 4|2@1+ (1,0) [0|3] "" Vector__XXX
 SG_ FusedOutput20 : 32|2@1+ (1,0) [0|3] "" Vector__XXX
 SG_ FusedOutput21 : 46|2@1+ (1,0) [0|3] "" Vector__XXX
 SG_ FusedOutput22 : 44|2@1+ (1,0) [0|3] "" Vector__XXX
 SG_ FusedOutput23 : 42|2@1+ (1,0) [0|3] "" Vector__XXX
 SG_ FusedOutput24 : 40|2@1+ (1,0) [0|3] "" Vector__XXX
 SG_ FusedOutput25 : 54|2@1+ (1,0) [0|3] "" Vector__XXX
 SG_ FusedOutput26 : 52|2@1+ (1,0) [0|3] "" Vector__XXX
 SG_ FusedOutput27 : 50|2@1+ (1,0) [0|3] "" Vector__XXX
 SG_ FusedOutput28 : 48|2@1+ (1,0) [0|3] "" Vector__XXX
 SG_ FusedOutput29 : 62|2@1+ (1,0) [0|3] "" Vector__XXX
 SG_ FusedOutput3 : 2|2@1+ (1,0) [0|3] "" Vector__XXX
 SG_ FusedOutput30 : 60|2@1+ (1,0) [0|3] "" Vector__XXX
 SG_ FusedOutput31 : 58|2@1+ (1,0) [0|3] "" Vector__XXX
 SG_ FusedOutput32 : 56|2@1+ (1,0) [0|3] "" Vector__XXX
 SG_ FusedOutput4 : 0|2@1+ (1,0) [0|3] "" Vector__XXX
 SG_ FusedOutput5 : 14|2@1+ (1,0) [0|3] "" Vector__XXX
 SG_ FusedOutput6 : 12|2@1+ (1,0) [0|3] "" Vector__XXX
 SG_ FusedOutput7 : 10|2@1+ (1,0) [0|3] "" Vector__XXX
 SG_ FusedOutput8 : 8|2@1+ (1,0) [0|3] "" Vector__XXX
 SG_ FusedOutput9 : 22|2@1+ (1,0) [0|3] "" Vector__XXX

BO_ 2566698750 VEP5: 8 Vector__XXX
 SG_ SliBatteryPackCapacity : 16|16@1+ (1,0) [0|64255] "Ah" Vector__XXX
 SG_ SliBatteryPackHealth : 32|8@1+ (0.5,0) [0|100] "%" Vector__XXX
 SG_ SliBatteryPackStateOfCharge : 0|16@1+ (0.0025,0) [0|160.6375] "%" Vector__XXX
 SG_ SlCrnkngPrdtdMnmmBttrVltg : 40|8@1+ (0.2,0) [0|50] "V" Vector__XXX

BO_ 2566699006 HSS2: 8 Vector__XXX
 SG_ HrdBttrPkRmnngChrg : 0|16@1+ (0.0025,0) [0|160.6375] "%" Vector__XXX
 SG_ HrdSstmEngnStpStrtRmnngPrntg : 16|8@1+ (0.4,0) [0|100] "%" Vector__XXX
 SG_ HrdPrplsnMdMxmmSpdSttng : 24|8@1+ (1,0) [0|250] "km/h" Vector__XXX
 SG_ HrdPrplsnMdRmnngDstn : 32|16@1+ (0.03125,0) [0|2007.96875] "km" Vector__XXX
 SG_ HrdSstmEltrOprtnRmnngPrntg : 48|8@1+ (0.4,0) [0|100] "%" Vector__XXX
 SG_ HrdOrEvOprtrStppngMdCnfgrtn : 56|3@1+ (1,0) [0|7] "" Vector__XXX

BO_ 2566699262 AT2S2: 8 Vector__XXX
 SG_ Atttt2DsPttFtTTNxtAtvRt : 0|32@1+ (1,0) [0|4211081215] "s" Vector__XXX
 SG_ Atttt2SSstTSLstSstCEvt : 32|32@1+ (1,0) [0|4211081215] "s" Vector__XXX

BO_ 2566699518 AT1S2: 8 Vector__XXX
 SG_ Atttt1DsPttFtTTNxtAtvRt : 0|32@1+ (1,0) [0|4211081215] "s" Vector__XXX
 SG_ Atttt1SSstTSLstSstCEvt : 32|32@1+ (1,0) [0|4211081215] "s" Vector__XXX

BO_ 2566699774 A2ECMI: 8 Vector__XXX
 SG_ Atttt2DsExstFdCtMd1PwSpp1 : 2|2@1+ (1,0) [0|3] "" Vector__XXX
 SG_ Atttt2DsExstFdCtMd1PwSpp2 : 4|2@1+ (1,0) [0|3] "" Vector__XXX
 SG_ Atttt2DsExstFdCtMd1RCt : 0|2@1+ (1,0) [0|3] "" Vector__XXX
 SG_ Atttt2DsExstFdCtMd2PwSpp1 : 10|2@1+ (1,0) [0|3] "" Vector__XXX
 SG_ Atttt2DsExstFdCtMd2PwSpp2 : 12|2@1+ (1,0) [0|3] "" Vector__XXX
 SG_ Atttt2DsExstFdCtMd2RCt : 8|2@1+ (1,0) [0|3] "" Vector__XXX
 SG_ Atttt2DsExstFdCtMdCtB : 6|2@1+ (1,0) [0|3] "" Vector__XXX

BO_ 2566700030 A1ECMI: 8 Vector__XXX
 SG_ Atttt1DsExstFdCtMd1PwSpp1 : 2|2@1+ (1,0) [0|3] "" Vector__XXX
 SG_ Atttt1DsExstFdCtMd1PwSpp2 : 4|2@1+ (1,0) [0|3] "" Vector__XXX
 SG_ Atttt1DsExstFdCtMd1RCt : 0|2@1+ (1,0) [0|3] "" Vector__XXX
 SG_ Atttt1DsExstFdCtMd2PwSpp1 : 10|2@1+ (1,0) [0|3] "" Vector__XXX
 SG_ Atttt1DsExstFdCtMd2PwSpp2 : 12|2@1+ (1,0) [0|3] "" Vector__XXX
 SG_ Atttt1DsExstFdCtMd2RCt : 8|2@1+ (1,0) [0|3] "" Vector__XXX
 SG_ Atttt1DsExstFdCtMdCtB : 6|2@1+ (1,0) [0|3] "" Vector__XXX

BO_ 2566700286 A2SCRSI2: 8 Vector__XXX
 SG_ Aftrtrtmnt2TtlDslExhstFldUsd : 0|32@1+ (0.5,0) [0|2105540607.5] "l" Vector__XXX

BO_ 2566700542 A1SCRSI2: 8 Vector__XXX
 SG_ Aftrtrtmnt1TtlDslExhstFldUsd : 0|32@1+ (0.5,0) [0|2105540607.5] "l" Vector__XXX
 SG_ AftrtrtmntTrpDslExhstFld : 32|32@1+ (0.05,0) [0|210554060.75] "l" Vector__XXX

BO_ 2566701566 TRF3: 8 Vector__XXX
 SG_ TransmissionClutch2Pressure : 0|8@1+ (16,0) [0|4000] "kPa" Vector__XXX
 SG_ Trnsmssn1LrtnOlPrssrStts : 16|2@1+ (1,0) [0|3] "" Vector__XXX
 SG_ TrnsmssnOlClrOtltTmprtr : 8|8@1+ (1,-40) [-40|210] "degC" Vector__XXX
 SG_ TransmissionOilLevel2Switch : 18|2@1+ (1,0) [0|3] "" Vector__XXX

BO_ 2566701822 HSS1: 8 Vector__XXX
 SG_ ExtrnlEnrgSrCnntnStts : 48|4@1+ (1,0) [0|15] "" Vector__XXX
 SG_ HrdPrplsnMdTrnstnStts : 44|4@1+ (1,0) [0|15] "" Vector__XXX
 SG_ HybridPropulsionModeStatus : 40|4@1+ (1,0) [0|15] "" Vector__XXX
 SG_ HybridSystemEngineAssistStatus : 10|2@1+ (1,0) [0|3] "" Vector__XXX
 SG_ PropulsionSystemActive : 8|2@1+ (1,0) [0|3] "" Vector__XXX
 SG_ StoredEnergySourceLevel : 32|8@1+ (0.4,0) [0|100] "%" Vector__XXX
 SG_ StrdEnrgSrInrsngMdAllwd : 28|2@1+ (1,0) [0|3] "" Vector__XXX
 SG_ StrdEnrgSrOnlMdAllwd : 26|2@1+ (1,0) [0|3] "" Vector__XXX
 SG_ HrdOrEvSstmWrnngIndtr : 0|2@1+ (1,0) [0|3] "" Vector__XXX
 SG_ HrdOrEvSstmOvrhtIndtr : 2|2@1+ (1,0) [0|3] "" Vector__XXX
 SG_ HybridOrEvSystemStopIndicator : 4|2@1+ (1,0) [0|3] "" Vector__XXX
 SG_ HrdOrEvSstmOdRltdDtStts : 6|2@1+ (1,0) [0|3] "" Vector__XXX
 SG_ HrdOrEvSstmSrvIndtr : 12|2@1+ (1,0) [0|3] "" Vector__XXX
 SG_ HrdOrEvSstmMtrOvrspdIndtr : 14|2@1+ (1,0) [0|3] "" Vector__XXX
 SG_ HrdOrEvSstmMtrOvrspdAdlAlrm : 16|2@1+ (1,0) [0|3] "" Vector__XXX
 SG_ HrdOrEvSstmEltrAltrntrIndtr : 18|2@1+ (1,0) [0|3] "" Vector__XXX
 SG_ HrdOrEvSstmRgnrtvBrkngIndtr : 20|2@1+ (1,0) [0|3] "" Vector__XXX
 SG_ HrdOrEvSstmIntlztnIndtr : 22|2@1+ (1,0) [0|3] "" Vector__XXX
 SG_ HrdOrEvSstmHghVltgExpsrIndtr : 24|2@1+ (1,0) [0|3] "" Vector__XXX
 SG_ HrdOrEvSstmPrplsnDslStts : 52|2@1+ (1,0) [0|3] "" Vector__XXX
 SG_ HybridOrEvTowingAllowedStatus : 54|2@1+ (1,0) [0|3] "" Vector__XXX

BO_ 2566702078 GFI4: 8 Vector__XXX
 SG_ SupplyGasMethanePercentage : 0|16@1+ (0.0025,0) [0|160.6375] "%" Vector__XXX
 SG_ GaseousFuelMethaneNumber : 40|8@1+ (1,0) [0|125] "" Vector__XXX

BO_ 2566702334 A2SCREGT2: 8 Vector__XXX
 SG_ Aftrtrtmnt2SrIntrmdtTmprtr : 0|16@1+ (0.03125,-273) [-273|1734.96875] "degC" Vector__XXX
 SG_ Atttt2SItdtTptPF : 16|5@1+ (1,0) [0|31] "" Vector__XXX

BO_ 2566702590 A1SCREGT2: 8 Vector__XXX
 SG_ Aftrtrtmnt1SrIntrmdtTmprtr : 0|16@1+ (0.03125,-273) [-273|1734.96875] "degC" Vector__XXX
 SG_ Atttt1SItdtTptPF : 16|5@1+ (1,0) [0|31] "" Vector__XXX

BO_ 2566703358 EEC13: 8 Vector__XXX
 SG_ EngineDualFuelMode : 16|2@1+ (1,0) [0|3] "" Vector__XXX
 SG_ EngineFuelingInhibitAllowed : 2|2@1+ (1,0) [0|3] "" Vector__XXX
 SG_ EngnFlngDsrdRqstCnt : 36|4@1+ (1,0) [0|15] "" Vector__XXX
 SG_ EngnFlngInhtPrvntdRsn : 4|4@1+ (1,0) [0|15] "" Vector__XXX
 SG_ EngnFlngInhtPrvntdRsnExtnsn : 18|6@1+ (1,0) [0|63] "" Vector__XXX
 SG_ EngnFlngInhtRqstCnt : 32|4@1+ (1,0) [0|15] "" Vector__XXX
 SG_ EngnGsSstttnFlPrntg : 24|8@1+ (0.5,0) [0|125] "%" Vector__XXX
 SG_ EngnPrttnDrtOvrrdStts : 40|2@1+ (1,0) [0|3] "" Vector__XXX
 SG_ FeedbackEngineFuelingState : 0|2@1+ (1,0) [0|3] "" Vector__XXX
 SG_ RemainingEngineMotoringTime : 42|6@1+ (1,0) [0|61] "s" Vector__XXX
 SG_ EnginePerformanceBiasLevel : 48|8@1+ (0.4,0) [0|100] "%" Vector__XXX
 SG_ MinimumEngineMotoringSpeed : 56|8@1+ (10,0) [0|2500] "rpm" Vector__XXX
 SG_ SrAddrssOfCntrllngDvFrFlngStt : 8|8@1+ (1,0) [0|250] "sourceadr" Vector__XXX

BO_ 2566703614 EFTVI2: 8 Vector__XXX
 SG_ EngineFuelValve1Temperature : 16|8@1+ (1,-40) [-40|210] "degC" Vector__XXX
 SG_ EngineFuelValve2Temperature : 24|8@1+ (1,-40) [-40|210] "degC" Vector__XXX
 SG_ EngineThrottleValve1Position2 : 48|8@1+ (0.4,0) [0|100] "%" Vector__XXX
 SG_ EngineThrottleValve1Temperature : 0|8@1+ (1,-40) [-40|210] "degC" Vector__XXX
 SG_ EngineThrottleValve2Temperature : 8|8@1+ (1,-40) [-40|210] "degC" Vector__XXX
 SG_ EngnFlRkFlSpplTmprtr : 40|8@1+ (1,-40) [-40|210] "degC" Vector__XXX
 SG_ EngnTrhrgrWstgtAttr2Tmprtr : 32|8@1+ (1,-40) [-40|210] "degC" Vector__XXX

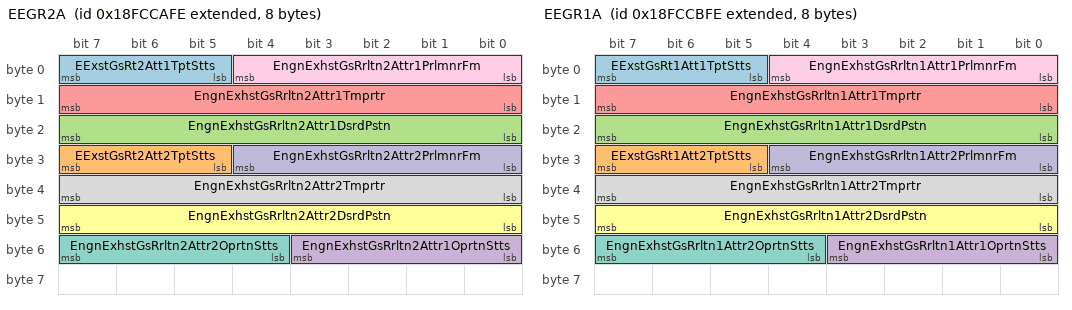
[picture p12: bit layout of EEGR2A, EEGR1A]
BO_ 2566703870 EEGR2A: 8 Vector__XXX
 SG_ EExstGsRt2Att1TptStts : 5|3@1+ (1,0) [0|7] "" Vector__XXX
 SG_ EExstGsRt2Att2TptStts : 29|3@1+ (1,0) [0|7] "" Vector__XXX
 SG_ EngnExhstGsRrltn2Attr1DsrdPstn : 16|8@1+ (0.4,0) [0|100] "%" Vector__XXX
 SG_ EngnExhstGsRrltn2Attr1OprtnStts : 48|4@1+ (1,0) [0|15] "" Vector__XXX
 SG_ EngnExhstGsRrltn2Attr1Tmprtr : 8|8@1+ (1,-40) [-40|210] "degC" Vector__XXX
 SG_ EngnExhstGsRrltn2Attr2DsrdPstn : 40|8@1+ (0.4,0) [0|100] "%" Vector__XXX
 SG_ EngnExhstGsRrltn2Attr2OprtnStts : 52|4@1+ (1,0) [0|15] "" Vector__XXX
 SG_ EngnExhstGsRrltn2Attr2Tmprtr : 32|8@1+ (1,-40) [-40|210] "degC" Vector__XXX
 SG_ EngnExhstGsRrltn2Attr1PrlmnrFm : 0|5@1+ (1,0) [0|31] "" Vector__XXX
 SG_ EngnExhstGsRrltn2Attr2PrlmnrFm : 24|5@1+ (1,0) [0|31] "" Vector__XXX

BO_ 2566704126 EEGR1A: 8 Vector__XXX
 SG_ EExstGsRt1Att1TptStts : 5|3@1+ (1,0) [0|7] "" Vector__XXX
 SG_ EExstGsRt1Att2TptStts : 29|3@1+ (1,0) [0|7] "" Vector__XXX
 SG_ EngnExhstGsRrltn1Attr1DsrdPstn : 16|8@1+ (0.4,0) [0|100] "%" Vector__XXX
 SG_ EngnExhstGsRrltn1Attr1OprtnStts : 48|4@1+ (1,0) [0|15] "" Vector__XXX
 SG_ EngnExhstGsRrltn1Attr1Tmprtr : 8|8@1+ (1,-40) [-40|210] "degC" Vector__XXX
 SG_ EngnExhstGsRrltn1Attr2DsrdPstn : 40|8@1+ (0.4,0) [0|100] "%" Vector__XXX
 SG_ EngnExhstGsRrltn1Attr2OprtnStts : 52|4@1+ (1,0) [0|15] "" Vector__XXX
 SG_ EngnExhstGsRrltn1Attr2Tmprtr : 32|8@1+ (1,-40) [-40|210] "degC" Vector__XXX
 SG_ EngnExhstGsRrltn1Attr1PrlmnrFm : 0|5@1+ (1,0) [0|31] "" Vector__XXX
 SG_ EngnExhstGsRrltn1Attr2PrlmnrFm : 24|5@1+ (1,0) [0|31] "" Vector__XXX

BO_ 2566704382 EEC12: 8 Vector__XXX
 SG_ Aftrtrtmnt1Otlt1GsSnsrPwrSppl : 2|2@1+ (1,0) [0|3] "" Vector__XXX
 SG_ Aftrtrtmnt1Otlt2GsSnsrPwrSppl : 10|2@1+ (1,0) [0|3] "" Vector__XXX
 SG_ Aftrtrtmnt2Otlt1GsSnsrPwrSppl : 6|2@1+ (1,0) [0|3] "" Vector__XXX
 SG_ EngnExhst1GsSnsr1PwrSppl : 0|2@1+ (1,0) [0|3] "" Vector__XXX
 SG_ EngnExhst2GsSnsr1PwrSppl : 4|2@1+ (1,0) [0|3] "" Vector__XXX
 SG_ EngnExhst1GsSnsr2PwrSppl : 8|2@1+ (1,0) [0|3] "" Vector__XXX

BO_ 2566705150 NSSR: 8 Vector__XXX
 SG_ Atttt1OttNxSsSDssT : 0|4@1+ (1,0) [0|15] "" Vector__XXX
 SG_ EngnExhst1NxSnsrSlfDgnssTrggr : 4|4@1+ (1,0) [0|15] "" Vector__XXX
 SG_ Atttt2OttNxSsSDssT : 8|4@1+ (1,0) [0|15] "" Vector__XXX
 SG_ EngnExhst2NxSnsrSlfDgnssTrggr : 12|4@1+ (1,0) [0|15] "" Vector__XXX

BO_ 2566705406 EPSI: 8 Vector__XXX
 SG_ Aftrtrtmnt1PrtltSnsr : 0|16@1+ (0.0125,0) [0|803.1875] "mg/(m*m*m)" Vector__XXX
 SG_ Aftrtrtmnt1PrtltSnsrCrrnt : 32|16@1+ (0.00390625,0) [0|127] "micro A" Vector__XXX
 SG_ Aftrtrtmnt2PrtltSnsr : 16|16@1+ (0.0125,0) [0|803.1875] "mg/(m*m*m)" Vector__XXX

BO_ 2566706686 AT1P1I: 8 Vector__XXX
 SG_ Aftrtrtmnt1DslExhstFldPmpHtr : 0|8@1+ (0.4,0) [0|100] "%" Vector__XXX
 SG_ Atttt1DsExstFdDsUt1HtR : 24|2@1+ (1,0) [0|3] "" Vector__XXX
 SG_ Atttt1DsExstFdPp2MtSpd : 8|16@1+ (0.5,0) [0|32127.5] "rpm" Vector__XXX
 SG_ Atttt1DsExstFdPpPwSpp : 26|2@1+ (1,0) [0|3] "" Vector__XXX
 SG_ AttttDsExstFdTsPpPR : 28|2@1+ (1,0) [0|3] "" Vector__XXX
 SG_ Atttt1DsExstFdPpFtLR : 32|8@1+ (0.4,0) [0|100] "%" Vector__XXX
 SG_ Atttt1DsExstFdPp2DvPt : 40|8@1+ (0.4,0) [0|100] "%" Vector__XXX

BO_ 2566706942 AT1DPF2S5: 8 Vector__XXX
 SG_ Atttt1DsPttFt2StSsAssFq3 : 0|16@1+ (0.1,0) [0|6425.5] "MHz" Vector__XXX
 SG_ Atttt1DsPttFt2StSsAssFq4 : 32|16@1+ (0.1,0) [0|6425.5] "MHz" Vector__XXX
 SG_ Atttt1DsPttFt2StSsFq3StS : 16|16@1+ (0.0025,0) [0|160.6375] "%" Vector__XXX
 SG_ Atttt1DsPttFt2StSsFq4StS : 48|16@1+ (0.0025,0) [0|160.6375] "%" Vector__XXX

BO_ 2566707198 AT1DPF2S4: 8 Vector__XXX
 SG_ Atttt1DsPttFt2StSsAssFq1 : 0|16@1+ (0.1,0) [0|6425.5] "MHz" Vector__XXX
 SG_ Atttt1DsPttFt2StSsAssFq2 : 32|16@1+ (0.1,0) [0|6425.5] "MHz" Vector__XXX
 SG_ Atttt1DsPttFt2StSsFq1StS : 16|16@1+ (0.0025,0) [0|160.6375] "%" Vector__XXX
 SG_ Atttt1DsPttFt2StSsFq2StS : 48|16@1+ (0.0025,0) [0|160.6375] "%" Vector__XXX

BO_ 2566707454 AT1DPF2S3: 8 Vector__XXX
 SG_ Atttt1DsPttFt2StSsAssRqstFq1 : 0|16@1+ (0.1,0) [0|6425.5] "MHz" Vector__XXX
 SG_ Atttt1DsPttFt2StSsAssRqstFq2 : 16|16@1+ (0.1,0) [0|6425.5] "MHz" Vector__XXX
 SG_ Atttt1DsPttFt2StSsAssRqstFq3 : 32|16@1+ (0.1,0) [0|6425.5] "MHz" Vector__XXX
 SG_ Atttt1DsPttFt2StSsAssRqstFq4 : 48|16@1+ (0.1,0) [0|6425.5] "MHz" Vector__XXX

BO_ 2566707710 AT1DPF1S5: 8 Vector__XXX
 SG_ Atttt1DsPttFt1StSsAssFq3 : 0|16@1+ (0.1,0) [0|6425.5] "MHz" Vector__XXX
 SG_ Atttt1DsPttFt1StSsAssFq4 : 32|16@1+ (0.1,0) [0|6425.5] "MHz" Vector__XXX
 SG_ Atttt1DsPttFt1StSsFq3StS : 16|16@1+ (0.0025,0) [0|160.6375] "%" Vector__XXX
 SG_ Atttt1DsPttFt1StSsFq4StS : 48|16@1+ (0.0025,0) [0|160.6375] "%" Vector__XXX

BO_ 2566707966 AT1DPF1S4: 8 Vector__XXX
 SG_ Atttt1DsPttFt1StSsAssFq1 : 0|16@1+ (0.1,0) [0|6425.5] "MHz" Vector__XXX
 SG_ Atttt1DsPttFt1StSsAssFq2 : 32|16@1+ (0.1,0) [0|6425.5] "MHz" Vector__XXX
 SG_ Atttt1DsPttFt1StSsFq1StS : 16|16@1+ (0.0025,0) [0|160.6375] "%" Vector__XXX
 SG_ Atttt1DsPttFt1StSsFq2StS : 48|16@1+ (0.0025,0) [0|160.6375] "%" Vector__XXX

BO_ 2566708222 AT1DPF1S3: 8 Vector__XXX
 SG_ Atttt1DsPttFt1StSsAssRqstFq1 : 0|16@1+ (0.1,0) [0|6425.5] "MHz" Vector__XXX
 SG_ Atttt1DsPttFt1StSsAssRqstFq2 : 16|16@1+ (0.1,0) [0|6425.5] "MHz" Vector__XXX
 SG_ Atttt1DsPttFt1StSsAssRqstFq3 : 32|16@1+ (0.1,0) [0|6425.5] "MHz" Vector__XXX
 SG_ Atttt1DsPttFt1StSsAssRqstFq4 : 48|16@1+ (0.1,0) [0|6425.5] "MHz" Vector__XXX

BO_ 2566708478 CCVS3: 8 Vector__XXX
 SG_ AdptvCrsCntrlRdnssStts : 0|2@1+ (1,0) [0|3] "" Vector__XXX
 SG_ AebsReadinessState : 24|2@1+ (1,0) [0|3] "" Vector__XXX
 SG_ CrsCntrlDrvrCnlltnStts : 26|2@1+ (1,0) [0|3] "" Vector__XXX
 SG_ CrsCntrlStSpdHghRsltn : 32|16@1+ (0.00390625,0) [0|250.99609375] "km/h" Vector__XXX
 SG_ CruiseControlSpeed : 48|16@1+ (0.00390625,0) [0|250.99609375] "km/h" Vector__XXX
 SG_ CruiseControlSystemCommandState : 2|3@1+ (1,0) [0|7] "" Vector__XXX
 SG_ PrdtvCrsCntrlStSpdOffstStts : 5|2@1+ (1,0) [0|3] "" Vector__XXX
 SG_ SAddssOCtDvFDsCsCt : 8|8@1+ (1,0) [0|250] "sourceadr" Vector__XXX
 SG_ SAddssOCtDvFPsCsCt : 16|8@1+ (1,0) [0|250] "sourceadr" Vector__XXX

BO_ 2566708734 AT2AC3: 8 Vector__XXX
 SG_ Aftrtrtmnt2SndrArAsltPrssr : 0|16@1+ (0.1,0) [0|6425.5] "kPa" Vector__XXX

BO_ 2566708990 AT1AC3: 8 Vector__XXX
 SG_ Aftrtrtmnt1SndrArAsltPrssr : 0|16@1+ (0.1,0) [0|6425.5] "kPa" Vector__XXX
 SG_ OprtrIndmntOvrrdRnwlRqrd : 16|2@1+ (1,0) [0|3] "" Vector__XXX

BO_ 2566709246 EFLP12: 8 Vector__XXX
 SG_ EFSppPpItAstPssExtddR : 56|8@1+ (5,0) [0|1250] "kPa" Vector__XXX
 SG_ EngineFuelFilterDegradation : 24|8@1+ (1,0) [0|250] "%" Vector__XXX
 SG_ EngineFuelReturnPressure : 32|8@1+ (1.64,-7) [-7|403] "kPa" Vector__XXX
 SG_ EngnFlDlvrAsltPrssr : 0|8@1+ (4,0) [0|1000] "kPa" Vector__XXX
 SG_ EngnFltrdFlDlvrAsltPrssr : 16|8@1+ (4,0) [0|1000] "kPa" Vector__XXX
 SG_ EngnFltrdFlDlvrPrssr : 8|8@1+ (4,0) [0|1000] "kPa" Vector__XXX
 SG_ EngnThrttlVlv2DffrntlPrssr : 40|16@1+ (0.1,0) [0|6425.5] "kPa" Vector__XXX

BO_ 2566709502 DPFC2: 8 Vector__XXX
 SG_ Aftertreatment1FuelMassRate : 32|16@1+ (0.05,0) [0|3212.75] "g/min" Vector__XXX
 SG_ Aftertreatment2FuelMassRate : 48|16@1+ (0.05,0) [0|3212.75] "g/min" Vector__XXX
 SG_ Atttt1DsPttFtItTptStPt : 0|16@1+ (0.03125,-273) [-273|1734.96875] "degC" Vector__XXX
 SG_ EngineUnburnedFuelPercentage : 16|16@1+ (0.0025,0) [0|160.6375] "%" Vector__XXX

BO_ 2566709758 LFE2: 8 Vector__XXX
 SG_ EngineDieselFuelDemandRate : 32|16@1+ (0.05,0) [0|3212.75] "l/h" Vector__XXX
 SG_ EngineFuelRateHighResolution : 0|32@1+ (0.001,0) [0|4211081.215] "l/h" Vector__XXX

BO_ 2566710014 SFS: 8 Vector__XXX
 SG_ SpplmntlFnCntrllrTmprtrStts : 8|3@1+ (1,0) [0|7] "" Vector__XXX
 SG_ SupplementalFanCurrent : 40|8@1+ (1,-125) [-125|125] "A" Vector__XXX
 SG_ SupplementalFanDirectionStatus : 2|2@1+ (1,0) [0|3] "" Vector__XXX
 SG_ SupplementalFanDriveStatus : 11|4@1+ (1,0) [0|15] "" Vector__XXX
 SG_ SupplementalFanEnableStatus : 0|2@1+ (1,0) [0|3] "" Vector__XXX
 SG_ SupplementalFanPower : 48|16@1+ (0.5,0) [0|32127.5] "W" Vector__XXX
 SG_ SupplementalFanSpeed : 24|16@1+ (0.5,0) [0|32127.5] "rpm" Vector__XXX
 SG_ SupplementalFanVelocityStatus : 4|4@1+ (1,0) [0|15] "" Vector__XXX
 SG_ SpplmntlFnCntrllrETmprtr : 16|8@1+ (1,-40) [-40|210] "degC" Vector__XXX

BO_ 2566710526 EFP: 8 Vector__XXX
 SG_ EngineFuelDensity : 16|16@1+ (0.00003052,0) [0|1.9610626] "g/cc" Vector__XXX
 SG_ EngineFuelDynamicViscosity : 0|16@1+ (0.015625,0) [0|1003.984375] "Cp" Vector__XXX
 SG_ EngnFl1Tmprtr1HghRsltn : 48|16@1+ (0.03125,-273) [-273|1734.96875] "degC" Vector__XXX
 SG_ EngnFlDltrtHghRsltn : 32|16@1+ (0.0001220703125,0) [0|7.8436279296875] "" Vector__XXX

BO_ 2566710782 HOP: 8 Vector__XXX
 SG_ HdrlOlRltvDltrtHghRsltn : 32|16@1+ (0.0001220703125,0) [0|7.8436279296875] "" Vector__XXX
 SG_ HdrlOlTmprtrHghRsltn : 48|16@1+ (0.03125,-273) [-273|1734.96875] "degC" Vector__XXX
 SG_ HydraulicOilDensity : 16|16@1+ (0.00003052,0) [0|1.9610626] "g/cc" Vector__XXX
 SG_ HydraulicOilDynamicViscosity : 0|16@1+ (0.015625,0) [0|1003.984375] "Cp" Vector__XXX

BO_ 2566711038 VLS2: 8 Vector__XXX
 SG_ LubricationCycleModeLockStatus : 0|2@1+ (1,0) [0|3] "" Vector__XXX
 SG_ LubricationCycleModeStatus : 2|3@1+ (1,0) [0|7] "" Vector__XXX
 SG_ LubricationOperationModeStatus : 5|3@1+ (1,0) [0|7] "" Vector__XXX
 SG_ LubricationPumpEnableStatus : 8|2@1+ (1,0) [0|3] "" Vector__XXX
 SG_ LubricationReservoirLevel : 10|2@1+ (1,0) [0|3] "" Vector__XXX
 SG_ LubricationTimingCycleStatus : 12|2@1+ (1,0) [0|3] "" Vector__XXX

BO_ 2566711294 EC3: 8 Vector__XXX
 SG_ EngnFrtnPrntTrqAtIdlPnt1 : 0|8@1+ (1,-125) [0|125] "%" Vector__XXX
 SG_ EngnFrtnPrntTrqPnt2 : 8|8@1+ (1,-125) [0|125] "%" Vector__XXX
 SG_ EngnFrtnPrntTrqPnt3 : 16|8@1+ (1,-125) [0|125] "%" Vector__XXX
 SG_ EngnFrtnPrntTrqPnt4 : 24|8@1+ (1,-125) [0|125] "%" Vector__XXX
 SG_ EngnFrtnPrntTrqPnt5 : 32|8@1+ (1,-125) [0|125] "%" Vector__XXX
 SG_ EngnFrtnPrntTrqPnt6 : 40|8@1+ (1,-125) [0|125] "%" Vector__XXX
 SG_ EngnFrtnPrntTrqPnt7 : 48|8@1+ (1,-125) [0|125] "%" Vector__XXX

BO_ 2566711550 IVAC: 8 Vector__XXX
 SG_ ItVvAttSstOPss1SdCt : 0|2@1+ (1,0) [0|3] "" Vector__XXX
 SG_ ItVvAttSstOPss2SdCt : 2|2@1+ (1,0) [0|3] "" Vector__XXX

BO_ 2566711806 ARMSWIMC: 8 Vector__XXX
 SG_ Armrest1Switch1 : 0|2@1+ (1,0) [0|3] "" Vector__XXX
 SG_ Armrest1Switch2 : 2|2@1+ (1,0) [0|3] "" Vector__XXX
 SG_ Armrest2Switch1 : 4|2@1+ (1,0) [0|3] "" Vector__XXX
 SG_ Armrest2Switch2 : 6|2@1+ (1,0) [0|3] "" Vector__XXX

BO_ 2566712318 AFT2NAI: 8 Vector__XXX
 SG_ Aftrtrtmnt2NxAdsrrRgnrtnStts : 0|2@1+ (1,0) [0|3] "" Vector__XXX
 SG_ Aftrtrtmnt2NxAdsrrDslftnStts : 2|2@1+ (1,0) [0|3] "" Vector__XXX

BO_ 2566712574 AFT1NAI: 8 Vector__XXX
 SG_ Aftrtrtmnt1NxAdsrrRgnrtnStts : 0|2@1+ (1,0) [0|3] "" Vector__XXX
 SG_ Aftrtrtmnt1NxAdsrrDslftnStts : 2|2@1+ (1,0) [0|3] "" Vector__XXX

BO_ 2566712830 AT2WUDOC: 8 Vector__XXX
 SG_ Atttt2WUpDsOxdtCtstItTpt : 0|16@1+ (0.03125,-273) [-273|1734.96875] "degC" Vector__XXX
 SG_ Atttt2WUpDsOxdtCtstOttTpt : 16|16@1+ (0.03125,-273) [-273|1734.96875] "degC" Vector__XXX

BO_ 2566713598 EFS2: 8 Vector__XXX
 SG_ EngnFlFltrStnSdDgrdtn : 8|8@1+ (1,0) [0|250] "%" Vector__XXX
 SG_ EngnFlFltrStnSdIntkAsltPrssr : 0|8@1+ (2,0) [0|500] "kPa" Vector__XXX
 SG_ FuelTankTransferPump : 16|2@1+ (1,0) [0|3] "" Vector__XXX
 SG_ FuelTankTransferPumpPressure : 24|16@1+ (0.1,0) [0|6425.5] "kPa" Vector__XXX
 SG_ EngineFuelPumpIntakeOilPressure : 40|8@1+ (4,0) [0|1000] "kPa" Vector__XXX

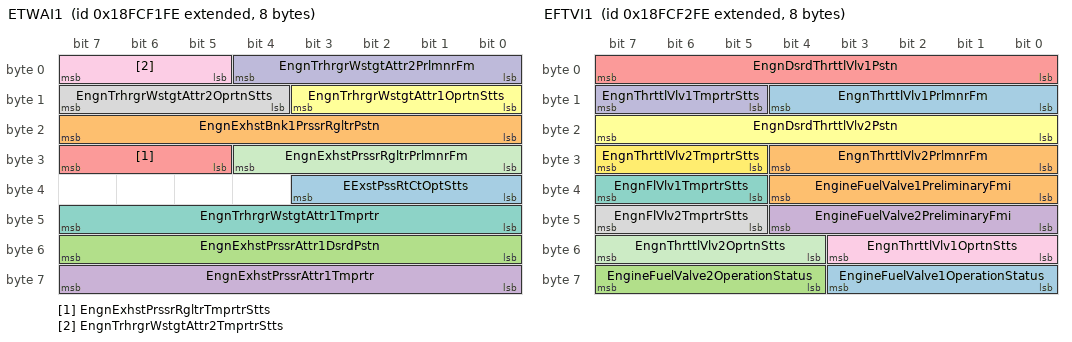
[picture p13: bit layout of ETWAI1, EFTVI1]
BO_ 2566713854 ETWAI1: 8 Vector__XXX
 SG_ EExstPssRtCtOptStts : 32|4@1+ (1,0) [0|15] "" Vector__XXX
 SG_ EngnExhstBnk1PrssrRgltrPstn : 16|8@1+ (0.4,0) [0|100] "%" Vector__XXX
 SG_ EngnExhstPrssrAttr1DsrdPstn : 48|8@1+ (0.4,0) [0|100] "%" Vector__XXX
 SG_ EngnExhstPrssrAttr1Tmprtr : 56|8@1+ (1,-40) [-40|210] "degC" Vector__XXX
 SG_ EngnExhstPrssrRgltrTmprtrStts : 29|3@1+ (1,0) [0|7] "" Vector__XXX
 SG_ EngnTrhrgrWstgtAttr1OprtnStts : 8|4@1+ (1,0) [0|15] "" Vector__XXX
 SG_ EngnTrhrgrWstgtAttr1Tmprtr : 40|8@1+ (1,-40) [-40|210] "degC" Vector__XXX
 SG_ EngnTrhrgrWstgtAttr2OprtnStts : 12|4@1+ (1,0) [0|15] "" Vector__XXX
 SG_ EngnTrhrgrWstgtAttr2TmprtrStts : 5|3@1+ (1,0) [0|7] "" Vector__XXX
 SG_ EngnTrhrgrWstgtAttr2PrlmnrFm : 0|5@1+ (1,0) [0|31] "" Vector__XXX
 SG_ EngnExhstPrssrRgltrPrlmnrFm : 24|5@1+ (1,0) [0|31] "" Vector__XXX

BO_ 2566714110 EFTVI1: 8 Vector__XXX
 SG_ EngineFuelValve1OperationStatus : 56|4@1+ (1,0) [0|15] "" Vector__XXX
 SG_ EngineFuelValve1PreliminaryFmi : 32|5@1+ (1,0) [0|31] "" Vector__XXX
 SG_ EngineFuelValve2OperationStatus : 60|4@1+ (1,0) [0|15] "" Vector__XXX
 SG_ EngineFuelValve2PreliminaryFmi : 40|5@1+ (1,0) [0|31] "" Vector__XXX
 SG_ EngnDsrdThrttlVlv1Pstn : 0|8@1+ (0.4,0) [0|100] "%" Vector__XXX
 SG_ EngnDsrdThrttlVlv2Pstn : 16|8@1+ (0.4,0) [0|100] "%" Vector__XXX
 SG_ EngnFlVlv1TmprtrStts : 37|3@1+ (1,0) [0|7] "" Vector__XXX
 SG_ EngnFlVlv2TmprtrStts : 45|3@1+ (1,0) [0|7] "" Vector__XXX
 SG_ EngnThrttlVlv1OprtnStts : 48|4@1+ (1,0) [0|15] "" Vector__XXX
 SG_ EngnThrttlVlv1TmprtrStts : 13|3@1+ (1,0) [0|7] "" Vector__XXX
 SG_ EngnThrttlVlv2OprtnStts : 52|4@1+ (1,0) [0|15] "" Vector__XXX
 SG_ EngnThrttlVlv2TmprtrStts : 29|3@1+ (1,0) [0|7] "" Vector__XXX
 SG_ EngnThrttlVlv1PrlmnrFm : 8|5@1+ (1,0) [0|31] "" Vector__XXX
 SG_ EngnThrttlVlv2PrlmnrFm : 24|5@1+ (1,0) [0|31] "" Vector__XXX

BO_ 2566714366 ETCBI: 8 Vector__XXX
 SG_ EngnTrhrgrCmprssrBpssAttr2Pstn : 0|8@1+ (0.4,0) [0|100] "%" Vector__XXX
 SG_ ETCpssBpssAtt1OptStts : 24|4@1+ (1,0) [0|15] "" Vector__XXX
 SG_ ETCpssBpssAtt1Tpt : 32|8@1+ (1,-40) [-40|210] "degC" Vector__XXX
 SG_ ETCpssBpssAtt2DsdPst : 8|8@1+ (0.4,0) [0|100] "%" Vector__XXX
 SG_ ETCpssBpssAtt2OptStts : 28|4@1+ (1,0) [0|15] "" Vector__XXX
 SG_ ETCpssBpssAtt2Tpt : 40|8@1+ (1,-40) [-40|210] "degC" Vector__XXX
 SG_ ETCpssBpssAtt2TptStts : 21|3@1+ (1,0) [0|7] "" Vector__XXX
 SG_ ETCpssBpssAtt2PF : 16|5@1+ (1,0) [0|31] "" Vector__XXX

BO_ 2566714622 CAC2: 8 Vector__XXX
 SG_ EngnChrgArClr2AmntArTmprtr : 32|16@1+ (0.03125,-273) [-273|1734.96875] "degC" Vector__XXX
 SG_ EngnChrgArClr2Effn : 48|8@1+ (0.4,0) [0|100] "%" Vector__XXX
 SG_ EngnChrgArClr2IntkTmprtr : 0|16@1+ (0.03125,-273) [-273|1734.96875] "degC" Vector__XXX
 SG_ EngnChrgArClr2OtltTmprtr : 16|16@1+ (0.03125,-273) [-273|1734.96875] "degC" Vector__XXX

BO_ 2566714878 CAC2P: 8 Vector__XXX
 SG_ EngnChrgArClr2PrlrEffn : 32|8@1+ (0.4,0) [0|100] "%" Vector__XXX
 SG_ EngnChrgArClr2PrlrIntkTmprtr : 0|16@1+ (0.03125,-273) [-273|1734.96875] "degC" Vector__XXX
 SG_ EngnChrgArClr2PrlrOtltTmprtr : 16|16@1+ (0.03125,-273) [-273|1734.96875] "degC" Vector__XXX

BO_ 2566715134 CAC1: 8 Vector__XXX
 SG_ EngnChrgArClr1AmntArTmprtr : 16|16@1+ (0.03125,-273) [-273|1734.96875] "degC" Vector__XXX
 SG_ EngnChrgArClr1Effn : 32|8@1+ (0.4,0) [0|100] "%" Vector__XXX
 SG_ EngnChrgArClr1IntkTmprtr : 0|16@1+ (0.03125,-273) [-273|1734.96875] "degC" Vector__XXX
 SG_ DsrdEngnChrgArClrOtltTmprtr : 40|16@1+ (0.03125,-273) [-273|1734.96875] "degC" Vector__XXX

BO_ 2566715390 CAC1P: 8 Vector__XXX
 SG_ EngnChrgArClr1PrlrEffn : 32|8@1+ (0.4,0) [0|100] "%" Vector__XXX
 SG_ EngnChrgArClr1PrlrIntkTmprtr : 0|16@1+ (0.03125,-273) [-273|1734.96875] "degC" Vector__XXX
 SG_ EngnChrgArClr1PrlrOtltTmprtr : 16|16@1+ (0.03125,-273) [-273|1734.96875] "degC" Vector__XXX

BO_ 2566715646 DPF2S2: 8 Vector__XXX
 SG_ Atttt2DsPttFtStSM : 32|16@1+ (0.0025,0) [0|160.6375] "%" Vector__XXX
 SG_ Atttt2DsPttFtStSMx : 16|16@1+ (0.0025,0) [0|160.6375] "%" Vector__XXX
 SG_ Atttt2DsPttFtStSStddDvt : 0|16@1+ (0.0025,0) [0|160.6375] "%" Vector__XXX

BO_ 2566715902 DPF1S2: 8 Vector__XXX
 SG_ Atttt1DsPttFtStSM : 32|16@1+ (0.0025,0) [0|160.6375] "%" Vector__XXX
 SG_ Atttt1DsPttFtStSMx : 16|16@1+ (0.0025,0) [0|160.6375] "%" Vector__XXX
 SG_ Atttt1DsPttFtStSStddDvt : 0|16@1+ (0.0025,0) [0|160.6375] "%" Vector__XXX

BO_ 2566717438 ET5: 8 Vector__XXX
 SG_ EngnExhstGsRrltn2MxrIntkTmprtr : 16|16@1+ (0.03125,-273) [-273|1734.96875] "degC" Vector__XXX
 SG_ EngnExhstGsRrltn2Tmprtr : 0|16@1+ (0.03125,-273) [-273|1734.96875] "degC" Vector__XXX
 SG_ ECtTpt2HRstExtddR : 32|16@1+ (0.03125,-273) [-273|1734.96875] "degC" Vector__XXX

BO_ 2566717950 LVDS: 8 Vector__XXX
 SG_ LowVoltageDisconnectTemperature : 24|8@1+ (1,-40) [-40|210] "degC" Vector__XXX
 SG_ LwVltgDsnntCrrntOprtngMd : 4|4@1+ (1,0) [0|15] "" Vector__XXX
 SG_ LwVltgDsnntMnlCnntStt : 2|2@1+ (1,0) [0|3] "" Vector__XXX
 SG_ LwVltgDsnntMnlDsnntStt : 0|2@1+ (1,0) [0|3] "" Vector__XXX
 SG_ LwVltgDsnntOtpt1Stt : 16|4@1+ (1,0) [0|15] "" Vector__XXX
 SG_ LwVltgDsnntOtpt2Stt : 12|4@1+ (1,0) [0|15] "" Vector__XXX
 SG_ LwVltgDsnntOtpt3Stt : 8|4@1+ (1,0) [0|15] "" Vector__XXX
 SG_ LwVltgDsnntVtOtptStt : 20|4@1+ (1,0) [0|15] "" Vector__XXX

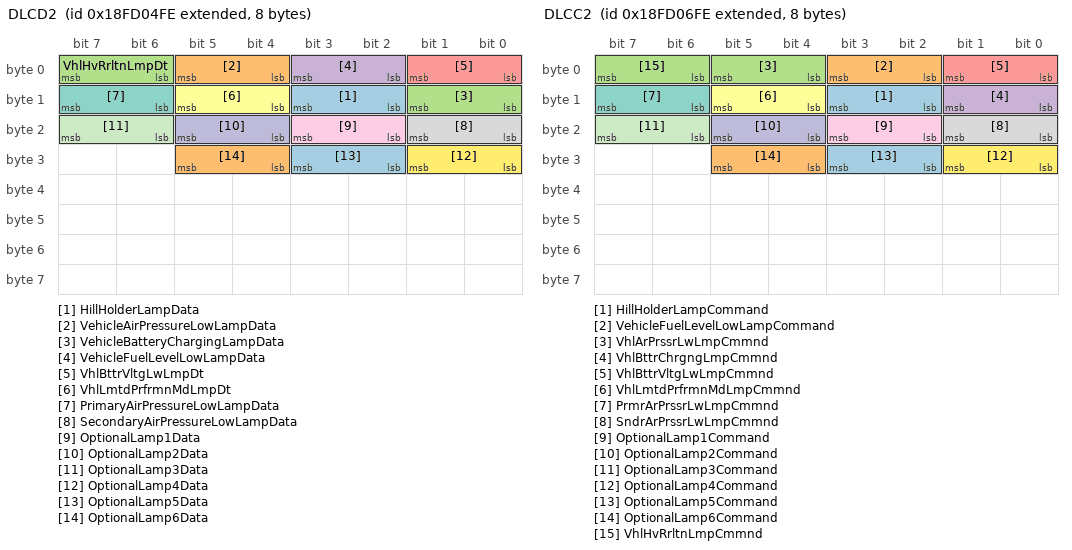
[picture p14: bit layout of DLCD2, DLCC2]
BO_ 2566718718 DLCD2: 8 Vector__XXX
 SG_ HillHolderLampData : 10|2@1+ (1,0) [0|3] "" Vector__XXX
 SG_ VehicleAirPressureLowLampData : 4|2@1+ (1,0) [0|3] "" Vector__XXX
 SG_ VehicleBatteryChargingLampData : 8|2@1+ (1,0) [0|3] "" Vector__XXX
 SG_ VehicleFuelLevelLowLampData : 2|2@1+ (1,0) [0|3] "" Vector__XXX
 SG_ VhlBttrVltgLwLmpDt : 0|2@1+ (1,0) [0|3] "" Vector__XXX
 SG_ VhlLmtdPrfrmnMdLmpDt : 12|2@1+ (1,0) [0|3] "" Vector__XXX
 SG_ PrimaryAirPressureLowLampData : 14|2@1+ (1,0) [0|3] "" Vector__XXX
 SG_ SecondaryAirPressureLowLampData : 16|2@1+ (1,0) [0|3] "" Vector__XXX
 SG_ OptionalLamp1Data : 18|2@1+ (1,0) [0|3] "" Vector__XXX
 SG_ OptionalLamp2Data : 20|2@1+ (1,0) [0|3] "" Vector__XXX
 SG_ OptionalLamp3Data : 22|2@1+ (1,0) [0|3] "" Vector__XXX
 SG_ OptionalLamp4Data : 24|2@1+ (1,0) [0|3] "" Vector__XXX
 SG_ OptionalLamp5Data : 26|2@1+ (1,0) [0|3] "" Vector__XXX
 SG_ OptionalLamp6Data : 28|2@1+ (1,0) [0|3] "" Vector__XXX
 SG_ VhlHvRrltnLmpDt : 6|2@1+ (1,0) [0|3] "" Vector__XXX

BO_ 2566718974 DLCD1: 8 Vector__XXX
 SG_ CmprssnBrkEnlSwthIndtrLmpDt : 10|2@1+ (1,0) [0|3] "" Vector__XXX
 SG_ EngineAmberWarningLampData : 2|2@1+ (1,0) [0|3] "" Vector__XXX
 SG_ EngineBrakeActiveLampData : 8|2@1+ (1,0) [0|3] "" Vector__XXX
 SG_ EngineCoolantLevelLowLampData : 16|2@1+ (1,0) [0|3] "" Vector__XXX
 SG_ EngineOilPressureLowLampData : 12|2@1+ (1,0) [0|3] "" Vector__XXX
 SG_ EngineProtectLampData : 0|2@1+ (1,0) [0|3] "" Vector__XXX
 SG_ EngineRedStopLampData : 4|2@1+ (1,0) [0|3] "" Vector__XXX
 SG_ EngineSpeedHighLampData : 30|2@1+ (1,0) [0|3] "" Vector__XXX
 SG_ EngineSpeedVeryHighLampData : 32|2@1+ (1,0) [0|3] "" Vector__XXX
 SG_ EngineWaitToStartLampData : 62|2@1+ (1,0) [0|3] "" Vector__XXX
 SG_ EngnArFltrRstrtnLmpDt : 20|2@1+ (1,0) [0|3] "" Vector__XXX
 SG_ EngnClntTmprtrHghLmpDt : 14|2@1+ (1,0) [0|3] "" Vector__XXX
 SG_ EngnCntrlMdl1RdFrUsLmpDt : 24|2@1+ (1,0) [0|3] "" Vector__XXX
 SG_ EngnCntrlMdl2RdFrUsLmpDt : 26|2@1+ (1,0) [0|3] "" Vector__XXX
 SG_ EngnCntrlMdl3RdFrUsLmpDt : 28|2@1+ (1,0) [0|3] "" Vector__XXX
 SG_ EngnFlFltrRstrtdLmpDt : 22|2@1+ (1,0) [0|3] "" Vector__XXX
 SG_ EngnIdlMngmntAtvLmpDt : 18|2@1+ (1,0) [0|3] "" Vector__XXX
 SG_ ObdMalfunctionIndicatorLampData : 6|2@1+ (1,0) [0|3] "" Vector__XXX
 SG_ VhlAlrtnRtLmtLmpDt : 34|2@1+ (1,0) [0|3] "" Vector__XXX
 SG_ EngnStpStrtAtmtStpAtvLmpDt : 38|2@1+ (1,0) [0|3] "" Vector__XXX
 SG_ EngnStpStrtAtmtStrtFldLmpDt : 40|2@1+ (1,0) [0|3] "" Vector__XXX
 SG_ EngineStopStartEnabledLampData : 42|2@1+ (1,0) [0|3] "" Vector__XXX
 SG_ EngnOlTmprtrHghLmpDt : 44|2@1+ (1,0) [0|3] "" Vector__XXX
 SG_ EngnFlTmprtrHghLmpDt : 46|2@1+ (1,0) [0|3] "" Vector__XXX
 SG_ EngnIntrlrTmprtrHghLmpDt : 48|2@1+ (1,0) [0|3] "" Vector__XXX
 SG_ EngineAirShutoffLampData : 50|2@1+ (1,0) [0|3] "" Vector__XXX
 SG_ EngineServiceLampData : 52|2@1+ (1,0) [0|3] "" Vector__XXX

BO_ 2566719230 DLCC2: 8 Vector__XXX
 SG_ HillHolderLampCommand : 10|2@1+ (1,0) [0|3] "" Vector__XXX
 SG_ VehicleFuelLevelLowLampCommand : 2|2@1+ (1,0) [0|3] "" Vector__XXX
 SG_ VhlArPrssrLwLmpCmmnd : 4|2@1+ (1,0) [0|3] "" Vector__XXX
 SG_ VhlBttrChrgngLmpCmmnd : 8|2@1+ (1,0) [0|3] "" Vector__XXX
 SG_ VhlBttrVltgLwLmpCmmnd : 0|2@1+ (1,0) [0|3] "" Vector__XXX
 SG_ VhlLmtdPrfrmnMdLmpCmmnd : 12|2@1+ (1,0) [0|3] "" Vector__XXX
 SG_ PrmrArPrssrLwLmpCmmnd : 14|2@1+ (1,0) [0|3] "" Vector__XXX
 SG_ SndrArPrssrLwLmpCmmnd : 16|2@1+ (1,0) [0|3] "" Vector__XXX
 SG_ OptionalLamp1Command : 18|2@1+ (1,0) [0|3] "" Vector__XXX
 SG_ OptionalLamp2Command : 20|2@1+ (1,0) [0|3] "" Vector__XXX
 SG_ OptionalLamp3Command : 22|2@1+ (1,0) [0|3] "" Vector__XXX
 SG_ OptionalLamp4Command : 24|2@1+ (1,0) [0|3] "" Vector__XXX
 SG_ OptionalLamp5Command : 26|2@1+ (1,0) [0|3] "" Vector__XXX
 SG_ OptionalLamp6Command : 28|2@1+ (1,0) [0|3] "" Vector__XXX
 SG_ VhlHvRrltnLmpCmmnd : 6|2@1+ (1,0) [0|3] "" Vector__XXX

BO_ 2566719486 DLCC1: 8 Vector__XXX
 SG_ CmprssnBrkEnlSwthIndtrLmpCmmnd : 10|2@1+ (1,0) [0|3] "" Vector__XXX
 SG_ EngineAmberWarningLampCommand : 2|2@1+ (1,0) [0|3] "" Vector__XXX
 SG_ EngineBrakeActiveLampCommand : 8|2@1+ (1,0) [0|3] "" Vector__XXX
 SG_ EngineOilPressureLowLampCommand : 12|2@1+ (1,0) [0|3] "" Vector__XXX
 SG_ EngineProtectLampCommand : 0|2@1+ (1,0) [0|3] "" Vector__XXX
 SG_ EngineRedStopLampCommand : 4|2@1+ (1,0) [0|3] "" Vector__XXX
 SG_ EngineSpeedHighLampCommand : 30|2@1+ (1,0) [0|3] "" Vector__XXX
 SG_ EngineSpeedVeryHighLampCommand : 32|2@1+ (1,0) [0|3] "" Vector__XXX
 SG_ EngnArFltrRstrtnLmpCmmnd : 20|2@1+ (1,0) [0|3] "" Vector__XXX
 SG_ EngnClntLvlLwLmpCmmnd : 16|2@1+ (1,0) [0|3] "" Vector__XXX
 SG_ EngnClntTmprtrHghLmpCmmnd : 14|2@1+ (1,0) [0|3] "" Vector__XXX
 SG_ EngnCntrlMdl1RdFrUsLmpCmmnd : 24|2@1+ (1,0) [0|3] "" Vector__XXX
 SG_ EngnCntrlMdl2RdFrUsLmpCmmnd : 26|2@1+ (1,0) [0|3] "" Vector__XXX
 SG_ EngnCntrlMdl3RdFrUsLmpCmmnd : 28|2@1+ (1,0) [0|3] "" Vector__XXX
 SG_ EngnFlFltrRstrtdLmpCmmnd : 22|2@1+ (1,0) [0|3] "" Vector__XXX
 SG_ EngnIdlMngmntAtvLmpCmmnd : 18|2@1+ (1,0) [0|3] "" Vector__XXX
 SG_ EngnIdlMngmntPndngEvntLmpCmmnd : 36|2@1+ (1,0) [0|3] "" Vector__XXX
 SG_ VhlAlrtnRtLmtLmpCmmnd : 34|2@1+ (1,0) [0|3] "" Vector__XXX
 SG_ EngnStpStrtAtmtStpAtvLmpCmmnd : 38|2@1+ (1,0) [0|3] "" Vector__XXX
 SG_ EngnStpStrtAtmtStrtFldLmpCmmnd : 40|2@1+ (1,0) [0|3] "" Vector__XXX
 SG_ EngnStpStrtEnldLmpCmmnd : 42|2@1+ (1,0) [0|3] "" Vector__XXX
 SG_ EngnOlTmprtrHghLmpCmmnd : 44|2@1+ (1,0) [0|3] "" Vector__XXX
 SG_ EngnFlTmprtrHghLmpCmmnd : 46|2@1+ (1,0) [0|3] "" Vector__XXX
 SG_ EngnIntrlrTmprtrHghLmpCmmnd : 48|2@1+ (1,0) [0|3] "" Vector__XXX
 SG_ EngineAirShutoffLampCommand : 50|2@1+ (1,0) [0|3] "" Vector__XXX
 SG_ OdMlfntnIndtrLmpCmmnd : 6|2@1+ (1,0) [0|3] "" Vector__XXX
 SG_ EngineServiceLampCommand : 52|2@1+ (1,0) [0|3] "" Vector__XXX

BO_ 2566719998 HRLFC: 8 Vector__XXX
 SG_ EngineTripFuelHighResolution : 0|32@1+ (0.001,0) [0|4211081.215] "l" Vector__XXX
 SG_ EngnTtlFlUsdHghRsltn : 32|32@1+ (0.001,0) [0|4211081.215] "l" Vector__XXX

BO_ 2566722302 MSI1: 8 Vector__XXX
 SG_ GeneratorOverheatStatus : 0|2@1+ (1,0) [0|3] "" Vector__XXX
 SG_ GensetEnableActiveStatus : 16|2@1+ (1,0) [0|3] "" Vector__XXX
 SG_ GensetSoftstartActiveStatus : 6|2@1+ (1,0) [0|3] "" Vector__XXX
 SG_ GnrtrDtClExddStts : 20|2@1+ (1,0) [0|3] "" Vector__XXX
 SG_ GnstSstmOtptVltgRngStts : 2|2@1+ (1,0) [0|3] "" Vector__XXX
 SG_ GrappleMagnetSelectionSwitch : 4|2@1+ (1,0) [0|3] "" Vector__XXX
 SG_ ReverseCurrentRangeSetting : 8|5@1+ (1,0) [0|31] "" Vector__XXX
 SG_ VoltageMonitorActiveStatus : 18|2@1+ (1,0) [0|3] "" Vector__XXX

BO_ 2566722558 MSCI: 8 Vector__XXX
 SG_ MagnetBoostTime : 0|8@1+ (0.25,0) [0|62.5] "s" Vector__XXX
 SG_ MagnetRatedPower : 8|16@1+ (0.5,0) [0|32127.5] "kW" Vector__XXX

BO_ 2566722814 BCH2: 8 Vector__XXX
 SG_ BatteryCharger2OutputCurrent : 24|16@1+ (0.05,-1600) [-1600|1612.75] "A" Vector__XXX
 SG_ BatteryCharger2OutputVoltage : 8|16@1+ (0.05,0) [0|3212.75] "V" Vector__XXX
 SG_ BatteryCharger2PowerLineState : 4|2@1+ (1,0) [0|3] "" Vector__XXX
 SG_ BatteryCharger2State : 0|4@1+ (1,0) [0|15] "" Vector__XXX
 SG_ BatteryCharger2RestartState : 6|2@1+ (1,0) [0|3] "" Vector__XXX
 SG_ BatteryCharger2LimitType : 40|4@1+ (1,0) [0|15] "" Vector__XXX
 SG_ BatteryCharger2LimitSource : 44|4@1+ (1,0) [0|15] "" Vector__XXX

BO_ 2566723070 BCH1: 8 Vector__XXX
 SG_ BatteryCharger1OutputCurrent : 24|16@1+ (0.05,-1600) [-1600|1612.75] "A" Vector__XXX
 SG_ BatteryCharger1OutputVoltage : 8|16@1+ (0.05,0) [0|3212.75] "V" Vector__XXX
 SG_ BatteryCharger1PowerLineState : 4|2@1+ (1,0) [0|3] "" Vector__XXX
 SG_ BatteryCharger1State : 0|4@1+ (1,0) [0|15] "" Vector__XXX
 SG_ BatteryCharger1RestartState : 6|2@1+ (1,0) [0|3] "" Vector__XXX
 SG_ BatteryCharger1LimitType : 40|4@1+ (1,0) [0|15] "" Vector__XXX
 SG_ BatteryCharger1LimitSource : 44|4@1+ (1,0) [0|15] "" Vector__XXX

BO_ 2566724350 AT1WUDOC: 8 Vector__XXX
 SG_ Atttt1WUpDsOxdtCtstItTpt : 0|16@1+ (0.03125,-273) [-273|1734.96875] "degC" Vector__XXX
 SG_ Atttt1WUpDsOxdtCtstOttTpt : 16|16@1+ (0.03125,-273) [-273|1734.96875] "degC" Vector__XXX

BO_ 2566724606 DPF2S: 8 Vector__XXX
 SG_ Aftrtrtmnt2DslPrtltFltrMnStSgnl : 16|16@1+ (0.0025,0) [0|160.6375] "%" Vector__XXX
 SG_ Aftrtrtmnt2DslPrtltFltrStDnst : 8|8@1+ (0.08,0) [0|20] "g/L" Vector__XXX
 SG_ Aftrtrtmnt2DslPrtltFltrStMss : 0|8@1+ (4,0) [0|1000] "g" Vector__XXX
 SG_ Atttt2DsPttFtMdStS : 32|16@1+ (0.0025,0) [0|160.6375] "%" Vector__XXX
 SG_ Atttt2DsPttFtStSsPF : 48|5@1+ (1,0) [0|31] "" Vector__XXX
 SG_ DsPttFt2StSsEItTpt : 56|8@1+ (1,-40) [-40|210] "degC" Vector__XXX

BO_ 2566724862 DPF1S: 8 Vector__XXX
 SG_ Aftrtrtmnt1DslPrtltFltrMnStSgnl : 16|16@1+ (0.0025,0) [0|160.6375] "%" Vector__XXX
 SG_ Aftrtrtmnt1DslPrtltFltrStDnst : 8|8@1+ (0.08,0) [0|20] "g/L" Vector__XXX
 SG_ Aftrtrtmnt1DslPrtltFltrStMss : 0|8@1+ (4,0) [0|1000] "g" Vector__XXX
 SG_ Atttt1DsPttFtMdStS : 32|16@1+ (0.0025,0) [0|160.6375] "%" Vector__XXX
 SG_ Atttt1DsPttFtStSsPF : 48|5@1+ (1,0) [0|31] "" Vector__XXX
 SG_ DsPttFt1StSsEItTpt : 56|8@1+ (1,-40) [-40|210] "degC" Vector__XXX

BO_ 2566725118 ATDT2: 8 Vector__XXX
 SG_ Atttt1TWCtstDtTpt : 0|16@1+ (0.03125,-273) [-273|1734.96875] "degC" Vector__XXX
 SG_ Atttt2TWCtstDtTpt : 16|16@1+ (0.03125,-273) [-273|1734.96875] "degC" Vector__XXX

BO_ 2566725374 ATDT1: 8 Vector__XXX
 SG_ Atttt1GsOxdtCtstDtTpt : 0|16@1+ (0.03125,-273) [-273|1734.96875] "degC" Vector__XXX
 SG_ Atttt2GsOxdtCtstDtTpt : 16|16@1+ (0.03125,-273) [-273|1734.96875] "degC" Vector__XXX

BO_ 2566725630 A2DOC1: 8 Vector__XXX
 SG_ Atttt2DsOxdtCtstDtPss : 32|16@1+ (0.5,0) [0|32127.5] "kPa" Vector__XXX
 SG_ Atttt2DsOxdtCtstItTpt : 0|16@1+ (0.03125,-273) [-273|1734.96875] "degC" Vector__XXX
 SG_ Atttt2DsOxdtCtstOttTpt : 16|16@1+ (0.03125,-273) [-273|1734.96875] "degC" Vector__XXX
 SG_ Atttt2DsOxdtCtstItTptPF : 48|5@1+ (1,0) [0|31] "" Vector__XXX
 SG_ Atttt2DsOxdtCtstOttTptPF : 53|5@1+ (1,0) [0|31] "" Vector__XXX
 SG_ Atttt2DsOxdtCtstDtPssPF : 58|5@1+ (1,0) [0|31] "" Vector__XXX

BO_ 2566725886 A1DOC1: 8 Vector__XXX
 SG_ Atttt1DsOxdtCtstDtPss : 32|16@1+ (0.1,0) [0|6425.5] "kPa" Vector__XXX
 SG_ Atttt1DsOxdtCtstItTpt : 0|16@1+ (0.03125,-273) [-273|1734.96875] "degC" Vector__XXX
 SG_ Atttt1DsOxdtCtstOttTpt : 16|16@1+ (0.03125,-273) [-273|1734.96875] "degC" Vector__XXX
 SG_ Atttt1DsOxdtCtstItTptPF : 48|5@1+ (1,0) [0|31] "" Vector__XXX
 SG_ Atttt1DsOxdtCtstOttTptPF : 53|5@1+ (1,0) [0|31] "" Vector__XXX
 SG_ Atttt1DsOxdtCtstDtPssPF : 58|5@1+ (1,0) [0|31] "" Vector__XXX

BO_ 2566726142 A2GOC: 8 Vector__XXX
 SG_ Atttt2GsOxdtCtstDtPss : 32|16@1+ (0.1,0) [0|6425.5] "kPa" Vector__XXX
 SG_ Atttt2GsOxdtCtstItTpt : 0|16@1+ (0.03125,-273) [-273|1734.96875] "degC" Vector__XXX
 SG_ Atttt2GsOxdtCtstOttTpt : 16|16@1+ (0.03125,-273) [-273|1734.96875] "degC" Vector__XXX
 SG_ Atttt2GsOxdtCtstItTptPF : 48|5@1+ (1,0) [0|31] "" Vector__XXX
 SG_ Atttt2GsOxdtCtstOttTptPF : 53|5@1+ (1,0) [0|31] "" Vector__XXX
 SG_ Atttt2GsOxdtCtstDtPssPF : 58|5@1+ (1,0) [0|31] "" Vector__XXX

BO_ 2566726398 A1GOC: 8 Vector__XXX
 SG_ Atttt1GsOxdtCtstDtPss : 32|16@1+ (0.1,0) [0|6425.5] "kPa" Vector__XXX
 SG_ Atttt1GsOxdtCtstItTpt : 0|16@1+ (0.03125,-273) [-273|1734.96875] "degC" Vector__XXX
 SG_ Atttt1GsOxdtCtstOttTpt : 16|16@1+ (0.03125,-273) [-273|1734.96875] "degC" Vector__XXX
 SG_ Atttt1GsOxdtCtstItTptPF : 48|5@1+ (1,0) [0|31] "" Vector__XXX
 SG_ Atttt1GsOxdtCtstOttTptPF : 53|5@1+ (1,0) [0|31] "" Vector__XXX
 SG_ Atttt1GsOxdtCtstDtPssPF : 58|5@1+ (1,0) [0|31] "" Vector__XXX

BO_ 2566730238 FD2: 8 Vector__XXX
 SG_ EstimatedPercentFan2Speed : 0|8@1+ (0.4,0) [0|100] "%" Vector__XXX
 SG_ Fan2DriveBypassCommandStatus : 48|8@1+ (0.4,0) [0|100] "%" Vector__XXX
 SG_ Fan2DriveState : 8|4@1+ (1,0) [0|15] "" Vector__XXX
 SG_ Fan2Speed : 16|16@1+ (0.125,0) [0|8031.875] "rpm" Vector__XXX
 SG_ HydraulicFan2MotorPressure : 32|16@1+ (0.5,0) [0|32127.5] "kPa" Vector__XXX

BO_ 2566730750 A2DEFSI: 8 Vector__XXX
 SG_ Aftrtrtmnt2DslExhstFldPmp : 44|2@1+ (1,0) [0|3] "" Vector__XXX
 SG_ Aftrtrtmnt2DslExhstFldPmpPwrRl : 42|2@1+ (1,0) [0|3] "" Vector__XXX
 SG_ Aftrtrtmnt2DslExhstFldPmpStt : 40|2@1+ (1,0) [0|3] "" Vector__XXX
 SG_ Atttt2DsExstFdDsUt1DvtVv : 24|8@1+ (0.4,0) [0|100] "%" Vector__XXX
 SG_ Atttt2DsExstFdDsUt2DvtVv : 56|8@1+ (0.4,0) [0|100] "%" Vector__XXX
 SG_ Atttt2DsExstFdPp1MtSpd : 0|16@1+ (0.5,0) [0|32127.5] "rpm" Vector__XXX
 SG_ Atttt2DsExstFdPpDvPt : 16|8@1+ (0.4,0) [0|100] "%" Vector__XXX
 SG_ Atttt2DsExstFdTDVvCd : 48|8@1+ (0.4,0) [0|100] "%" Vector__XXX
 SG_ Atttt2DsExstFdTFVvCd : 32|8@1+ (0.4,0) [0|100] "%" Vector__XXX

BO_ 2566731006 A2SCRRT2I: 8 Vector__XXX
 SG_ Atttt2DsExstFdQTwTLv : 16|16@1+ (0.1,0) [0|6425.5] "mm" Vector__XXX
 SG_ Atttt2DsExstFdQTwTV : 0|8@1+ (0.4,0) [0|100] "%" Vector__XXX
 SG_ Atttt2DsExstFdQTwTTpt : 8|8@1+ (1,-40) [-40|210] "degC" Vector__XXX
 SG_ Atttt2DsExstFdQTwTLvPF : 32|5@1+ (1,0) [0|31] "" Vector__XXX
 SG_ Atttt2DsExstFdQTwTTptPF : 40|5@1+ (1,0) [0|31] "" Vector__XXX
 SG_ Atttt2DsExstFdQTwTHt : 48|8@1+ (0.4,0) [0|100] "%" Vector__XXX
 SG_ Atttt2DsExstFdQTwTHtPF : 56|5@1+ (1,0) [0|31] "" Vector__XXX

BO_ 2566731262 A2DEFT1I1: 8 Vector__XXX
 SG_ Aftrtrtmnt2DslExhstFldTnkHtr : 48|8@1+ (0.4,0) [0|100] "%" Vector__XXX
 SG_ Aftrtrtmnt2DslExhstFldTnkLvl : 16|16@1+ (0.1,0) [0|6425.5] "mm" Vector__XXX
 SG_ Aftrtrtmnt2DslExhstFldTnkVlm : 0|8@1+ (0.4,0) [0|100] "%" Vector__XXX
 SG_ Atttt2DsExstFdTTpt1 : 8|8@1+ (1,-40) [-40|210] "degC" Vector__XXX
 SG_ Atttt2DsExstFdTLvVPF : 32|5@1+ (1,0) [0|31] "" Vector__XXX
 SG_ Atttt2DsExstFdT1TptPF : 40|5@1+ (1,0) [0|31] "" Vector__XXX
 SG_ Atttt2DsExstFdT1HtPF : 56|5@1+ (1,0) [0|31] "" Vector__XXX

BO_ 2566731518 A2DEFI1: 8 Vector__XXX
 SG_ Aftrtrtmnt2DslExhstFldCndtvt : 16|8@1+ (5,0) [0|1250] "muSiemens/mm" Vector__XXX
 SG_ Aftrtrtmnt2DslExhstFldCnntrtn : 8|8@1+ (0.25,0) [0|62.5] "%" Vector__XXX
 SG_ Aftrtrtmnt2DslExhstFldTmprtr2 : 0|8@1+ (1,-40) [-40|210] "degC" Vector__XXX
 SG_ Aftrtrtmnt2DslExhstFldTpPrprt : 40|4@1+ (1,0) [0|15] "" Vector__XXX
 SG_ Atttt2DsExstFdTpt2PF : 24|5@1+ (1,0) [0|31] "" Vector__XXX
 SG_ Atttt2DsExstFdPptsPF : 32|5@1+ (1,0) [0|31] "" Vector__XXX

BO_ 2566731774 A2SCRSI1: 8 Vector__XXX
 SG_ Atttt2DsExstFdAvCspt : 0|16@1+ (0.05,0) [0|3212.75] "l/h" Vector__XXX
 SG_ Atttt2SCddDsExstFdCspt : 16|16@1+ (0.05,0) [0|3212.75] "l/h" Vector__XXX
 SG_ Aftrtrtmnt2SrCnvrsnEffn : 32|8@1+ (0.4,0) [0|100] "%" Vector__XXX
 SG_ Aftrtrtmnt2SrSstmSlftnLvl : 40|8@1+ (1,0) [0|250] "%" Vector__XXX
 SG_ Atttt2DsExstFdUsdTsOptC : 48|16@1+ (0.1,0) [0|6425.5] "l" Vector__XXX

BO_ 2566732030 A2SCREGT1: 8 Vector__XXX
 SG_ Aftrtrtmnt2SrIntkTmprtr : 0|16@1+ (0.03125,-273) [-273|1734.96875] "degC" Vector__XXX
 SG_ Aftrtrtmnt2SrIntkTmprtrPrlmnrFm : 16|5@1+ (1,0) [0|31] "" Vector__XXX
 SG_ Aftrtrtmnt2SrOtltTmprtr : 24|16@1+ (0.03125,-273) [-273|1734.96875] "degC" Vector__XXX
 SG_ Aftrtrtmnt2SrOtltTmprtrPrlmnrFm : 40|5@1+ (1,0) [0|31] "" Vector__XXX

BO_ 2566732286 A2SCREGP: 8 Vector__XXX
 SG_ Aftrtrtmnt2SrDffrntlPrssr : 0|16@1+ (0.1,0) [0|6425.5] "kPa" Vector__XXX
 SG_ Atttt2SDtPssPF : 16|5@1+ (1,0) [0|31] "" Vector__XXX
 SG_ Aftrtrtmnt2SrIntkPrssr : 24|16@1+ (0.1,-3212.7) [-3212.7|3212.8] "kPa" Vector__XXX
 SG_ Aftrtrtmnt2SrIntkAsltPrssr : 40|16@1+ (0.1,0) [0|6425.5] "kPa" Vector__XXX

BO_ 2566732542 A2SCRDSR2: 8 Vector__XXX
 SG_ Aftrtrtmnt2DslExhstFldLnHtr1 : 8|2@1+ (1,0) [0|3] "" Vector__XXX
 SG_ Aftrtrtmnt2DslExhstFldLnHtr10 : 48|2@1+ (1,0) [0|3] "" Vector__XXX
 SG_ Aftrtrtmnt2DslExhstFldLnHtr2 : 10|2@1+ (1,0) [0|3] "" Vector__XXX
 SG_ Aftrtrtmnt2DslExhstFldLnHtr3 : 12|2@1+ (1,0) [0|3] "" Vector__XXX
 SG_ Aftrtrtmnt2DslExhstFldLnHtr4 : 14|2@1+ (1,0) [0|3] "" Vector__XXX
 SG_ Aftrtrtmnt2DslExhstFldLnHtr5 : 38|2@1+ (1,0) [0|3] "" Vector__XXX
 SG_ Aftrtrtmnt2DslExhstFldLnHtr6 : 40|2@1+ (1,0) [0|3] "" Vector__XXX
 SG_ Aftrtrtmnt2DslExhstFldLnHtr7 : 42|2@1+ (1,0) [0|3] "" Vector__XXX
 SG_ Aftrtrtmnt2DslExhstFldLnHtr8 : 44|2@1+ (1,0) [0|3] "" Vector__XXX
 SG_ Aftrtrtmnt2DslExhstFldLnHtr9 : 46|2@1+ (1,0) [0|3] "" Vector__XXX
 SG_ Aftrtrtmnt2DslExhstFldLnHtrRl1 : 32|2@1+ (1,0) [0|3] "" Vector__XXX
 SG_ Aftrtrtmnt2DslExhstFldLnHtrRl2 : 34|2@1+ (1,0) [0|3] "" Vector__XXX
 SG_ Aftrtrtmnt2DslExhstFldLnHtrRl3 : 36|2@1+ (1,0) [0|3] "" Vector__XXX
 SG_ Atttt2DsExstFdDsFtSppssRqst : 2|2@1+ (1,0) [0|3] "" Vector__XXX
 SG_ Atttt2DsExstFdDsHtMdRqst : 4|3@1+ (1,0) [0|7] "" Vector__XXX
 SG_ Atttt2DsExstFdTHtCd : 16|8@1+ (0.4,0) [0|100] "%" Vector__XXX
 SG_ Atttt2DsExstFdQTwTHtCd : 24|8@1+ (0.4,0) [0|100] "%" Vector__XXX

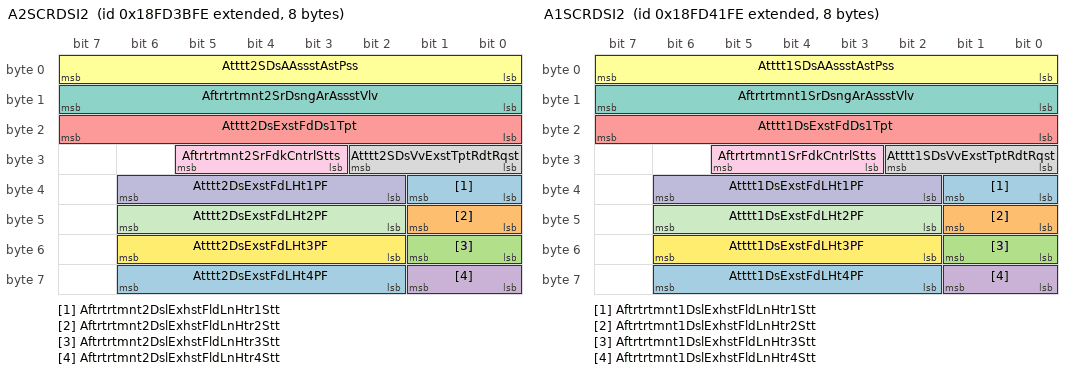
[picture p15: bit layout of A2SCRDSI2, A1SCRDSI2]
BO_ 2566732798 A2SCRDSI2: 8 Vector__XXX
 SG_ Aftrtrtmnt2DslExhstFldLnHtr1Stt : 32|2@1+ (1,0) [0|3] "" Vector__XXX
 SG_ Aftrtrtmnt2DslExhstFldLnHtr2Stt : 40|2@1+ (1,0) [0|3] "" Vector__XXX
 SG_ Aftrtrtmnt2DslExhstFldLnHtr3Stt : 48|2@1+ (1,0) [0|3] "" Vector__XXX
 SG_ Aftrtrtmnt2DslExhstFldLnHtr4Stt : 56|2@1+ (1,0) [0|3] "" Vector__XXX
 SG_ Atttt2DsExstFdDs1Tpt : 16|8@1+ (1,-40) [-40|210] "degC" Vector__XXX
 SG_ Atttt2SDsAAssstAstPss : 0|8@1+ (8,0) [0|2000] "kPa" Vector__XXX
 SG_ Aftrtrtmnt2SrDsngArAssstVlv : 8|8@1+ (0.4,0) [0|100] "%" Vector__XXX
 SG_ Atttt2SDsVvExstTptRdtRqst : 24|3@1+ (1,0) [0|7] "" Vector__XXX
 SG_ Aftrtrtmnt2SrFdkCntrlStts : 27|3@1+ (1,0) [0|7] "" Vector__XXX
 SG_ Atttt2DsExstFdLHt1PF : 34|5@1+ (1,0) [0|31] "" Vector__XXX
 SG_ Atttt2DsExstFdLHt2PF : 42|5@1+ (1,0) [0|31] "" Vector__XXX
 SG_ Atttt2DsExstFdLHt3PF : 50|5@1+ (1,0) [0|31] "" Vector__XXX
 SG_ Atttt2DsExstFdLHt4PF : 58|5@1+ (1,0) [0|31] "" Vector__XXX

BO_ 2566733054 A1DEFSI: 8 Vector__XXX
 SG_ Aftrtrtmnt1DslExhstFldPmp : 44|2@1+ (1,0) [0|3] "" Vector__XXX
 SG_ Aftrtrtmnt1DslExhstFldPmpPwrRl : 42|2@1+ (1,0) [0|3] "" Vector__XXX
 SG_ Aftrtrtmnt1DslExhstFldPmpStt : 40|2@1+ (1,0) [0|3] "" Vector__XXX
 SG_ Atttt1DsExstFdDsUt1DvtVv : 24|8@1+ (0.4,0) [0|100] "%" Vector__XXX
 SG_ Atttt1DsExstFdDsUt2DvtVv : 56|8@1+ (0.4,0) [0|100] "%" Vector__XXX
 SG_ Atttt1DsExstFdPp1MtSpd : 0|16@1+ (0.5,0) [0|32127.5] "rpm" Vector__XXX
 SG_ Atttt1DsExstFdPpDvPt : 16|8@1+ (0.4,0) [0|100] "%" Vector__XXX
 SG_ Atttt1DsExstFdTDVvCd : 48|8@1+ (0.4,0) [0|100] "%" Vector__XXX
 SG_ Atttt1DsExstFdTFVvCd : 32|8@1+ (0.4,0) [0|100] "%" Vector__XXX

BO_ 2566733310 A1SCRRT2I: 8 Vector__XXX
 SG_ Atttt1DsExstFdQTwTLv : 16|16@1+ (0.1,0) [0|6425.5] "mm" Vector__XXX
 SG_ Atttt1DsExstFdQTwTV : 0|8@1+ (0.4,0) [0|100] "%" Vector__XXX
 SG_ Atttt1DsExstFdQTwTTpt : 8|8@1+ (1,-40) [-40|210] "degC" Vector__XXX
 SG_ Atttt1DsExstFdQTwTLvVPF : 32|5@1+ (1,0) [0|31] "" Vector__XXX
 SG_ Atttt1DsExstFdQTwTTptPF : 40|5@1+ (1,0) [0|31] "" Vector__XXX
 SG_ Atttt1DsExstFdQTwTHt : 48|8@1+ (0.4,0) [0|100] "%" Vector__XXX
 SG_ Atttt1DsExstFdQTwTHtPF : 56|5@1+ (1,0) [0|31] "" Vector__XXX

BO_ 2566733822 A1SCREGP: 8 Vector__XXX
 SG_ Aftrtrtmnt1SrDffrntlPrssr : 0|16@1+ (0.1,0) [0|6425.5] "kPa" Vector__XXX
 SG_ Atttt1SDtPssPF : 16|5@1+ (1,0) [0|31] "" Vector__XXX
 SG_ Aftrtrtmnt1SrIntkPrssr : 24|16@1+ (0.1,-3212.7) [-3212.7|3212.8] "kPa" Vector__XXX
 SG_ Aftrtrtmnt1SrIntkAsltPrssr : 40|16@1+ (0.1,0) [0|6425.5] "kPa" Vector__XXX

BO_ 2566734078 A1SCRDSR2: 8 Vector__XXX
 SG_ Aftrtrtmnt1DslExhstFldLnHtr1 : 8|2@1+ (1,0) [0|3] "" Vector__XXX
 SG_ Aftrtrtmnt1DslExhstFldLnHtr10 : 56|2@1+ (1,0) [0|3] "" Vector__XXX
 SG_ Aftrtrtmnt1DslExhstFldLnHtr2 : 10|2@1+ (1,0) [0|3] "" Vector__XXX
 SG_ Aftrtrtmnt1DslExhstFldLnHtr3 : 12|2@1+ (1,0) [0|3] "" Vector__XXX
 SG_ Aftrtrtmnt1DslExhstFldLnHtr4 : 14|2@1+ (1,0) [0|3] "" Vector__XXX
 SG_ Aftrtrtmnt1DslExhstFldLnHtr5 : 46|2@1+ (1,0) [0|3] "" Vector__XXX
 SG_ Aftrtrtmnt1DslExhstFldLnHtr6 : 48|2@1+ (1,0) [0|3] "" Vector__XXX
 SG_ Aftrtrtmnt1DslExhstFldLnHtr7 : 50|2@1+ (1,0) [0|3] "" Vector__XXX
 SG_ Aftrtrtmnt1DslExhstFldLnHtr8 : 52|2@1+ (1,0) [0|3] "" Vector__XXX
 SG_ Aftrtrtmnt1DslExhstFldLnHtr9 : 54|2@1+ (1,0) [0|3] "" Vector__XXX
 SG_ Aftrtrtmnt1DslExhstFldLnHtrRl1 : 40|2@1+ (1,0) [0|3] "" Vector__XXX
 SG_ Aftrtrtmnt1DslExhstFldLnHtrRl2 : 42|2@1+ (1,0) [0|3] "" Vector__XXX
 SG_ Aftrtrtmnt1DslExhstFldLnHtrRl3 : 44|2@1+ (1,0) [0|3] "" Vector__XXX
 SG_ Atttt1DsExstFdDsFtSppssRqst : 2|2@1+ (1,0) [0|3] "" Vector__XXX
 SG_ Atttt1DsExstFdDsHtMdRqst : 4|3@1+ (1,0) [0|7] "" Vector__XXX
 SG_ Atttt1DsExstFdPpHtCd : 32|8@1+ (0.4,0) [0|100] "%" Vector__XXX
 SG_ Atttt1DsExstFdTHtCd : 16|8@1+ (0.4,0) [0|100] "%" Vector__XXX
 SG_ Atttt1DsExstFdQTwTHtCd : 24|8@1+ (0.4,0) [0|100] "%" Vector__XXX

BO_ 2566734334 A1SCRDSI2: 8 Vector__XXX
 SG_ Aftrtrtmnt1DslExhstFldLnHtr1Stt : 32|2@1+ (1,0) [0|3] "" Vector__XXX
 SG_ Aftrtrtmnt1DslExhstFldLnHtr2Stt : 40|2@1+ (1,0) [0|3] "" Vector__XXX
 SG_ Aftrtrtmnt1DslExhstFldLnHtr3Stt : 48|2@1+ (1,0) [0|3] "" Vector__XXX
 SG_ Aftrtrtmnt1DslExhstFldLnHtr4Stt : 56|2@1+ (1,0) [0|3] "" Vector__XXX
 SG_ Atttt1DsExstFdDs1Tpt : 16|8@1+ (1,-40) [-40|210] "degC" Vector__XXX
 SG_ Atttt1SDsAAssstAstPss : 0|8@1+ (8,0) [0|2000] "kPa" Vector__XXX
 SG_ Aftrtrtmnt1SrDsngArAssstVlv : 8|8@1+ (0.4,0) [0|100] "%" Vector__XXX
 SG_ Atttt1SDsVvExstTptRdtRqst : 24|3@1+ (1,0) [0|7] "" Vector__XXX
 SG_ Aftrtrtmnt1SrFdkCntrlStts : 27|3@1+ (1,0) [0|7] "" Vector__XXX
 SG_ Atttt1DsExstFdLHt1PF : 34|5@1+ (1,0) [0|31] "" Vector__XXX
 SG_ Atttt1DsExstFdLHt2PF : 42|5@1+ (1,0) [0|31] "" Vector__XXX
 SG_ Atttt1DsExstFdLHt3PF : 50|5@1+ (1,0) [0|31] "" Vector__XXX
 SG_ Atttt1DsExstFdLHt4PF : 58|5@1+ (1,0) [0|31] "" Vector__XXX

BO_ 2566735102 AT2FC2: 8 Vector__XXX
 SG_ Aftertreatment2FuelPressure2 : 0|16@1+ (0.1,0) [0|6425.5] "kPa" Vector__XXX
 SG_ Aftrtrtmnt2FlFlwDvrtrVlvCntrl : 18|2@1+ (1,0) [0|3] "" Vector__XXX
 SG_ Aftrtrtmnt2FlPmpRlCntrl : 16|2@1+ (1,0) [0|3] "" Vector__XXX
 SG_ Aftrtrtmnt2FlPrssr2Cntrl : 24|16@1+ (0.0025,0) [0|160.6375] "%" Vector__XXX

BO_ 2566735358 AT2TWC: 8 Vector__XXX
 SG_ Aftrtrtmnt2ThrWCtlstIntkTmprtr : 0|16@1+ (0.03125,-273) [-273|1734.96875] "degC" Vector__XXX
 SG_ Aftrtrtmnt2ThrWCtlstOtltTmprtr : 16|16@1+ (0.03125,-273) [-273|1734.96875] "degC" Vector__XXX
 SG_ Atttt2TWCtstDtPss : 32|16@1+ (0.1,0) [0|6425.5] "kPa" Vector__XXX
 SG_ Atttt2TWCtstItTptPF : 48|5@1+ (1,0) [0|31] "" Vector__XXX
 SG_ Atttt2TWCtstOttTptPF : 53|5@1+ (1,0) [0|31] "" Vector__XXX
 SG_ Atttt2TWCttCvtDtPssPF : 58|5@1+ (1,0) [0|31] "" Vector__XXX

BO_ 2566735614 AT1TWC: 8 Vector__XXX
 SG_ Aftrtrtmnt1ThrWCtlstIntkTmprtr : 0|16@1+ (0.03125,-273) [-273|1734.96875] "degC" Vector__XXX
 SG_ Aftrtrtmnt1ThrWCtlstOtltTmprtr : 16|16@1+ (0.03125,-273) [-273|1734.96875] "degC" Vector__XXX
 SG_ Atttt1TWCtstDtPss : 32|16@1+ (0.1,0) [0|6425.5] "kPa" Vector__XXX
 SG_ Atttt1TWCtstItTptPF : 48|5@1+ (1,0) [0|31] "" Vector__XXX
 SG_ Atttt1TWCtstOttTptPF : 53|5@1+ (1,0) [0|31] "" Vector__XXX
 SG_ Atttt1TWCttCvtDtPssPF : 58|5@1+ (1,0) [0|31] "" Vector__XXX

BO_ 2566736126 O2FT2: 8 Vector__XXX
 SG_ EngnExhstBnk2O2SnsrClsdLpOprtn : 32|4@1+ (1,0) [0|15] "" Vector__XXX
 SG_ LongTermFuelTrimBank2 : 0|16@1+ (0.1,-100) [-100|100] "%" Vector__XXX
 SG_ ShortTermFuelTrimBank2 : 16|16@1+ (0.1,-100) [-100|100] "%" Vector__XXX

BO_ 2566736382 O2FT1: 8 Vector__XXX
 SG_ EngnExhstBnk1O2SnsrClsdLpOprtn : 32|4@1+ (1,0) [0|15] "" Vector__XXX
 SG_ LongTermFuelTrimBank1 : 0|16@1+ (0.1,-100) [-100|100] "%" Vector__XXX
 SG_ ShortTermFuelTrimBank1 : 16|16@1+ (0.1,-100) [-100|100] "%" Vector__XXX

BO_ 2566743550 AT1FC2: 8 Vector__XXX
 SG_ Aftertreatment1FuelPressure2 : 0|16@1+ (0.1,0) [0|6425.5] "kPa" Vector__XXX
 SG_ Aftrtrtmnt1FlFlwDvrtrVlvCntrl : 18|2@1+ (1,0) [0|3] "" Vector__XXX
 SG_ Aftrtrtmnt1FlPmpRlCntrl : 16|2@1+ (1,0) [0|3] "" Vector__XXX
 SG_ Aftrtrtmnt1HdrrnDsrIntkFlTmprtr : 40|8@1+ (1,-40) [-40|210] "degC" Vector__XXX
 SG_ Aftrtrtmnt1FlPrssr2Cntrl : 24|16@1+ (0.0025,0) [0|160.6375] "%" Vector__XXX

BO_ 2566743806 ET4: 8 Vector__XXX
 SG_ EngineCoolantTemperature2 : 0|8@1+ (1,-40) [-40|210] "degC" Vector__XXX
 SG_ EngineCoolantTemperature3 : 56|8@1+ (1,-40) [-40|210] "degC" Vector__XXX
 SG_ EngineCoolantThermostatOpening : 16|8@1+ (0.4,0) [0|100] "%" Vector__XXX
 SG_ EngnClntPmpOtltTmprtr : 8|8@1+ (1,-40) [-40|210] "degC" Vector__XXX
 SG_ EngnExhstGsRrltn1MxrIntkTmprtr : 40|16@1+ (0.03125,-273) [-273|1734.96875] "degC" Vector__XXX
 SG_ EngnExhstVlvAttnSstmOlTmprtr : 24|16@1+ (0.03125,-273) [-273|1734.96875] "degC" Vector__XXX

BO_ 2566744062 ZNVW: 8 Vector__XXX
 SG_ ZeroNetVehicleWeightChange : 0|2@1+ (1,0) [0|3] "" Vector__XXX

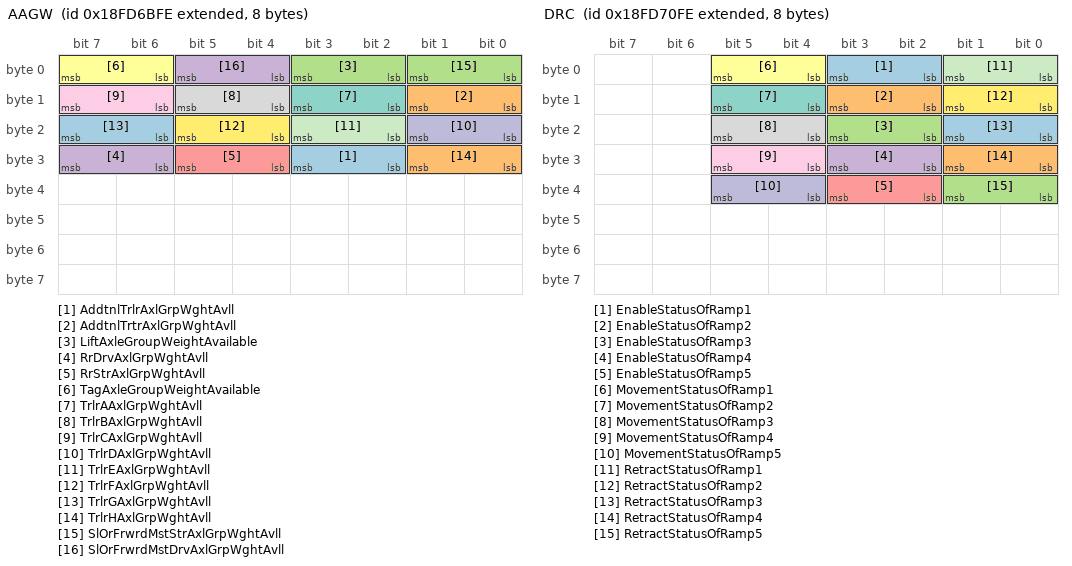
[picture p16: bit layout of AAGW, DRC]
BO_ 2566745086 AAGW: 8 Vector__XXX
 SG_ AddtnlTrlrAxlGrpWghtAvll : 26|2@1+ (1,0) [0|3] "" Vector__XXX
 SG_ AddtnlTrtrAxlGrpWghtAvll : 8|2@1+ (1,0) [0|3] "" Vector__XXX
 SG_ LiftAxleGroupWeightAvailable : 2|2@1+ (1,0) [0|3] "" Vector__XXX
 SG_ RrDrvAxlGrpWghtAvll : 30|2@1+ (1,0) [0|3] "" Vector__XXX
 SG_ RrStrAxlGrpWghtAvll : 28|2@1+ (1,0) [0|3] "" Vector__XXX
 SG_ TagAxleGroupWeightAvailable : 6|2@1+ (1,0) [0|3] "" Vector__XXX
 SG_ TrlrAAxlGrpWghtAvll : 10|2@1+ (1,0) [0|3] "" Vector__XXX
 SG_ TrlrBAxlGrpWghtAvll : 12|2@1+ (1,0) [0|3] "" Vector__XXX
 SG_ TrlrCAxlGrpWghtAvll : 14|2@1+ (1,0) [0|3] "" Vector__XXX
 SG_ TrlrDAxlGrpWghtAvll : 16|2@1+ (1,0) [0|3] "" Vector__XXX
 SG_ TrlrEAxlGrpWghtAvll : 18|2@1+ (1,0) [0|3] "" Vector__XXX
 SG_ TrlrFAxlGrpWghtAvll : 20|2@1+ (1,0) [0|3] "" Vector__XXX
 SG_ TrlrGAxlGrpWghtAvll : 22|2@1+ (1,0) [0|3] "" Vector__XXX
 SG_ TrlrHAxlGrpWghtAvll : 24|2@1+ (1,0) [0|3] "" Vector__XXX
 SG_ SlOrFrwrdMstStrAxlGrpWghtAvll : 0|2@1+ (1,0) [0|3] "" Vector__XXX
 SG_ SlOrFrwrdMstDrvAxlGrpWghtAvll : 4|2@1+ (1,0) [0|3] "" Vector__XXX

BO_ 2566745342 AT2AC2: 8 Vector__XXX
 SG_ Aftrtrtmnt2SndrArDffrntlPrssr : 0|16@1+ (0.0078125,-250) [-250|251.9921875] "kPa" Vector__XXX
 SG_ Aftrtrtmnt2SndrArMssFlwRt : 32|16@1+ (0.2,0) [0|12851] "kg/h" Vector__XXX
 SG_ Aftrtrtmnt2SndrArPrssr : 48|16@1+ (0.1,0) [0|6425.5] "kPa" Vector__XXX
 SG_ Aftrtrtmnt2SndrArTmprtr : 16|16@1+ (0.03125,-273) [-273|1734.96875] "degC" Vector__XXX

BO_ 2566745598 AT1AC2: 8 Vector__XXX
 SG_ Aftrtrtmnt1SndrArDffrntlPrssr : 0|16@1+ (0.0078125,-250) [-250|251.9921875] "kPa" Vector__XXX
 SG_ Aftrtrtmnt1SndrArMssFlwRt : 32|16@1+ (0.2,0) [0|12851] "kg/h" Vector__XXX
 SG_ Aftrtrtmnt1SndrArPrssr : 48|16@1+ (0.1,0) [0|6425.5] "kPa" Vector__XXX
 SG_ Aftrtrtmnt1SndrArTmprtr : 16|16@1+ (0.03125,-273) [-273|1734.96875] "degC" Vector__XXX

BO_ 2566745854 A1SCRSI1: 8 Vector__XXX
 SG_ Atttt1DsExstFdAvCspt : 0|16@1+ (0.05,0) [0|3212.75] "l/h" Vector__XXX
 SG_ Atttt1SCddDsExstFdCspt : 16|16@1+ (0.05,0) [0|3212.75] "l/h" Vector__XXX
 SG_ Aftrtrtmnt1SrCnvrsnEffn : 32|8@1+ (0.4,0) [0|100] "%" Vector__XXX
 SG_ AttttSOptIdtAtvTvdDst : 40|16@1+ (1,0) [0|64255] "km" Vector__XXX
 SG_ Aftrtrtmnt1SrSstmSlftnLvl : 56|8@1+ (1,0) [0|250] "%" Vector__XXX

BO_ 2566746110 EEC8: 8 Vector__XXX
 SG_ EExstGsRt1CItAstPss : 32|16@1+ (0.5,0) [0|32127.5] "kPa" Vector__XXX
 SG_ EngnExhstGsRrltn1ClrEffn : 48|8@1+ (0.4,0) [0|100] "%" Vector__XXX
 SG_ EngnExhstGsRrltn1ClrIntkTmprtr : 16|16@1+ (0.03125,-273) [-273|1734.96875] "degC" Vector__XXX
 SG_ EngnExhstGsRrltn1Vlv2Cntrl : 0|16@1+ (0.0025,0) [0|160.6375] "%" Vector__XXX
 SG_ EExstGsRtAtItCtTpt : 56|8@1+ (1,-40) [-40|210] "degC" Vector__XXX

BO_ 2566746366 DRC: 8 Vector__XXX
 SG_ EnableStatusOfRamp1 : 2|2@1+ (1,0) [0|3] "" Vector__XXX
 SG_ EnableStatusOfRamp2 : 10|2@1+ (1,0) [0|3] "" Vector__XXX
 SG_ EnableStatusOfRamp3 : 18|2@1+ (1,0) [0|3] "" Vector__XXX
 SG_ EnableStatusOfRamp4 : 26|2@1+ (1,0) [0|3] "" Vector__XXX
 SG_ EnableStatusOfRamp5 : 34|2@1+ (1,0) [0|3] "" Vector__XXX
 SG_ MovementStatusOfRamp1 : 4|2@1+ (1,0) [0|3] "" Vector__XXX
 SG_ MovementStatusOfRamp2 : 12|2@1+ (1,0) [0|3] "" Vector__XXX
 SG_ MovementStatusOfRamp3 : 20|2@1+ (1,0) [0|3] "" Vector__XXX
 SG_ MovementStatusOfRamp4 : 28|2@1+ (1,0) [0|3] "" Vector__XXX
 SG_ MovementStatusOfRamp5 : 36|2@1+ (1,0) [0|3] "" Vector__XXX
 SG_ RetractStatusOfRamp1 : 0|2@1+ (1,0) [0|3] "" Vector__XXX
 SG_ RetractStatusOfRamp2 : 8|2@1+ (1,0) [0|3] "" Vector__XXX
 SG_ RetractStatusOfRamp3 : 16|2@1+ (1,0) [0|3] "" Vector__XXX
 SG_ RetractStatusOfRamp4 : 24|2@1+ (1,0) [0|3] "" Vector__XXX
 SG_ RetractStatusOfRamp5 : 32|2@1+ (1,0) [0|3] "" Vector__XXX

BO_ 2566746622 BSA: 8 Vector__XXX
 SG_ TractorBrakeStrokeAxle1Left : 0|3@1+ (1,0) [0|7] "" Vector__XXX
 SG_ TractorBrakeStrokeAxle1Right : 3|3@1+ (1,0) [0|7] "" Vector__XXX
 SG_ TractorBrakeStrokeAxle2Left : 6|3@1+ (1,0) [0|7] "" Vector__XXX
 SG_ TractorBrakeStrokeAxle2Right : 9|3@1+ (1,0) [0|7] "" Vector__XXX
 SG_ TractorBrakeStrokeAxle3Left : 12|3@1+ (1,0) [0|7] "" Vector__XXX
 SG_ TractorBrakeStrokeAxle3Right : 15|3@1+ (1,0) [0|7] "" Vector__XXX
 SG_ TractorBrakeStrokeAxle4Left : 18|3@1+ (1,0) [0|7] "" Vector__XXX
 SG_ TractorBrakeStrokeAxle4Right : 21|3@1+ (1,0) [0|7] "" Vector__XXX
 SG_ TractorBrakeStrokeAxle5Left : 24|3@1+ (1,0) [0|7] "" Vector__XXX
 SG_ TractorBrakeStrokeAxle5Right : 27|3@1+ (1,0) [0|7] "" Vector__XXX
 SG_ TrailerBrakeStrokeAxle1Left : 30|3@1+ (1,0) [0|7] "" Vector__XXX
 SG_ TrailerBrakeStrokeAxle1Right : 33|3@1+ (1,0) [0|7] "" Vector__XXX
 SG_ TrailerBrakeStrokeAxle2Left : 36|3@1+ (1,0) [0|7] "" Vector__XXX
 SG_ TrailerBrakeStrokeAxle2Right : 39|3@1+ (1,0) [0|7] "" Vector__XXX
 SG_ TrailerBrakeStrokeAxle3Left : 42|3@1+ (1,0) [0|7] "" Vector__XXX
 SG_ TrailerBrakeStrokeAxle3Right : 45|3@1+ (1,0) [0|7] "" Vector__XXX
 SG_ TrailerBrakeStrokeAxle4Left : 48|3@1+ (1,0) [0|7] "" Vector__XXX
 SG_ TrailerBrakeStrokeAxle4Right : 51|3@1+ (1,0) [0|7] "" Vector__XXX
 SG_ TrailerBrakeStrokeAxle5Left : 54|3@1+ (1,0) [0|7] "" Vector__XXX
 SG_ TrailerBrakeStrokeAxle5Right : 57|3@1+ (1,0) [0|7] "" Vector__XXX

BO_ 2566746878 ESV6: 8 Vector__XXX
 SG_ EngineSparkPlug21 : 0|16@1+ (1,0) [0|64255] "V" Vector__XXX
 SG_ EngineSparkPlug22 : 16|16@1+ (1,0) [0|64255] "V" Vector__XXX
 SG_ EngineSparkPlug23 : 32|16@1+ (1,0) [0|64255] "V" Vector__XXX
 SG_ EngineSparkPlug24 : 48|16@1+ (1,0) [0|64255] "V" Vector__XXX

BO_ 2566747134 ESV5: 8 Vector__XXX
 SG_ EngineSparkPlug17 : 0|16@1+ (1,0) [0|64255] "V" Vector__XXX
 SG_ EngineSparkPlug18 : 16|16@1+ (1,0) [0|64255] "V" Vector__XXX
 SG_ EngineSparkPlug19 : 32|16@1+ (1,0) [0|64255] "V" Vector__XXX
 SG_ EngineSparkPlug20 : 48|16@1+ (1,0) [0|64255] "V" Vector__XXX

BO_ 2566747390 ESV4: 8 Vector__XXX
 SG_ EngineSparkPlug13 : 0|16@1+ (1,0) [0|64255] "V" Vector__XXX
 SG_ EngineSparkPlug14 : 16|16@1+ (1,0) [0|64255] "V" Vector__XXX
 SG_ EngineSparkPlug15 : 32|16@1+ (1,0) [0|64255] "V" Vector__XXX
 SG_ EngineSparkPlug16 : 48|16@1+ (1,0) [0|64255] "V" Vector__XXX

BO_ 2566747646 ESV3: 8 Vector__XXX
 SG_ EngineSparkPlug10 : 16|16@1+ (1,0) [0|64255] "V" Vector__XXX
 SG_ EngineSparkPlug11 : 32|16@1+ (1,0) [0|64255] "V" Vector__XXX
 SG_ EngineSparkPlug12 : 48|16@1+ (1,0) [0|64255] "V" Vector__XXX
 SG_ EngineSparkPlug9 : 0|16@1+ (1,0) [0|64255] "V" Vector__XXX

BO_ 2566747902 ESV2: 8 Vector__XXX
 SG_ EngineSparkPlug5 : 0|16@1+ (1,0) [0|64255] "V" Vector__XXX
 SG_ EngineSparkPlug6 : 16|16@1+ (1,0) [0|64255] "V" Vector__XXX
 SG_ EngineSparkPlug7 : 32|16@1+ (1,0) [0|64255] "V" Vector__XXX
 SG_ EngineSparkPlug8 : 48|16@1+ (1,0) [0|64255] "V" Vector__XXX

BO_ 2566748158 ESV1: 8 Vector__XXX
 SG_ EngineSparkPlug1 : 0|16@1+ (1,0) [0|64255] "V" Vector__XXX
 SG_ EngineSparkPlug2 : 16|16@1+ (1,0) [0|64255] "V" Vector__XXX
 SG_ EngineSparkPlug3 : 32|16@1+ (1,0) [0|64255] "V" Vector__XXX
 SG_ EngineSparkPlug4 : 48|16@1+ (1,0) [0|64255] "V" Vector__XXX

BO_ 2566748414 AT2TI: 32 Vector__XXX
 SG_ Aftrtrtmnt2DslPrtltFltrTrpFlUsd : 0|32@1+ (0.5,0) [0|2105540607.5] "l" Vector__XXX
 SG_ Atttt2DsPttFtTpAtvRtT : 32|32@1+ (1,0) [0|4211081215] "s" Vector__XXX
 SG_ Atttt2DsPttFtTpDsdT : 64|32@1+ (1,0) [0|4211081215] "s" Vector__XXX
 SG_ Atttt2DsPttFtTpPssvRtT : 128|32@1+ (1,0) [0|4211081215] "s" Vector__XXX
 SG_ Atttt2DsPttFtTpNOAtvRts : 96|32@1+ (1,0) [0|4211081215] "count" Vector__XXX
 SG_ Atttt2DsPttFtTpNOPssvRts : 160|32@1+ (1,0) [0|4211081215] "count" Vector__XXX
 SG_ Atttt2DsPttFtTpNOAtvRtItRqsts : 192|32@1+ (1,0) [0|4211081215] "count" Vector__XXX
 SG_ Atttt2DsPttFtTpNOAtvRtMRqsts : 224|32@1+ (1,0) [0|4211081215] "count" Vector__XXX

BO_ 2566748670 AT1TI: 32 Vector__XXX
 SG_ Aftrtrtmnt1DslPrtltFltrTrpFlUsd : 0|32@1+ (0.5,0) [0|2105540607.5] "l" Vector__XXX
 SG_ Atttt1DsPttFtTpAtvRtT : 32|32@1+ (1,0) [0|4211081215] "s" Vector__XXX
 SG_ Atttt1DsPttFtTpDsdT : 64|32@1+ (1,0) [0|4211081215] "s" Vector__XXX
 SG_ Atttt1DsPttFtTpPssvRtT : 128|32@1+ (1,0) [0|4211081215] "s" Vector__XXX
 SG_ Atttt1DsPttFtTpNOAtvRts : 96|32@1+ (1,0) [0|4211081215] "count" Vector__XXX
 SG_ Atttt1DsPttFtTpNOPssvRts : 160|32@1+ (1,0) [0|4211081215] "count" Vector__XXX
 SG_ Atttt1DsPttFtTpNOAtvRtItRqsts : 192|32@1+ (1,0) [0|4211081215] "count" Vector__XXX
 SG_ Atttt1DsPttFtTpNOAtvRtMRqsts : 224|32@1+ (1,0) [0|4211081215] "count" Vector__XXX

BO_ 2566748926 AT2S1: 8 Vector__XXX
 SG_ Aftrtrtmnt2DslPrtltFltrStLdPrnt : 0|8@1+ (1,0) [0|250] "%" Vector__XXX
 SG_ Atttt2DsPttFtAsLdPt : 8|8@1+ (1,0) [0|250] "%" Vector__XXX
 SG_ Atttt2DsPttFtStLdRtTsd : 48|16@1+ (0.0025,0) [0|160.6375] "%" Vector__XXX
 SG_ Atttt2DsPttFtTSLstAtvRt : 16|32@1+ (1,0) [0|4211081215] "s" Vector__XXX

BO_ 2566749182 AT1S1: 8 Vector__XXX
 SG_ Aftrtrtmnt1DslPrtltFltrStLdPrnt : 0|8@1+ (1,0) [0|250] "%" Vector__XXX
 SG_ Atttt1DsPttFtAsLdPt : 8|8@1+ (1,0) [0|250] "%" Vector__XXX
 SG_ Atttt1DsPttFtStLdRtTsd : 48|16@1+ (0.0025,0) [0|160.6375] "%" Vector__XXX
 SG_ Atttt1DsPttFtTSLstAtvRt : 16|32@1+ (1,0) [0|4211081215] "s" Vector__XXX

BO_ 2566749438 DPFC1: 8 Vector__XXX
 SG_ AftrtrtmntDslPrtltFltrStts : 12|3@1+ (1,0) [0|7] "" Vector__XXX
 SG_ AttttDsPttFtAtvRtStts : 10|2@1+ (1,0) [0|3] "" Vector__XXX
 SG_ AttttDsPttFtPssvRtStts : 8|2@1+ (1,0) [0|3] "" Vector__XXX
 SG_ DslPrtltFltrAtvRgnrtnAvlltStts : 3|2@1+ (1,0) [0|3] "" Vector__XXX
 SG_ DslPrtltFltrAtvRgnrtnFrdStts : 53|3@1+ (1,0) [0|7] "" Vector__XXX
 SG_ DslPrtltFltrAtvRgnrtnInhtdStts : 16|2@1+ (1,0) [0|3] "" Vector__XXX
 SG_ DslPrtltFltrLmpCmmnd : 0|3@1+ (1,0) [0|7] "" Vector__XXX
 SG_ DsPttFtAttAtvRtIttCt : 48|2@1+ (1,0) [0|3] "" Vector__XXX
 SG_ DsPttFtAtvRtItdDTAtPdOId : 26|2@1+ (1,0) [0|3] "" Vector__XXX
 SG_ DsPttFtAtvRtItdDTCtDsd : 20|2@1+ (1,0) [0|3] "" Vector__XXX
 SG_ DsPttFtAtvRtItdDTENtWdUp : 44|2@1+ (1,0) [0|3] "" Vector__XXX
 SG_ DsPttFtAtvRtItdDTItSwt : 18|2@1+ (1,0) [0|3] "" Vector__XXX
 SG_ DsPttFtAtvRtItdDTLwExstPss : 58|2@1+ (1,0) [0|3] "" Vector__XXX
 SG_ DsPttFtAtvRtItdDTLwExstTpt : 34|2@1+ (1,0) [0|3] "" Vector__XXX
 SG_ DsPttFtAtvRtItdDTPBNtSt : 32|2@1+ (1,0) [0|3] "" Vector__XXX
 SG_ DsPttFtAtvRtItdDTPtSstLt : 42|2@1+ (1,0) [0|3] "" Vector__XXX
 SG_ DsPttFtAtvRtItdDTSstFtAtv : 36|2@1+ (1,0) [0|3] "" Vector__XXX
 SG_ DsPttFtAtvRtItdDTSstTt : 38|2@1+ (1,0) [0|3] "" Vector__XXX
 SG_ DsPttFtAtvRtItdDTSvBAtv : 22|2@1+ (1,0) [0|3] "" Vector__XXX
 SG_ DsPttFtAtvRtItdDTTpSstLt : 40|2@1+ (1,0) [0|3] "" Vector__XXX
 SG_ DsPttFtAtvRtItdDTVSpdAvAwdSpd : 30|2@1+ (1,0) [0|3] "" Vector__XXX
 SG_ DsPttFtAtvRtItdDTVSpdBwAwdSpd : 46|2@1+ (1,0) [0|3] "" Vector__XXX
 SG_ ExhstSstmHghTmprtrLmpCmmnd : 50|3@1+ (1,0) [0|7] "" Vector__XXX
 SG_ HydrocarbonDoserPurgingEnable : 56|2@1+ (1,0) [0|3] "" Vector__XXX
 SG_ DsPttFtAtvRtItdDTTs : 62|2@1+ (1,0) [0|3] "" Vector__XXX
 SG_ DsPttFtAtvRtItdDTPtAtv : 24|2@1+ (1,0) [0|3] "" Vector__XXX
 SG_ DsPttFtAtvRtItdDTOtONt : 28|2@1+ (1,0) [0|3] "" Vector__XXX
 SG_ Atttt1DsPttFtCdtsNtMtFAtvRt : 60|2@1+ (1,0) [0|3] "" Vector__XXX

BO_ 2566749950 AFSS: 8 Vector__XXX
 SG_ LeftHeadlampDynamicBendingLight : 0|3@1+ (1,0) [0|7] "" Vector__XXX
 SG_ LeftHeadlampLightDistribution : 8|4@1+ (1,0) [0|15] "" Vector__XXX
 SG_ RghtHdlmpDnmBndngLght : 3|3@1+ (1,0) [0|7] "" Vector__XXX
 SG_ RightHeadlampLightDistribution : 12|4@1+ (1,0) [0|15] "" Vector__XXX

BO_ 2566750206 EC2: 8 Vector__XXX
 SG_ EngnCnfgrtnIdntftn : 16|16@1+ (1,0) [0|64255] "ID" Vector__XXX
 SG_ MxmmCrnkAttmptsPrStrtAttmpt : 0|8@1+ (1,0) [0|250] "count" Vector__XXX
 SG_ TrnsmssnIdlGvrnrFlngInhtSpprt : 32|2@1+ (1,0) [0|3] "" Vector__XXX
 SG_ NmrOfCmstnClsFrAvrgng : 8|8@1+ (1,0) [1|250] "count" Vector__XXX

BO_ 2566751230 TCI: 8 Vector__XXX
 SG_ TransferCaseActualGearRatio : 8|16@1+ (0.01,0) [0|642.55] "" Vector__XXX
 SG_ TransferCaseDirectionStatus : 3|2@1+ (1,0) [0|3] "" Vector__XXX
 SG_ TransferCaseMessageChecksum : 60|4@1+ (1,0) [0|15] "count" Vector__XXX
 SG_ TransferCaseMessageCounter : 56|4@1+ (1,0) [0|7] "count" Vector__XXX
 SG_ TransferCaseStatus : 0|3@1+ (1,0) [0|7] "" Vector__XXX

BO_ 2566751486 EFLP9: 8 Vector__XXX
 SG_ EngnIntkVlvAttnOlPrssrFrClndr17 : 0|16@1+ (0.1,0) [0|6425.5] "kPa" Vector__XXX
 SG_ EngnIntkVlvAttnOlPrssrFrClndr18 : 16|16@1+ (0.1,0) [0|6425.5] "kPa" Vector__XXX
 SG_ EngnIntkVlvAttnOlPrssrFrClndr19 : 32|16@1+ (0.1,0) [0|6425.5] "kPa" Vector__XXX
 SG_ EngnIntkVlvAttnOlPrssrFrClndr20 : 48|16@1+ (0.1,0) [0|6425.5] "kPa" Vector__XXX

BO_ 2566751742 EFLP8: 8 Vector__XXX
 SG_ EngnIntkVlvAttnOlPrssrFrClndr13 : 0|16@1+ (0.1,0) [0|6425.5] "kPa" Vector__XXX
 SG_ EngnIntkVlvAttnOlPrssrFrClndr14 : 16|16@1+ (0.1,0) [0|6425.5] "kPa" Vector__XXX
 SG_ EngnIntkVlvAttnOlPrssrFrClndr15 : 32|16@1+ (0.1,0) [0|6425.5] "kPa" Vector__XXX
 SG_ EngnIntkVlvAttnOlPrssrFrClndr16 : 48|16@1+ (0.1,0) [0|6425.5] "kPa" Vector__XXX

BO_ 2566751998 EFLP7: 8 Vector__XXX
 SG_ EngnIntkVlvAttnOlPrssrFrClndr10 : 16|16@1+ (0.1,0) [0|6425.5] "kPa" Vector__XXX
 SG_ EngnIntkVlvAttnOlPrssrFrClndr11 : 32|16@1+ (0.1,0) [0|6425.5] "kPa" Vector__XXX
 SG_ EngnIntkVlvAttnOlPrssrFrClndr12 : 48|16@1+ (0.1,0) [0|6425.5] "kPa" Vector__XXX
 SG_ EngnIntkVlvAttnOlPrssrFrClndr9 : 0|16@1+ (0.1,0) [0|6425.5] "kPa" Vector__XXX

BO_ 2566752254 EFLP6: 8 Vector__XXX
 SG_ EngnIntkVlvAttnOlPrssrFrClndr5 : 0|16@1+ (0.1,0) [0|6425.5] "kPa" Vector__XXX
 SG_ EngnIntkVlvAttnOlPrssrFrClndr6 : 16|16@1+ (0.1,0) [0|6425.5] "kPa" Vector__XXX
 SG_ EngnIntkVlvAttnOlPrssrFrClndr7 : 32|16@1+ (0.1,0) [0|6425.5] "kPa" Vector__XXX
 SG_ EngnIntkVlvAttnOlPrssrFrClndr8 : 48|16@1+ (0.1,0) [0|6425.5] "kPa" Vector__XXX

BO_ 2566752510 EFLP5: 8 Vector__XXX
 SG_ EngnIntkVlvAttnOlPrssrFrClndr1 : 0|16@1+ (0.1,0) [0|6425.5] "kPa" Vector__XXX
 SG_ EngnIntkVlvAttnOlPrssrFrClndr2 : 16|16@1+ (0.1,0) [0|6425.5] "kPa" Vector__XXX
 SG_ EngnIntkVlvAttnOlPrssrFrClndr3 : 32|16@1+ (0.1,0) [0|6425.5] "kPa" Vector__XXX
 SG_ EngnIntkVlvAttnOlPrssrFrClndr4 : 48|16@1+ (0.1,0) [0|6425.5] "kPa" Vector__XXX

BO_ 2566752766 VDS2: 8 Vector__XXX
 SG_ VehicleRoll : 0|16@1+ (0.0078125,-200) [-90|90] "deg" Vector__XXX

BO_ 2566753278 AT2GP: 8 Vector__XXX
 SG_ Atttt2DsPttFtItPss : 0|16@1+ (0.1,0) [0|6425.5] "kPa" Vector__XXX
 SG_ Atttt2DsPttFtOttPss : 16|16@1+ (0.1,0) [0|6425.5] "kPa" Vector__XXX

BO_ 2566753534 AT1GP: 8 Vector__XXX
 SG_ Atttt1DsPttFtItPss : 0|16@1+ (0.1,0) [0|6425.5] "kPa" Vector__XXX
 SG_ Atttt1DsPttFtOttPss : 16|16@1+ (0.1,0) [0|6425.5] "kPa" Vector__XXX

BO_ 2566753790 UTACER: 8 Vector__XXX
 SG_ UtilityTotalKvarHoursExport : 0|32@1+ (1,0) [0|4211081215] "kVArh" Vector__XXX
 SG_ UtilityTotalKvarHoursImport : 32|32@1+ (1,0) [0|4211081215] "kVArh" Vector__XXX

BO_ 2566754046 GTACER: 8 Vector__XXX
 SG_ GeneratorTotalKvarHoursExport : 0|32@1+ (1,0) [0|4211081215] "kVArh" Vector__XXX
 SG_ GeneratorTotalKvarHoursImport : 32|32@1+ (1,0) [0|4211081215] "kVArh" Vector__XXX

BO_ 2566754302 GTACPP: 8 Vector__XXX
 SG_ GeneratorTotalPercentKva : 16|16@1+ (0.0078125,-251) [-251|250.9921875] "%" Vector__XXX
 SG_ GeneratorTotalPercentKvar : 32|16@1+ (0.0078125,-251) [-251|250.9921875] "%" Vector__XXX
 SG_ GeneratorTotalPercentKw : 0|16@1+ (0.0078125,-251) [-251|250.9921875] "%" Vector__XXX

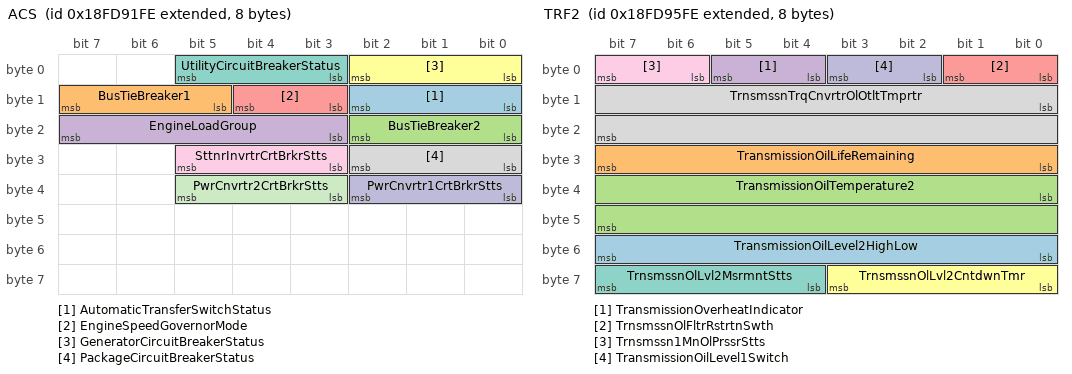
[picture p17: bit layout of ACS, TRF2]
BO_ 2566754814 ACS: 8 Vector__XXX
 SG_ AutomaticTransferSwitchStatus : 8|3@1+ (1,0) [0|7] "" Vector__XXX
 SG_ BusTieBreaker1 : 13|3@1+ (1,0) [0|7] "" Vector__XXX
 SG_ BusTieBreaker2 : 16|3@1+ (1,0) [0|7] "" Vector__XXX
 SG_ EngineLoadGroup : 19|5@1+ (1,0) [0|31] "count" Vector__XXX
 SG_ EngineSpeedGovernorMode : 11|2@1+ (1,0) [0|3] "" Vector__XXX
 SG_ GeneratorCircuitBreakerStatus : 0|3@1+ (1,0) [0|7] "" Vector__XXX
 SG_ UtilityCircuitBreakerStatus : 3|3@1+ (1,0) [0|7] "" Vector__XXX
 SG_ PackageCircuitBreakerStatus : 24|3@1+ (1,0) [0|7] "" Vector__XXX
 SG_ SttnrInvrtrCrtBrkrStts : 27|3@1+ (1,0) [0|7] "" Vector__XXX
 SG_ PwrCnvrtr1CrtBrkrStts : 32|3@1+ (1,0) [0|7] "" Vector__XXX
 SG_ PwrCnvrtr2CrtBrkrStts : 35|3@1+ (1,0) [0|7] "" Vector__XXX

BO_ 2566755582 EEC7: 8 Vector__XXX
 SG_ EngnCrnksBrthrOlSprtrSpd : 32|16@1+ (1,0) [0|64255] "rpm" Vector__XXX
 SG_ EngnExhstGsRrltn1Vlv2Pstn : 16|16@1+ (0.0025,0) [0|160.6375] "%" Vector__XXX
 SG_ EngnExhstGsRrltn1VlvPstn : 0|16@1+ (0.0025,0) [0|160.6375] "%" Vector__XXX
 SG_ EngnIntkMnfldCmmnddPrssr : 48|16@1+ (0.125,0) [0|8031.875] "kPa" Vector__XXX

BO_ 2566755838 TRF2: 8 Vector__XXX
 SG_ TransmissionOilLevel2HighLow : 48|8@1+ (0.5,-62.5) [-62.5|62.5] "l" Vector__XXX
 SG_ TransmissionOilLifeRemaining : 24|8@1+ (0.4,0) [0|100] "%" Vector__XXX
 SG_ TransmissionOilTemperature2 : 32|16@1+ (0.03125,-273) [-273|1734.96875] "degC" Vector__XXX
 SG_ TransmissionOverheatIndicator : 4|2@1+ (1,0) [0|3] "" Vector__XXX
 SG_ TrnsmssnOlFltrRstrtnSwth : 0|2@1+ (1,0) [0|3] "" Vector__XXX
 SG_ TrnsmssnOlLvl2CntdwnTmr : 56|4@1+ (1,0) [0|13] "" Vector__XXX
 SG_ TrnsmssnOlLvl2MsrmntStts : 60|4@1+ (1,0) [0|15] "" Vector__XXX
 SG_ TrnsmssnTrqCnvrtrOlOtltTmprtr : 8|16@1+ (0.03125,-273) [-273|1734.96875] "degC" Vector__XXX
 SG_ Trnsmssn1MnOlPrssrStts : 6|2@1+ (1,0) [0|3] "" Vector__XXX
 SG_ TransmissionOilLevel1Switch : 2|2@1+ (1,0) [0|3] "" Vector__XXX

BO_ 2566756094 LFI2: 8 Vector__XXX
 SG_ EngineFuelReturnFlowRate : 32|32@1+ (0.001,0) [0|4211081.215] "l/h" Vector__XXX
 SG_ EngineFuelSupplyFlowRate : 0|32@1+ (0.001,0) [0|4211081.215] "l/h" Vector__XXX

BO_ 2566756350 LFI3: 8 Vector__XXX
 SG_ EngineFuelReturnTemperature : 8|8@1+ (1,-40) [-40|210] "degC" Vector__XXX
 SG_ EngineFuelSupplyTemperature : 0|8@1+ (1,-40) [-40|210] "degC" Vector__XXX

BO_ 2566756606 AT1HI1: 44 Vector__XXX
 SG_ Aftertreatment1TotalFuelUsed : 0|32@1+ (0.5,0) [0|2105540607.5] "l" Vector__XXX
 SG_ Aftrtrtmnt1TtlDsldTm : 64|32@1+ (1,0) [0|4211081215] "s" Vector__XXX
 SG_ Aftrtrtmnt1TtlRgnrtnTm : 32|32@1+ (1,0) [0|4211081215] "s" Vector__XXX
 SG_ Atttt1DsPttFtAvDstBtwAtvRts : 288|32@1+ (0.125,0) [0|526385151.875] "km" Vector__XXX
 SG_ Atttt1DsPttFtAvTBtwAtvRts : 256|32@1+ (1,0) [0|4211081215] "s" Vector__XXX
 SG_ Atttt1DsPttFtTtPssvRtT : 128|32@1+ (1,0) [0|4211081215] "s" Vector__XXX
 SG_ Aftrtrtmnt1TtlNmrOfAtvRgnrtns : 96|32@1+ (1,0) [0|4211081215] "count" Vector__XXX
 SG_ Atttt1DsPttFtTtNOPssvRts : 160|32@1+ (1,0) [0|4211081215] "count" Vector__XXX
 SG_ Atttt1DsPttFtTtNOAtvRtItRqsts : 192|32@1+ (1,0) [0|4211081215] "count" Vector__XXX
 SG_ Atttt1DsPttFtTtNOAtvRtMRqsts : 224|32@1+ (1,0) [0|4211081215] "count" Vector__XXX
 SG_ Atttt1DsPttFtNOAtvRts : 320|32@1+ (1,0) [0|4211081215] "count" Vector__XXX

BO_ 2566756862 AT2HI1: 44 Vector__XXX
 SG_ Aftertreatment2TotalFuelUsed : 0|32@1+ (0.5,0) [0|2105540607.5] "l" Vector__XXX
 SG_ Aftrtrtmnt2TtlDsldTm : 64|32@1+ (1,0) [0|4211081215] "s" Vector__XXX
 SG_ Aftrtrtmnt2TtlRgnrtnTm : 32|32@1+ (1,0) [0|4211081215] "s" Vector__XXX
 SG_ Atttt2DsPttFtAvDstBtwAtvRts : 288|32@1+ (0.125,0) [0|526385151.875] "km" Vector__XXX
 SG_ Atttt2DsPttFtAvTBtwAtvRts : 256|32@1+ (1,0) [0|4211081215] "s" Vector__XXX
 SG_ Atttt2DsPttFtTtPssvRtT : 128|32@1+ (1,0) [0|4211081215] "s" Vector__XXX
 SG_ Aftrtrtmnt2TtlNmrOfAtvRgnrtns : 96|32@1+ (1,0) [0|4211081215] "count" Vector__XXX
 SG_ Atttt2DsPttFtTtNOPssvRts : 160|32@1+ (1,0) [0|4211081215] "count" Vector__XXX
 SG_ Atttt2DsPttFtTtNOAtvRtItRqsts : 192|32@1+ (1,0) [0|4211081215] "count" Vector__XXX
 SG_ Atttt2DsPttFtTtNOAtvRtMRqsts : 224|32@1+ (1,0) [0|4211081215] "count" Vector__XXX
 SG_ Atttt2DsPttFtNOAtvRts : 320|32@1+ (1,0) [0|4211081215] "count" Vector__XXX

BO_ 2566757374 A1DEFI1: 8 Vector__XXX
 SG_ Aftrtrtmnt1DslExhstFldCndtvt : 16|8@1+ (5,0) [0|1250] "muSiemens/mm" Vector__XXX
 SG_ Aftrtrtmnt1DslExhstFldCnntrtn : 8|8@1+ (0.25,0) [0|62.5] "%" Vector__XXX
 SG_ Aftrtrtmnt1DslExhstFldPrprt : 40|4@1+ (1,0) [0|15] "" Vector__XXX
 SG_ Aftrtrtmnt1DslExhstFldTmprtr2 : 0|8@1+ (1,-40) [-40|210] "degC" Vector__XXX
 SG_ DieselExhaustFluidSpeedOfSound : 48|16@1+ (0.1,0) [0|6425.5] "m/s" Vector__XXX
 SG_ Atttt1DsExstFdTpt2PF : 24|5@1+ (1,0) [0|31] "" Vector__XXX
 SG_ Atttt1DsExstFdPptsPF : 32|5@1+ (1,0) [0|31] "" Vector__XXX

BO_ 2566757630 SEP2: 8 Vector__XXX
 SG_ SensorSupplyVoltage5 : 0|16@1+ (0.05,0) [0|3212.75] "V" Vector__XXX
 SG_ SensorSupplyVoltage6 : 16|16@1+ (0.05,0) [0|3212.75] "V" Vector__XXX
 SG_ SensorSupplyVoltage7 : 32|16@1+ (0.05,0) [0|3212.75] "V" Vector__XXX
 SG_ SensorSupplyVoltage8 : 48|16@1+ (0.05,0) [0|3212.75] "V" Vector__XXX

BO_ 2566757886 SEP1: 8 Vector__XXX
 SG_ SensorSupplyVoltage1 : 0|16@1+ (0.05,0) [0|3212.75] "V" Vector__XXX
 SG_ SensorSupplyVoltage2 : 16|16@1+ (0.05,0) [0|3212.75] "V" Vector__XXX
 SG_ SensorSupplyVoltage3 : 32|16@1+ (0.05,0) [0|3212.75] "V" Vector__XXX
 SG_ SensorSupplyVoltage4 : 48|16@1+ (0.05,0) [0|3212.75] "V" Vector__XXX

BO_ 2566758142 AT2AC1: 8 Vector__XXX
 SG_ Aftertreatment2AirSystemRelay : 56|2@1+ (1,0) [0|3] "" Vector__XXX
 SG_ Aftertreatment2PurgeAirActuator : 60|2@1+ (1,0) [0|3] "" Vector__XXX
 SG_ Aftertreatment2PurgeAirPressure : 16|16@1+ (0.1,0) [0|6425.5] "kPa" Vector__XXX
 SG_ Aftrtrtmnt2ArEnlAttr : 62|2@1+ (1,0) [0|3] "" Vector__XXX
 SG_ Aftrtrtmnt2ArPrssrAttrPstn : 48|8@1+ (0.4,0) [0|100] "%" Vector__XXX
 SG_ Aftrtrtmnt2ArPrssrCntrl : 32|16@1+ (0.0025,0) [0|160.6375] "%" Vector__XXX
 SG_ Aftrtrtmnt2AtmztnArAttr : 58|2@1+ (1,0) [0|3] "" Vector__XXX
 SG_ Aftrtrtmnt2SpplArPrssr : 0|16@1+ (0.1,0) [0|6425.5] "kPa" Vector__XXX

BO_ 2566758398 AT1AC1: 8 Vector__XXX
 SG_ Aftertreatment1AirSystemRelay : 56|2@1+ (1,0) [0|3] "" Vector__XXX
 SG_ Aftertreatment1PurgeAirActuator : 60|2@1+ (1,0) [0|3] "" Vector__XXX
 SG_ Aftertreatment1PurgeAirPressure : 16|16@1+ (0.1,0) [0|6425.5] "kPa" Vector__XXX
 SG_ Aftrtrtmnt1ArEnlAttr : 62|2@1+ (1,0) [0|3] "" Vector__XXX
 SG_ Aftrtrtmnt1ArPrssrAttrPstn : 48|8@1+ (0.4,0) [0|100] "%" Vector__XXX
 SG_ Aftrtrtmnt1ArPrssrCntrl : 32|16@1+ (0.0025,0) [0|160.6375] "%" Vector__XXX
 SG_ Aftrtrtmnt1AtmztnArAttr : 58|2@1+ (1,0) [0|3] "" Vector__XXX
 SG_ Aftrtrtmnt1SpplArPrssr : 0|16@1+ (0.1,0) [0|6425.5] "kPa" Vector__XXX

BO_ 2566758654 AT2FC1: 8 Vector__XXX
 SG_ Aftertreatment2FuelPressure1 : 0|16@1+ (0.1,0) [0|6425.5] "kPa" Vector__XXX
 SG_ Aftertreatment2FuelRate : 16|16@1+ (0.05,0) [0|3212.75] "l/h" Vector__XXX
 SG_ Aftertreatment2Ignition : 50|2@1+ (1,0) [0|3] "" Vector__XXX
 SG_ Aftrtrtmnt2FlDrnAttr : 48|2@1+ (1,0) [0|3] "" Vector__XXX
 SG_ Aftrtrtmnt2FlEnlAttr : 54|2@1+ (1,0) [0|3] "" Vector__XXX
 SG_ Aftrtrtmnt2FlInjtr1HtrCntrl : 56|8@1+ (0.4,0) [0|100] "%" Vector__XXX
 SG_ Aftrtrtmnt2FlPrssr1Cntrl : 32|16@1+ (0.0025,0) [0|160.6375] "%" Vector__XXX
 SG_ Aftrtrtmnt2RgnrtnStts : 52|2@1+ (1,0) [0|3] "" Vector__XXX

BO_ 2566758910 AT1FC1: 8 Vector__XXX
 SG_ Aftertreatment1FuelPressure1 : 0|16@1+ (0.1,0) [0|6425.5] "kPa" Vector__XXX
 SG_ Aftertreatment1FuelRate : 16|16@1+ (0.05,0) [0|3212.75] "l/h" Vector__XXX
 SG_ Aftertreatment1Ignition : 50|2@1+ (1,0) [0|3] "" Vector__XXX
 SG_ Aftrtrtmnt1FlDrnAttr : 48|2@1+ (1,0) [0|3] "" Vector__XXX
 SG_ Aftrtrtmnt1FlEnlAttr : 54|2@1+ (1,0) [0|3] "" Vector__XXX
 SG_ Aftrtrtmnt1FlInjtr1HtrCntrl : 56|8@1+ (0.4,0) [0|100] "%" Vector__XXX
 SG_ Aftrtrtmnt1FlPrssr1Cntrl : 32|16@1+ (0.0025,0) [0|160.6375] "%" Vector__XXX
 SG_ Aftrtrtmnt1RgnrtnStts : 52|2@1+ (1,0) [0|3] "" Vector__XXX

BO_ 2566759678 PTODE1: 8 Vector__XXX
 SG_ AtLeastOnePtoEngaged : 48|2@1+ (1,0) [0|3] "" Vector__XXX
 SG_ EnableSwitchPtoEngineFlywheel : 8|2@1+ (1,0) [0|3] "" Vector__XXX
 SG_ PtoMessageCounter : 56|4@1+ (1,0) [0|7] "count" Vector__XXX
 SG_ PtoMessageChecksum : 60|4@1+ (1,0) [0|15] "count" Vector__XXX
 SG_ EnlSwthTrnsfrCsOtptShftPt : 0|2@1+ (1,0) [0|3] "" Vector__XXX
 SG_ EnlSwthTrnsmssnOtptShftPt : 2|2@1+ (1,0) [0|3] "" Vector__XXX
 SG_ EnlSwthTrnsmssnInptShftPt2 : 4|2@1+ (1,0) [0|3] "" Vector__XXX
 SG_ EnlSwthTrnsmssnInptShftPt1 : 6|2@1+ (1,0) [0|3] "" Vector__XXX
 SG_ EnlSwthPtEngnAssrDrv1 : 10|2@1+ (1,0) [0|3] "" Vector__XXX
 SG_ EnlSwthPtEngnAssrDrv2 : 12|2@1+ (1,0) [0|3] "" Vector__XXX
 SG_ EnggmntCnsntTrnsfrCsOtptShftPt : 16|2@1+ (1,0) [0|3] "" Vector__XXX
 SG_ EnggmntCnsntTrnsmssnOtptShftPt : 18|2@1+ (1,0) [0|3] "" Vector__XXX
 SG_ EnggmntCnsntTrnsmssnInptShftPt2 : 20|2@1+ (1,0) [0|3] "" Vector__XXX
 SG_ EnggmntCnsntTrnsmssnInptShftPt1 : 22|2@1+ (1,0) [0|3] "" Vector__XXX
 SG_ EnggmntCnsntPtEngnFlwhl : 24|2@1+ (1,0) [0|3] "" Vector__XXX
 SG_ EnggmntCnsntPtEngnAssrDrv1 : 26|2@1+ (1,0) [0|3] "" Vector__XXX
 SG_ EnggmntCnsntPtEngnAssrDrv2 : 28|2@1+ (1,0) [0|3] "" Vector__XXX
 SG_ EnggmntSttsTrnsfrCsOtptShftPt : 32|2@1+ (1,0) [0|3] "" Vector__XXX
 SG_ EnggmntSttsTrnsmssnOtptShftPt : 34|2@1+ (1,0) [0|3] "" Vector__XXX
 SG_ EnggmntSttsTrnsmssnInptShftPt2 : 36|2@1+ (1,0) [0|3] "" Vector__XXX
 SG_ EnggmntSttsTrnsmssnInptShftPt1 : 38|2@1+ (1,0) [0|3] "" Vector__XXX
 SG_ EnggmntSttsPtEngnFlwhl : 40|2@1+ (1,0) [0|3] "" Vector__XXX
 SG_ EnggmntSttsPtEngnAssrDrv1 : 42|2@1+ (1,0) [0|3] "" Vector__XXX
 SG_ EnggmntSttsPtEngnAssrDrv2 : 44|2@1+ (1,0) [0|3] "" Vector__XXX
 SG_ OprtnCnsntTrnsfrCsOtptShftPt : 46|2@1+ (1,0) [0|3] "" Vector__XXX
 SG_ OprtnCnsntTrnsmssnInptShftPt1 : 50|2@1+ (1,0) [0|3] "" Vector__XXX
 SG_ OprtnCnsntTrnsmssnInptShftPt2 : 52|2@1+ (1,0) [0|3] "" Vector__XXX
 SG_ OprtnCnsntTrnsmssnOtptShftPt : 54|2@1+ (1,0) [0|3] "" Vector__XXX

BO_ 2566759934 DC2: 8 Vector__XXX
 SG_ EnableStatusOfDoor1 : 4|2@1+ (1,0) [0|3] "" Vector__XXX
 SG_ EnableStatusOfDoor10 : 58|2@1+ (1,0) [0|3] "" Vector__XXX
 SG_ EnableStatusOfDoor2 : 10|2@1+ (1,0) [0|3] "" Vector__XXX
 SG_ EnableStatusOfDoor3 : 16|2@1+ (1,0) [0|3] "" Vector__XXX
 SG_ EnableStatusOfDoor4 : 22|2@1+ (1,0) [0|3] "" Vector__XXX
 SG_ EnableStatusOfDoor5 : 28|2@1+ (1,0) [0|3] "" Vector__XXX
 SG_ EnableStatusOfDoor6 : 34|2@1+ (1,0) [0|3] "" Vector__XXX
 SG_ EnableStatusOfDoor7 : 40|2@1+ (1,0) [0|3] "" Vector__XXX
 SG_ EnableStatusOfDoor8 : 46|2@1+ (1,0) [0|3] "" Vector__XXX
 SG_ EnableStatusOfDoor9 : 52|2@1+ (1,0) [0|3] "" Vector__XXX
 SG_ LockStatusOfDoor1 : 0|2@1+ (1,0) [0|3] "" Vector__XXX
 SG_ LockStatusOfDoor10 : 54|2@1+ (1,0) [0|3] "" Vector__XXX
 SG_ LockStatusOfDoor2 : 6|2@1+ (1,0) [0|3] "" Vector__XXX
 SG_ LockStatusOfDoor3 : 12|2@1+ (1,0) [0|3] "" Vector__XXX
 SG_ LockStatusOfDoor4 : 18|2@1+ (1,0) [0|3] "" Vector__XXX
 SG_ LockStatusOfDoor5 : 24|2@1+ (1,0) [0|3] "" Vector__XXX
 SG_ LockStatusOfDoor6 : 30|2@1+ (1,0) [0|3] "" Vector__XXX
 SG_ LockStatusOfDoor7 : 36|2@1+ (1,0) [0|3] "" Vector__XXX
 SG_ LockStatusOfDoor8 : 42|2@1+ (1,0) [0|3] "" Vector__XXX
 SG_ LockStatusOfDoor9 : 48|2@1+ (1,0) [0|3] "" Vector__XXX
 SG_ OpenStatusOfDoor1 : 2|2@1+ (1,0) [0|3] "" Vector__XXX
 SG_ OpenStatusOfDoor10 : 56|2@1+ (1,0) [0|3] "" Vector__XXX
 SG_ OpenStatusOfDoor2 : 8|2@1+ (1,0) [0|3] "" Vector__XXX
 SG_ OpenStatusOfDoor3 : 14|2@1+ (1,0) [0|3] "" Vector__XXX
 SG_ OpenStatusOfDoor4 : 20|2@1+ (1,0) [0|3] "" Vector__XXX
 SG_ OpenStatusOfDoor5 : 26|2@1+ (1,0) [0|3] "" Vector__XXX
 SG_ OpenStatusOfDoor6 : 32|2@1+ (1,0) [0|3] "" Vector__XXX
 SG_ OpenStatusOfDoor7 : 38|2@1+ (1,0) [0|3] "" Vector__XXX
 SG_ OpenStatusOfDoor8 : 44|2@1+ (1,0) [0|3] "" Vector__XXX
 SG_ OpenStatusOfDoor9 : 50|2@1+ (1,0) [0|3] "" Vector__XXX

BO_ 2566760702 WCM2: 8 Vector__XXX
 SG_ NetworkAntennaStatus2 : 16|8@1+ (1,0) [0|250] "" Vector__XXX
 SG_ NetworkServiceStatus2 : 8|8@1+ (1,0) [0|250] "" Vector__XXX
 SG_ NetworkSignalStrength2 : 24|8@1+ (0.4,0) [0|100] "%" Vector__XXX
 SG_ NetworkTransceiverStatus2 : 0|8@1+ (1,0) [0|250] "" Vector__XXX
 SG_ WrlssCmmntnNtwrkTp2 : 32|8@1+ (1,0) [0|250] "" Vector__XXX

BO_ 2566760958 WCM1: 8 Vector__XXX
 SG_ NetworkAntennaStatus1 : 16|8@1+ (1,0) [0|250] "" Vector__XXX
 SG_ NetworkServiceStatus1 : 8|8@1+ (1,0) [0|250] "" Vector__XXX
 SG_ NetworkSignalStrength1 : 24|8@1+ (0.4,0) [0|100] "%" Vector__XXX
 SG_ NetworkTransceiverStatus1 : 0|8@1+ (1,0) [0|250] "" Vector__XXX
 SG_ WrlssCmmntnNtwrkTp1 : 32|8@1+ (1,0) [0|250] "" Vector__XXX

BO_ 2566761214 EFLP4: 8 Vector__XXX
 SG_ EngineAftercoolerCoolantLevel : 48|8@1+ (0.4,0) [0|100] "%" Vector__XXX
 SG_ EngineCentrifugalOilFilterSpeed : 24|16@1+ (4,0) [0|257020] "rpm" Vector__XXX
 SG_ EngnChrgArClr1IntkPrssr : 0|8@1+ (2,0) [0|500] "kPa" Vector__XXX
 SG_ EngnChrgArClr2IntkPrssr : 8|8@1+ (2,0) [0|500] "kPa" Vector__XXX
 SG_ EngnChrgArClrClntLvl : 40|8@1+ (0.4,0) [0|100] "%" Vector__XXX
 SG_ EngnClntPmpDffrntlPrssr : 16|8@1+ (1.64,-7) [-7|403] "kPa" Vector__XXX
 SG_ EngnChrgArClr1OtltPrssr : 56|8@1+ (2,0) [0|500] "kPa" Vector__XXX

BO_ 2566761726 EFI: 8 Vector__XXX
 SG_ EngineIdleFuelFlowRateThreshold : 8|32@1+ (0.001,0) [0|4211081.215] "l/h" Vector__XXX
 SG_ NmrOfFlCnsmptnMntrngTrnsdrs : 0|8@1+ (1,0) [0|250] "count" Vector__XXX

BO_ 2566762238 FWSS2: 8 Vector__XXX
 SG_ FfthWhlLkCplSttsIndtr : 6|2@1+ (1,0) [0|3] "" Vector__XXX
 SG_ FfthWhlLkRdTCplIndtr : 4|2@1+ (1,0) [0|3] "" Vector__XXX
 SG_ FifthWheelErrorStatus : 0|4@1+ (1,0) [0|15] "" Vector__XXX
 SG_ FifthWheelSliderLockIndicator : 16|2@1+ (1,0) [0|3] "" Vector__XXX
 SG_ FifthWheelSliderPosition : 8|8@1+ (10,0) [0|2500] "mm" Vector__XXX

BO_ 2566762494 AT2IMG: 8 Vector__XXX
 SG_ Aftrtrtmnt2ExhstTmprtr2 : 0|16@1+ (0.03125,-273) [-273|1734.96875] "degC" Vector__XXX
 SG_ Atttt2DsPttFtDtPss : 32|16@1+ (0.1,0) [0|6425.5] "kPa" Vector__XXX
 SG_ Atttt2DsPttFtItdtTpt : 16|16@1+ (0.03125,-273) [-273|1734.96875] "degC" Vector__XXX
 SG_ Aftrtrtmnt2ExhstTmprtr2PrlmnrFm : 48|5@1+ (1,0) [0|31] "" Vector__XXX
 SG_ Atttt2DsPttFtDtPssPF : 53|5@1+ (1,0) [0|31] "" Vector__XXX
 SG_ Atttt2DsPttFtItdtTptPF : 58|5@1+ (1,0) [0|31] "" Vector__XXX

BO_ 2566762750 AT2OG2: 8 Vector__XXX
 SG_ Aftrtrtmnt2ExhstTmprtr3 : 0|16@1+ (0.03125,-273) [-273|1734.96875] "degC" Vector__XXX
 SG_ Atttt2DsPttFtOttTpt : 16|16@1+ (0.03125,-273) [-273|1734.96875] "degC" Vector__XXX
 SG_ Aftrtrtmnt2ExhstTmprtr3PrlmnrFm : 32|5@1+ (1,0) [0|31] "" Vector__XXX
 SG_ Atttt2DsPttFtExstTptPF : 40|5@1+ (1,0) [0|31] "" Vector__XXX

BO_ 2566763006 AT2IG2: 8 Vector__XXX
 SG_ Aftrtrtmnt2ExhstTmprtr1 : 0|16@1+ (0.03125,-273) [-273|1734.96875] "degC" Vector__XXX
 SG_ Atttt2DsPttFtItTpt : 16|16@1+ (0.03125,-273) [-273|1734.96875] "degC" Vector__XXX
 SG_ Aftrtrtmnt2ExhstTmprtr1PrlmnrFm : 32|5@1+ (1,0) [0|31] "" Vector__XXX
 SG_ Atttt2DsPttFtItTptPF : 40|5@1+ (1,0) [0|31] "" Vector__XXX

BO_ 2566763262 AT1IMG: 8 Vector__XXX
 SG_ Aftrtrtmnt1ExhstTmprtr2 : 0|16@1+ (0.03125,-273) [-273|1734.96875] "degC" Vector__XXX
 SG_ Atttt1DsPttFtDtPss : 32|16@1+ (0.1,0) [0|6425.5] "kPa" Vector__XXX
 SG_ Atttt1DsPttFtItdtTpt : 16|16@1+ (0.03125,-273) [-273|1734.96875] "degC" Vector__XXX
 SG_ Aftrtrtmnt1ExhstTmprtr2PrlmnrFm : 48|5@1+ (1,0) [0|31] "" Vector__XXX
 SG_ Atttt1DsPttFtDtPssPF : 53|5@1+ (1,0) [0|31] "" Vector__XXX
 SG_ Atttt1DsPttFtItdtTptPF : 58|5@1+ (1,0) [0|31] "" Vector__XXX

BO_ 2566763518 AT1OG2: 8 Vector__XXX
 SG_ Aftrtrtmnt1ExhstTmprtr3 : 0|16@1+ (0.03125,-273) [-273|1734.96875] "degC" Vector__XXX
 SG_ Atttt1DsPttFtOttTpt : 16|16@1+ (0.03125,-273) [-273|1734.96875] "degC" Vector__XXX
 SG_ Aftrtrtmnt1ExhstTmprtr3PrlmnrFm : 32|5@1+ (1,0) [0|31] "" Vector__XXX
 SG_ Atttt1DsPttFtOttExstTptPF : 40|5@1+ (1,0) [0|31] "" Vector__XXX

BO_ 2566763774 AT1IG2: 8 Vector__XXX
 SG_ Aftrtrtmnt1ExhstTmprtr1 : 0|16@1+ (0.03125,-273) [-273|1734.96875] "degC" Vector__XXX
 SG_ Atttt1DsPttFtItTpt : 16|16@1+ (0.03125,-273) [-273|1734.96875] "degC" Vector__XXX
 SG_ Aftrtrtmnt1ExhstTmprtr1PrlmnrFm : 32|5@1+ (1,0) [0|31] "" Vector__XXX
 SG_ Atttt1DsPttFtItTptPF : 40|5@1+ (1,0) [0|31] "" Vector__XXX

BO_ 2566765054 TPRI: 8 Vector__XXX
 SG_ ReferenceTirePressure : 8|8@1+ (8,0) [0|2000] "kPa" Vector__XXX
 SG_ TireLocation : 0|8@1+ (1,0) [0|250] "" Vector__XXX

BO_ 2566765310 TR6: 8 Vector__XXX
 SG_ FareboxAlarmIdentifier : 8|7@1+ (1,0) [0|127] "" Vector__XXX
 SG_ FareboxEmergencyStatus : 0|2@1+ (1,0) [0|3] "" Vector__XXX

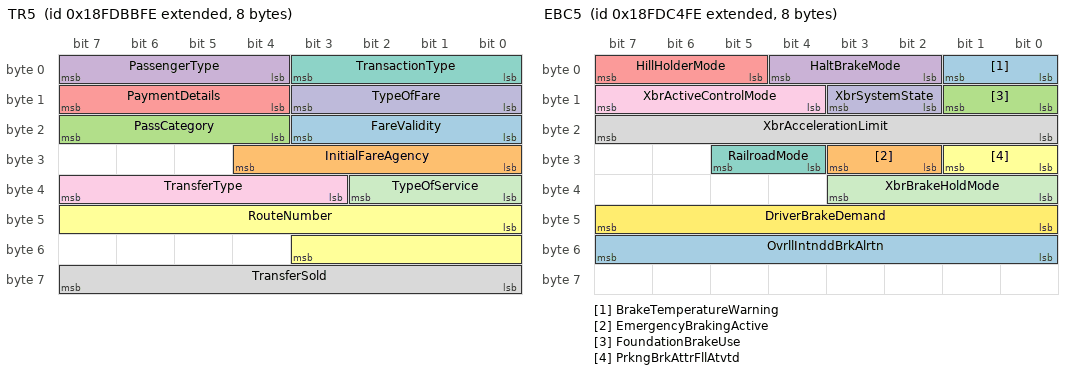
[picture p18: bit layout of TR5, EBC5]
BO_ 2566765566 TR5: 8 Vector__XXX
 SG_ FareValidity : 16|4@1+ (1,0) [0|15] "count" Vector__XXX
 SG_ InitialFareAgency : 24|5@1+ (1,0) [1|31] "count" Vector__XXX
 SG_ PassCategory : 20|4@1+ (1,0) [0|15] "count" Vector__XXX
 SG_ PassengerType : 4|4@1+ (1,0) [0|15] "" Vector__XXX
 SG_ PaymentDetails : 12|4@1+ (1,0) [0|15] "" Vector__XXX
 SG_ RouteNumber : 40|12@1+ (1,0) [0|4015] "count" Vector__XXX
 SG_ TransactionType : 0|4@1+ (1,0) [0|15] "" Vector__XXX
 SG_ TransferSold : 56|8@1+ (1,0) [0|250] "count" Vector__XXX
 SG_ TransferType : 35|5@1+ (1,0) [0|31] "" Vector__XXX
 SG_ TypeOfFare : 8|4@1+ (1,0) [0|15] "" Vector__XXX
 SG_ TypeOfService : 32|3@1+ (1,0) [0|7] "" Vector__XXX

BO_ 2566765822 TR4: 15 Vector__XXX
 SG_ AssignedBlock : 88|16@1+ (1,0) [0|64255] "count" Vector__XXX
 SG_ AssignedRoute : 56|16@1+ (1,0) [0|64255] "count" Vector__XXX
 SG_ AssignedRun : 72|16@1+ (1,0) [0|64255] "count" Vector__XXX
 SG_ DriverSFareboxSecurityCode : 104|16@1+ (1,0) [0|64255] "count" Vector__XXX
 SG_ FareboxServiceStatus : 0|2@1+ (1,0) [0|3] "" Vector__XXX
 SG_ FarePresets : 16|8@1+ (1,0) [0|250] "" Vector__XXX
 SG_ PatternNumber : 40|16@1+ (1,0) [0|64255] "count" Vector__XXX
 SG_ TripDirection : 8|4@1+ (1,0) [0|15] "" Vector__XXX
 SG_ TripNumber : 24|16@1+ (1,0) [0|64255] "count" Vector__XXX
 SG_ TripStatus : 2|3@1+ (1,0) [0|7] "" Vector__XXX

BO_ 2566766078 TR3: 8 Vector__XXX
 SG_ IntrstnPrmptnRqstRspns : 6|2@1+ (1,0) [0|3] "" Vector__XXX
 SG_ PriorityOfResponseSentByEmitter : 8|4@1+ (1,0) [0|15] "" Vector__XXX
 SG_ RangeCodeEnable : 2|2@1+ (1,0) [0|3] "" Vector__XXX
 SG_ StrobeActivationControlStatus : 14|2@1+ (1,0) [0|3] "" Vector__XXX
 SG_ TransitDoorEnable : 12|2@1+ (1,0) [0|3] "" Vector__XXX
 SG_ TransitRouteIdUsage : 4|2@1+ (1,0) [0|3] "" Vector__XXX
 SG_ VehicleId : 16|16@1+ (1,0) [0|65534] "count" Vector__XXX

BO_ 2566766334 TR1: 4 Vector__XXX
 SG_ Agency : 0|8@1+ (1,0) [0|250] "count" Vector__XXX
 SG_ NmrOfBtsInThTrnstAssgndRtIdntt : 8|8@1+ (1,0) [1|100] "byte" Vector__XXX
 SG_ NmrOfBtsInThTrnstAssgndRnIdntt : 16|8@1+ (1,0) [1|100] "byte" Vector__XXX
 SG_ NmrOfBtsInThTrnstAssgndBlkIdntt : 24|8@1+ (1,0) [1|100] "byte" Vector__XXX

BO_ 2566766590 TR2: 8 Vector__XXX
 SG_ NmrOfBtsInThMlpstIdntftn : 0|8@1+ (1,0) [0|100] "byte" Vector__XXX

BO_ 2566766846 TR7: 8 Vector__XXX
 SG_ PatronCount : 8|8@1+ (1,0) [0|250] "count" Vector__XXX
 SG_ SilentAlarmStatus : 16|2@1+ (1,0) [0|3] "" Vector__XXX
 SG_ TransitRunStatus : 20|2@1+ (1,0) [0|3] "" Vector__XXX
 SG_ TypeOfPassengerCount : 0|8@1+ (1,0) [0|250] "" Vector__XXX
 SG_ VehicleUseStatus : 18|2@1+ (1,0) [0|3] "" Vector__XXX

BO_ 2566767102 EFLP3: 8 Vector__XXX
 SG_ EngnExhstGsRrltn1IntkPrssr : 16|8@1+ (2,0) [0|500] "kPa" Vector__XXX
 SG_ EngnExhstGsRrltn1OtltPrssr : 40|8@1+ (2,0) [0|500] "kPa" Vector__XXX
 SG_ EngnExhstVlvAttnSstmOlPrssr : 24|16@1+ (0.00390625,0) [0|250.99609375] "MPa" Vector__XXX
 SG_ EngnIntkVlvAttnSstmOlPrssr : 0|16@1+ (0.00390625,0) [0|250.99609375] "MPa" Vector__XXX
 SG_ EngnThrttlVlv1DffrntlPrssr : 48|16@1+ (0.1,0) [0|6425.5] "kPa" Vector__XXX

BO_ 2566767358 EEC14: 8 Vector__XXX
 SG_ EngineFuelIsolationControl : 56|2@1+ (1,0) [0|3] "" Vector__XXX
 SG_ EngineFuelMassFlowRate : 32|16@1+ (0.005,0) [0|321.275] "g/s" Vector__XXX
 SG_ EngnExhstGsRrltn1Vlv1PstnErrr : 0|16@1+ (0.004,-125) [-125|132.02] "%" Vector__XXX
 SG_ EngnExhstGsRrltn1Vlv2PstnErrr : 16|16@1+ (0.004,-125) [-125|132.02] "%" Vector__XXX
 SG_ FuelType : 48|8@1+ (1,0) [0|250] "" Vector__XXX

BO_ 2566767614 EEC15: 8 Vector__XXX
 SG_ AcceleratorPedal1Channel2 : 0|8@1+ (0.4,0) [0|100] "%" Vector__XXX
 SG_ AcceleratorPedal1Channel3 : 8|8@1+ (0.4,0) [0|100] "%" Vector__XXX
 SG_ AcceleratorPedal2Channel2 : 16|8@1+ (0.4,0) [0|100] "%" Vector__XXX
 SG_ AcceleratorPedal2Channel3 : 24|8@1+ (0.4,0) [0|100] "%" Vector__XXX
 SG_ EngnExhstGsRstrtnVlvCntrl : 32|16@1+ (0.0025,0) [0|160.6375] "%" Vector__XXX

BO_ 2566767870 EBC5: 8 Vector__XXX
 SG_ BrakeTemperatureWarning : 0|2@1+ (1,0) [0|3] "" Vector__XXX
 SG_ EmergencyBrakingActive : 26|2@1+ (1,0) [0|3] "" Vector__XXX
 SG_ FoundationBrakeUse : 8|2@1+ (1,0) [0|3] "" Vector__XXX
 SG_ HaltBrakeMode : 2|3@1+ (1,0) [0|7] "" Vector__XXX
 SG_ HillHolderMode : 5|3@1+ (1,0) [0|7] "" Vector__XXX
 SG_ PrkngBrkAttrFllAtvtd : 24|2@1+ (1,0) [0|3] "" Vector__XXX
 SG_ RailroadMode : 28|2@1+ (1,0) [0|3] "" Vector__XXX
 SG_ XbrAccelerationLimit : 16|8@1+ (0.1,-12.5) [-10|10] "m/(s*s)" Vector__XXX
 SG_ XbrActiveControlMode : 12|4@1+ (1,0) [0|15] "" Vector__XXX
 SG_ XbrSystemState : 10|2@1+ (1,0) [0|3] "" Vector__XXX
 SG_ XbrBrakeHoldMode : 32|4@1+ (1,0) [0|15] "" Vector__XXX
 SG_ DriverBrakeDemand : 40|8@1+ (0.1,-12.5) [-12.5|12.5] "m/(s*s)" Vector__XXX
 SG_ OvrllIntnddBrkAlrtn : 48|8@1+ (0.1,-12.5) [-12.5|12.5] "m/(s*s)" Vector__XXX

BO_ 2566768382 CSA: 8 Vector__XXX
 SG_ EngineColdStartFuelIgniterRelay : 24|2@1+ (1,0) [0|3] "" Vector__XXX
 SG_ EngineStartEnableDevice1 : 0|2@1+ (1,0) [0|3] "" Vector__XXX
 SG_ EngineStartEnableDevice2 : 2|2@1+ (1,0) [0|3] "" Vector__XXX
 SG_ EngnCldStrtFlIgntrCmmnd : 16|8@1+ (0.4,0) [0|100] "%" Vector__XXX
 SG_ EngnCldStrtFlIgntrRlFdk : 26|2@1+ (1,0) [0|3] "" Vector__XXX
 SG_ EngnStrtEnlDv1Cnfgrtn : 8|4@1+ (1,0) [0|15] "" Vector__XXX
 SG_ EngnStrtEnlDv2Cnfgrtn : 12|4@1+ (1,0) [0|15] "" Vector__XXX

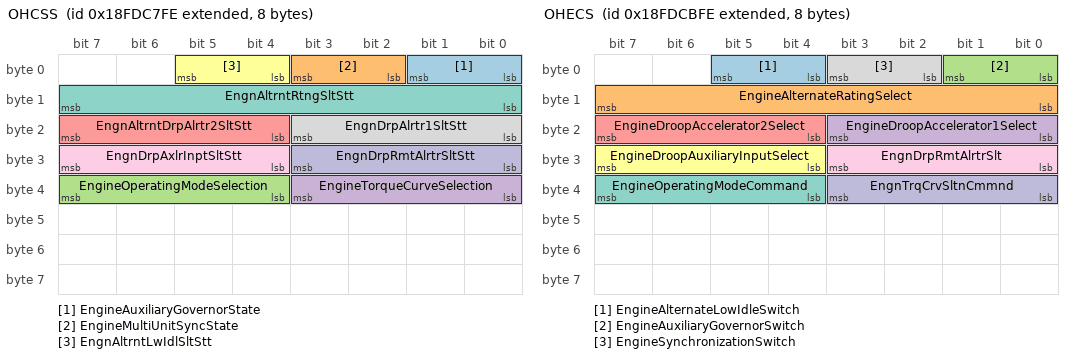
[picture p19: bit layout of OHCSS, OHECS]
BO_ 2566768638 OHCSS: 8 Vector__XXX
 SG_ EngineAuxiliaryGovernorState : 0|2@1+ (1,0) [0|3] "" Vector__XXX
 SG_ EngineMultiUnitSyncState : 2|2@1+ (1,0) [0|3] "" Vector__XXX
 SG_ EngineOperatingModeSelection : 36|4@1+ (1,0) [0|15] "" Vector__XXX
 SG_ EngineTorqueCurveSelection : 32|4@1+ (1,0) [0|15] "" Vector__XXX
 SG_ EngnAltrntDrpAlrtr2SltStt : 20|4@1+ (1,0) [0|15] "" Vector__XXX
 SG_ EngnAltrntLwIdlSltStt : 4|2@1+ (1,0) [0|3] "" Vector__XXX
 SG_ EngnAltrntRtngSltStt : 8|8@1+ (1,0) [0|250] "" Vector__XXX
 SG_ EngnDrpAlrtr1SltStt : 16|4@1+ (1,0) [0|15] "" Vector__XXX
 SG_ EngnDrpAxlrInptSltStt : 28|4@1+ (1,0) [0|15] "" Vector__XXX
 SG_ EngnDrpRmtAlrtrSltStt : 24|4@1+ (1,0) [0|15] "" Vector__XXX

BO_ 2566768894 ISCS: 8 Vector__XXX
 SG_ EngnOprtrPrmrIntrmdtSpdSltStt : 0|4@1+ (1,0) [0|15] "" Vector__XXX

BO_ 2566769406 ISC: 8 Vector__XXX
 SG_ EngnOprtrPrmrIntrmdtSpdSlt : 0|4@1+ (1,0) [0|15] "" Vector__XXX

BO_ 2566769662 OHECS: 8 Vector__XXX
 SG_ EngineAlternateLowIdleSwitch : 4|2@1+ (1,0) [0|3] "" Vector__XXX
 SG_ EngineAlternateRatingSelect : 8|8@1+ (1,0) [0|250] "selection" Vector__XXX
 SG_ EngineAuxiliaryGovernorSwitch : 0|2@1+ (1,0) [0|3] "" Vector__XXX
 SG_ EngineDroopAccelerator1Select : 16|4@1+ (1,0) [0|15] "" Vector__XXX
 SG_ EngineDroopAccelerator2Select : 20|4@1+ (1,0) [0|15] "" Vector__XXX
 SG_ EngineDroopAuxiliaryInputSelect : 28|4@1+ (1,0) [0|15] "" Vector__XXX
 SG_ EngineOperatingModeCommand : 36|4@1+ (1,0) [0|15] "" Vector__XXX
 SG_ EngineSynchronizationSwitch : 2|2@1+ (1,0) [0|3] "" Vector__XXX
 SG_ EngnDrpRmtAlrtrSlt : 24|4@1+ (1,0) [0|15] "" Vector__XXX
 SG_ EngnTrqCrvSltnCmmnd : 32|4@1+ (1,0) [0|15] "" Vector__XXX

BO_ 2566770174 OWW: 8 Vector__XXX
 SG_ FrontNonOperatorWasherSwitch : 42|3@1+ (1,0) [0|7] "" Vector__XXX
 SG_ FrontNonOperatorWiperSwitch : 0|4@1+ (1,0) [0|15] "" Vector__XXX
 SG_ FrontOperatorWasherSwitch : 45|3@1+ (1,0) [0|7] "" Vector__XXX
 SG_ FrontOperatorWiperDelayControl : 16|8@1+ (0.4,0) [0|100] "%" Vector__XXX
 SG_ FrontOperatorWiperSwitch : 4|4@1+ (1,0) [0|15] "" Vector__XXX
 SG_ RearWasherFunction : 53|3@1+ (1,0) [0|7] "" Vector__XXX
 SG_ RearWiperDelayControl : 32|8@1+ (0.4,0) [0|100] "%" Vector__XXX
 SG_ RearWiperSwitch : 12|4@1+ (1,0) [0|15] "" Vector__XXX
 SG_ FrntNnOprtrWprDlCntrl : 24|8@1+ (0.4,0) [0|100] "%" Vector__XXX

BO_ 2566770942 IC2: 8 Vector__XXX
 SG_ EngineIntakeManifold2Pressure : 24|8@1+ (2,0) [0|500] "kPa" Vector__XXX
 SG_ EngnArFltr2DffrntlPrssr : 0|8@1+ (0.05,0) [0|12.5] "kPa" Vector__XXX
 SG_ EngnArFltr3DffrntlPrssr : 8|8@1+ (0.05,0) [0|12.5] "kPa" Vector__XXX
 SG_ EngnArFltr4DffrntlPrssr : 16|8@1+ (0.05,0) [0|12.5] "kPa" Vector__XXX
 SG_ EngnIntkMnfld1AsltPrssr : 32|8@1+ (2,0) [0|500] "kPa" Vector__XXX
 SG_ EngnIntkMnfld1AsltPrssrHghRsltn : 40|16@1+ (0.1,0) [0|6425.5] "kPa" Vector__XXX
 SG_ EngnIntkMnfld2AsltPrssr : 56|8@1+ (2,0) [0|500] "kPa" Vector__XXX

BO_ 2566771454 EP: 8 Vector__XXX
 SG_ DataMemoryUsage : 16|8@1+ (0.4,0) [0|100] "%" Vector__XXX
 SG_ KeepAliveBatteryConsumption : 0|16@1+ (1,0) [0|64255] "mAh" Vector__XXX

BO_ 2566771710 TCI6: 8 Vector__XXX
 SG_ EngnTrhrgr1CmprssrOtltTmprtr : 0|16@1+ (0.03125,-273) [-273|1734.96875] "degC" Vector__XXX
 SG_ EngnTrhrgr2CmprssrOtltTmprtr : 16|16@1+ (0.03125,-273) [-273|1734.96875] "degC" Vector__XXX
 SG_ EngnTrhrgr3CmprssrOtltTmprtr : 32|16@1+ (0.03125,-273) [-273|1734.96875] "degC" Vector__XXX
 SG_ EngnTrhrgr4CmprssrOtltTmprtr : 48|16@1+ (0.03125,-273) [-273|1734.96875] "degC" Vector__XXX

BO_ 2566771966 CM3: 8 Vector__XXX
 SG_ FfthWhlRlsCntrlSrtLkt : 10|2@1+ (1,0) [0|3] "" Vector__XXX
 SG_ FifthWheelReleaseControl : 8|2@1+ (1,0) [0|3] "" Vector__XXX
 SG_ TransferCaseSelectorSwitch : 0|3@1+ (1,0) [0|7] "" Vector__XXX
 SG_ TransmissionOilLevelRequest : 16|2@1+ (1,0) [0|3] "" Vector__XXX
 SG_ VehicleTrailerStatus : 12|2@1+ (1,0) [0|3] "" Vector__XXX
 SG_ MomentaryOperatorKeySwitch : 6|2@1+ (1,0) [0|3] "" Vector__XXX
 SG_ OperatorKeyDetected : 14|2@1+ (1,0) [0|3] "" Vector__XXX
 SG_ OperatorKeySwitchAccessoryPower : 18|2@1+ (1,0) [0|3] "" Vector__XXX
 SG_ OperatorKeySwitchIgnitionPower : 20|2@1+ (1,0) [0|3] "" Vector__XXX
 SG_ OperatorKeySwitchStart : 22|2@1+ (1,0) [0|3] "" Vector__XXX
 SG_ OprtrKSwthDldBttrOff : 24|2@1+ (1,0) [0|3] "" Vector__XXX
 SG_ HornSwitch : 26|2@1+ (1,0) [0|3] "" Vector__XXX
 SG_ EngineAirShutoffTestSwitch : 28|2@1+ (1,0) [0|3] "" Vector__XXX
 SG_ EngineAirShutoffManualSwitch : 30|2@1+ (1,0) [0|3] "" Vector__XXX
 SG_ AftrtrtmntSrDsngMdCmmnd : 3|3@1+ (1,0) [0|7] "" Vector__XXX
 SG_ OperatorKeySwitchService : 32|2@1+ (1,0) [0|3] "" Vector__XXX
 SG_ OperatorKeySwitchOff : 34|2@1+ (1,0) [0|3] "" Vector__XXX
 SG_ RemoteKeyFobFunctionRequested : 40|5@1+ (1,0) [0|31] "" Vector__XXX

BO_ 2566772222 EEC5: 8 Vector__XXX
 SG_ EngineFuelControlMode : 50|2@1+ (1,0) [0|3] "" Vector__XXX
 SG_ EngnExhstGsRrltn1Vlv1Cntrl1 : 32|16@1+ (0.0025,0) [0|100] "%" Vector__XXX
 SG_ EngnTrhrgr1ClltdTrnIntkTmprtr : 0|16@1+ (0.03125,-273) [-273|1734.96875] "degC" Vector__XXX
 SG_ EngnTrhrgr1ClltdTrnOtltTmprtr : 16|16@1+ (0.03125,-273) [-273|1734.96875] "degC" Vector__XXX
 SG_ EngnVrlGmtrTrhrgr1CntrlMd : 52|2@1+ (1,0) [0|3] "" Vector__XXX
 SG_ EngnVrlGmtrTrhrgrVgt1AttrPstn : 56|8@1+ (0.4,0) [0|100] "%" Vector__XXX
 SG_ EVGtTVtACtStVv : 48|2@1+ (1,0) [0|3] "" Vector__XXX

BO_ 2566774014 MCI: 8 Vector__XXX
 SG_ EngineMarineOperatingModeStatus : 8|3@1+ (1,0) [0|7] "" Vector__XXX
 SG_ EngnThrttlSnhrnztnMdStts : 0|4@1+ (1,0) [0|15] "" Vector__XXX
 SG_ SlowVesselModeStatus : 6|2@1+ (1,0) [0|3] "" Vector__XXX
 SG_ TrollingModeStatus : 4|2@1+ (1,0) [0|3] "" Vector__XXX

BO_ 2566775038 AMB2: 8 Vector__XXX
 SG_ BrmtrAsltPrssrHghRsltn : 48|16@1+ (0.1,0) [0|6425.5] "kPa" Vector__XXX
 SG_ CalculatedAmbientAirTemperature : 32|16@1+ (0.03125,-273) [-273|1734.96875] "degC" Vector__XXX
 SG_ SolarIntensityPercent : 0|8@1+ (0.4,0) [0|100] "%" Vector__XXX
 SG_ SolarSensorMaximum : 8|8@1+ (0.4,0) [0|100] "mW/(cm*cm)" Vector__XXX
 SG_ SpecificHumidity : 16|16@1+ (0.01,0) [0|642.55] "g/kg" Vector__XXX

BO_ 2566775294 CCSI1: 8 Vector__XXX
 SG_ AirConditionerCompressorStatus : 8|2@1+ (1,0) [0|3] "" Vector__XXX
 SG_ CACRfrgrntCmprssrOtltPrssr : 0|8@1+ (16,0) [0|4000] "kPa" Vector__XXX
 SG_ FrntCnBlwrFnSpdStpnt : 16|8@1+ (0.4,0) [0|100] "%" Vector__XXX
 SG_ CabACAutoModeSwitch : 10|2@1+ (1,0) [0|3] "" Vector__XXX
 SG_ CabACMaximumDefrostModeSwitch : 12|2@1+ (1,0) [0|3] "" Vector__XXX
 SG_ CabACRecirculationModeSwitch : 14|2@1+ (1,0) [0|3] "" Vector__XXX
 SG_ ACEvaporatorTemperature : 24|16@1+ (0.03125,-273) [-273|1734.96875] "degC" Vector__XXX
 SG_ CACRfrgrntCmprssrStnPrssr : 40|8@1+ (16,0) [0|4000] "kPa" Vector__XXX
 SG_ CabACAirDistributionModeSwitch : 48|4@1+ (1,0) [0|15] "" Vector__XXX

BO_ 2566775550 SPR: 8 Vector__XXX
 SG_ ArSspnsnSpplPrssrRqst : 40|8@1+ (8,0) [0|2000] "kPa" Vector__XXX
 SG_ AxlrEqpmntSpplPrssrRqst : 32|8@1+ (8,0) [0|2000] "kPa" Vector__XXX
 SG_ PneumaticSupplyPressureRequest : 0|8@1+ (8,0) [0|2000] "kPa" Vector__XXX
 SG_ PwrtrnCrtArSpplPrssrRqst : 48|8@1+ (8,0) [0|2000] "kPa" Vector__XXX
 SG_ SrvBrkArPrssrRqstCrt1 : 16|8@1+ (8,0) [0|2000] "kPa" Vector__XXX
 SG_ SrvBrkArPrssrRqstCrt2 : 24|8@1+ (8,0) [0|2000] "kPa" Vector__XXX
 SG_ PrkngAndOrTrlrArPrssrRqst : 8|8@1+ (8,0) [0|2000] "kPa" Vector__XXX

BO_ 2566775806 EOAC: 8 Vector__XXX
 SG_ TravelVelocityControlPosition : 0|8@1+ (1,-125) [-125|125] "%" Vector__XXX

BO_ 2566776062 EPD: 8 Vector__XXX
 SG_ PayloadCapacityPercentage : 56|8@1+ (1,0) [0|250] "%" Vector__XXX
 SG_ PayloadCarryBackWeight : 40|16@1+ (2,0) [0|128510] "kg" Vector__XXX
 SG_ PayloadPercentage : 0|8@1+ (1,0) [0|250] "%" Vector__XXX
 SG_ PayloadWeight : 8|24@1+ (2,0) [0|32899070] "kg" Vector__XXX
 SG_ PayloadWeightConfidence : 32|8@1+ (0.5,0) [0|100] "%" Vector__XXX

BO_ 2566776318 MVS: 8 Vector__XXX
 SG_ AppliedVehicleSpeedLimit : 56|8@1+ (1,0) [0|250] "km/h" Vector__XXX
 SG_ MaximumVehicleSpeedLimit1 : 0|8@1+ (1,0) [0|250] "km/h" Vector__XXX
 SG_ MaximumVehicleSpeedLimit2 : 8|8@1+ (1,0) [0|250] "km/h" Vector__XXX
 SG_ MaximumVehicleSpeedLimit3 : 16|8@1+ (1,0) [0|250] "km/h" Vector__XXX
 SG_ MaximumVehicleSpeedLimit4 : 24|8@1+ (1,0) [0|250] "km/h" Vector__XXX
 SG_ MaximumVehicleSpeedLimit5 : 32|8@1+ (1,0) [0|250] "km/h" Vector__XXX
 SG_ MaximumVehicleSpeedLimit6 : 40|8@1+ (1,0) [0|250] "km/h" Vector__XXX
 SG_ MaximumVehicleSpeedLimit7 : 48|8@1+ (1,0) [0|250] "km/h" Vector__XXX

BO_ 2566785022 ET: 8 Vector__XXX
 SG_ EngnExhstMnfldBnk1Tmprtr1 : 16|16@1+ (0.03125,-273) [-273|1734.96875] "degC" Vector__XXX
 SG_ EngnExhstMnfldBnk1Tmprtr2 : 48|16@1+ (0.03125,-273) [-273|1734.96875] "degC" Vector__XXX
 SG_ EngnExhstMnfldBnk2Tmprtr1 : 0|16@1+ (0.03125,-273) [-273|1734.96875] "degC" Vector__XXX
 SG_ EngnExhstMnfldBnk2Tmprtr2 : 32|16@1+ (0.03125,-273) [-273|1734.96875] "degC" Vector__XXX

BA_DEF_ BO_  "VFrameFormat" ENUM  "StandardCAN","ExtendedCAN","reserved","J1939PG";
BA_DEF_DEF_  "VFrameFormat" "J1939PG";
